VERSION "created by canmatrix"

NS_ :

BS_:

BU_: Matrix

BO_ 1024 Sync_Message_Output_1: 8 Matrix
 SG_ ImageTimestamp_400h : 0|64@1+ (1,0) [0.0|1.84467e+19] "milliseconds" Vector__XXX

BO_ 1025 Sync_Message_Output_2: 8 Matrix
 SG_ SPITimestamp_401h : 0|64@1+ (1,0) [0.0|1.84467e+19] "milliseconds" Vector__XXX

BO_ 1026 Sync_Message_Output_3: 8 Matrix
 SG_ FrameIndex_402h : 0|32@1+ (1,0) [0.0|4294970000.0] "NA" Vector__XXX
 SG_ CameraID_402h : 32|4@1+ (1,0) [0.0|15.0] "enum" Vector__XXX
 SG_ ProtocolMajorVersion_402h : 36|4@1+ (1,0) [0.0|15.0] "NA" Vector__XXX
 SG_ ProtocolMinorVersion_402h : 40|4@1+ (1,0) [0.0|15.0] "NA" Vector__XXX

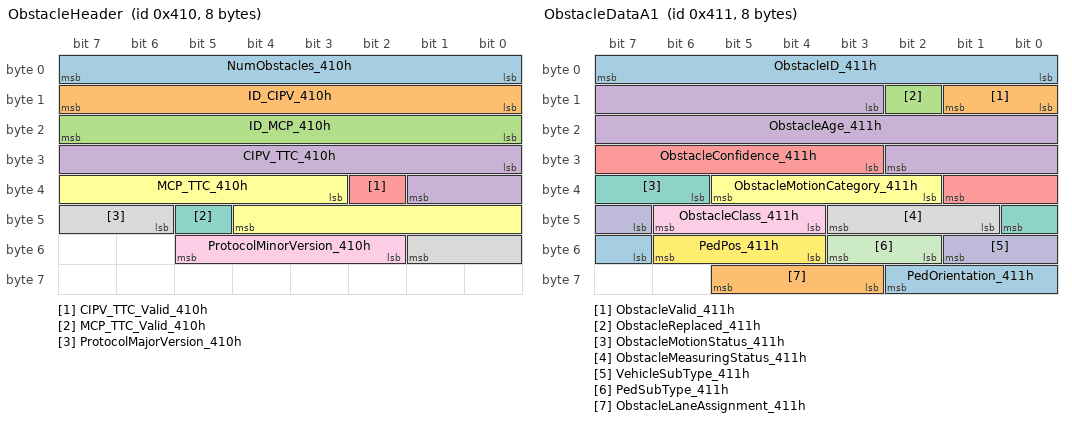
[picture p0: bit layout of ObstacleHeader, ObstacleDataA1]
BO_ 1040 ObstacleHeader: 8 Matrix
 SG_ NumObstacles_410h : 0|8@1+ (1,0) [0.0|20.0] "NA" Vector__XXX
 SG_ ID_CIPV_410h : 8|8@1+ (1,0) [0.0|255.0] "counter" Vector__XXX
 SG_ ID_MCP_410h : 16|8@1+ (1,0) [0.0|255.0] "counter" Vector__XXX
 SG_ CIPV_TTC_410h : 24|10@1+ (0.01,0) [0.0|10.0] "second" Vector__XXX
 SG_ CIPV_TTC_Valid_410h : 34|1@1+ (1,0) [0.0|1.0] "bool" Vector__XXX
 SG_ MCP_TTC_410h : 35|10@1+ (0.01,0) [0.0|10.0] "second" Vector__XXX
 SG_ MCP_TTC_Valid_410h : 45|1@1+ (1,0) [0.0|1.0] "bool" Vector__XXX
 SG_ ProtocolMajorVersion_410h : 46|4@1+ (1,0) [0.0|15.0] "NA" Vector__XXX
 SG_ ProtocolMinorVersion_410h : 50|4@1+ (1,0) [0.0|15.0] "NA" Vector__XXX

BO_ 1041 ObstacleDataA1: 8 Matrix
 SG_ ObstacleID_411h : 0|8@1+ (1,0) [0.0|255.0] "NA" Vector__XXX
 SG_ ObstacleValid_411h : 8|2@1+ (1,0) [0.0|3.0] "bool" Vector__XXX
 SG_ ObstacleReplaced_411h : 10|1@1+ (1,0) [0.0|1.0] "bool" Vector__XXX
 SG_ ObstacleAge_411h : 11|16@1+ (1,0) [0.0|65535.0] "NA" Vector__XXX
 SG_ ObstacleConfidence_411h : 27|7@1+ (1,0) [0.0|100.0] "NA" Vector__XXX
 SG_ ObstacleMotionCategory_411h : 34|4@1+ (1,0) [0.0|15.0] "enum" Vector__XXX
 SG_ ObstacleMotionStatus_411h : 38|3@1+ (1,0) [0.0|7.0] "enum" Vector__XXX
 SG_ ObstacleMeasuringStatus_411h : 41|3@1+ (1,0) [0.0|7.0] "enum" Vector__XXX
 SG_ ObstacleClass_411h : 44|3@1+ (1,0) [0.0|7.0] "enum" Vector__XXX
 SG_ VehicleSubType_411h : 47|3@1+ (1,0) [0.0|7.0] "enum" Vector__XXX
 SG_ PedSubType_411h : 50|2@1+ (1,0) [0.0|3.0] "enum" Vector__XXX
 SG_ PedPos_411h : 52|3@1+ (1,0) [0.0|7.0] "enum" Vector__XXX
 SG_ PedOrientation_411h : 55|4@1+ (1,0) [0.0|15.0] "enum" Vector__XXX
 SG_ ObstacleLaneAssignment_411h : 59|3@1+ (1,0) [0.0|7.0] "enum" Vector__XXX

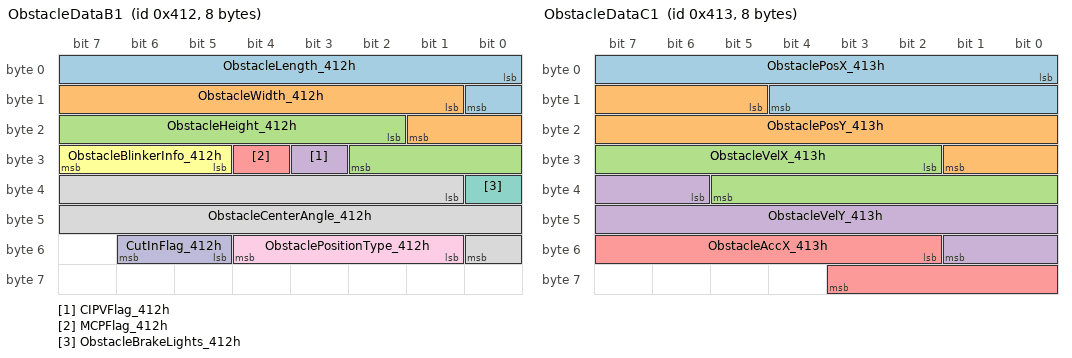
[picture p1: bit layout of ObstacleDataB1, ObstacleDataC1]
BO_ 1042 ObstacleDataB1: 8 Matrix
 SG_ ObstacleLength_412h : 0|9@1+ (0.05,0) [0.0|25.6] "m" Vector__XXX
 SG_ ObstacleWidth_412h : 9|9@1+ (0.02,0) [0.0|10.24] "m" Vector__XXX
 SG_ ObstacleHeight_412h : 18|9@1+ (0.02,0) [0.0|10.24] "m" Vector__XXX
 SG_ CIPVFlag_412h : 27|1@1+ (1,0) [0.0|1.0] "bool" Vector__XXX
 SG_ MCPFlag_412h : 28|1@1+ (1,0) [0.0|1.0] "bool" Vector__XXX
 SG_ ObstacleBlinkerInfo_412h : 29|3@1+ (1,0) [0.0|7.0] "enum" Vector__XXX
 SG_ ObstacleBrakeLights_412h : 32|1@1+ (1,0) [0.0|1.0] "bool" Vector__XXX
 SG_ ObstacleCenterAngle_412h : 33|16@1+ (0.01,-327.68) [-327.68|327.67] "degree" Vector__XXX
 SG_ ObstaclePositionType_412h : 49|4@1+ (1,0) [0.0|15.0] "enum" Vector__XXX
 SG_ CutInFlag_412h : 53|2@1+ (1,0) [0.0|3.0] "bool" Vector__XXX

BO_ 1043 ObstacleDataC1: 8 Matrix
 SG_ ObstaclePosX_413h : 0|13@1+ (0.0625,-250) [-250.0|250.0] "m" Vector__XXX
 SG_ ObstaclePosY_413h : 13|13@1+ (0.0625,-250) [-250.0|250.0] "m" Vector__XXX
 SG_ ObstacleVelX_413h : 26|12@1+ (0.05,-102.4) [-102.4|102.35] "m/sec" Vector__XXX
 SG_ ObstacleVelY_413h : 38|12@1+ (0.05,-50) [-50.0|50.0] "m/sec" Vector__XXX
 SG_ ObstacleAccX_413h : 50|10@1+ (0.03,-14.97) [-14.97|14.97] "m/s^2" Vector__XXX

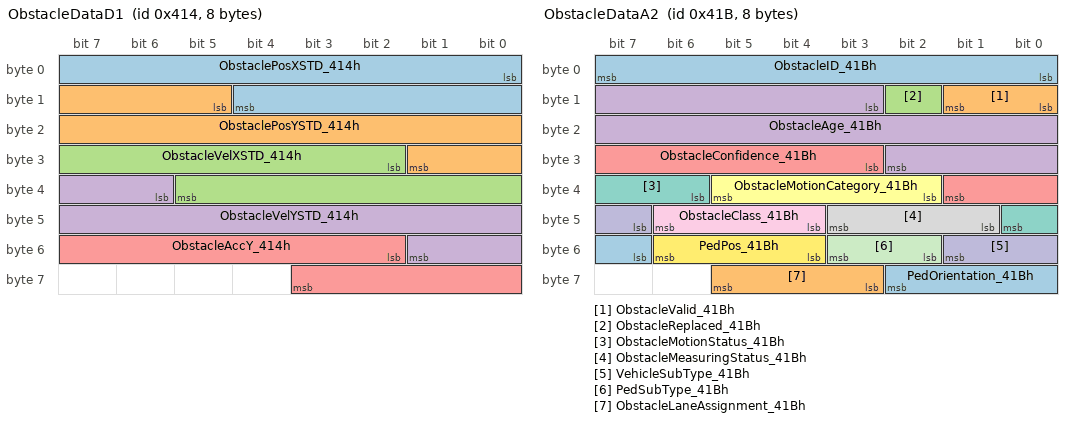
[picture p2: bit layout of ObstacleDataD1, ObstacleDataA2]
BO_ 1044 ObstacleDataD1: 8 Matrix
 SG_ ObstaclePosXSTD_414h : 0|13@1+ (0.0625,0) [0.0|250.0] "m" Vector__XXX
 SG_ ObstaclePosYSTD_414h : 13|13@1+ (0.0625,0) [0.0|250.0] "m" Vector__XXX
 SG_ ObstacleVelXSTD_414h : 26|12@1+ (0.05,0) [0.0|102.35] "m/sec" Vector__XXX
 SG_ ObstacleVelYSTD_414h : 38|12@1+ (0.05,0) [0.0|50.0] "m/sec" Vector__XXX
 SG_ ObstacleAccY_414h : 50|10@1+ (0.03,-14.97) [-14.97|14.97] "m/s^2" Vector__XXX

BO_ 1045 ObstacleDataE1: 8 Matrix
 SG_ ObstacleAngle_415h : 0|16@1+ (0.01,-327.68) [-327.68|327.67] "degree" Vector__XXX
 SG_ ObstacleAngleStd_415h : 16|16@1+ (0.01,0) [0.0|327.67] "degree" Vector__XXX
 SG_ ObstacleVelXAbs_415h : 32|12@1+ (0.05,-102.4) [-102.4|102.35] "m/sec" Vector__XXX
 SG_ ObstacleVelYAbs_415h : 44|12@1+ (0.05,-50) [-50.0|50.0] "m/sec" Vector__XXX

BO_ 1046 ObstacleDataF1: 8 Matrix
 SG_ ObjCornerPointPoxX_416h : 0|13@1+ (0.0625,-250) [-250.0|250.0] "m" Vector__XXX
 SG_ CutInDistance_416h : 13|13@1+ (0.0625,-250) [-250.0|250.0] "m" Vector__XXX
 SG_ ObjCornerPointPoxY_416h : 26|13@1+ (0.0625,-250) [-250.0|250.0] "m" Vector__XXX
 SG_ ObstacleCurvature_416h : 39|15@1+ (1,-9999) [-9999.0|9999.0] "m" Vector__XXX

BO_ 1051 ObstacleDataA2: 8 Matrix
 SG_ ObstacleID_41Bh : 0|8@1+ (1,0) [0.0|255.0] "NA" Vector__XXX
 SG_ ObstacleValid_41Bh : 8|2@1+ (1,0) [0.0|3.0] "bool" Vector__XXX
 SG_ ObstacleReplaced_41Bh : 10|1@1+ (1,0) [0.0|1.0] "bool" Vector__XXX
 SG_ ObstacleAge_41Bh : 11|16@1+ (1,0) [0.0|65535.0] "NA" Vector__XXX
 SG_ ObstacleConfidence_41Bh : 27|7@1+ (1,0) [0.0|100.0] "NA" Vector__XXX
 SG_ ObstacleMotionCategory_41Bh : 34|4@1+ (1,0) [0.0|15.0] "enum" Vector__XXX
 SG_ ObstacleMotionStatus_41Bh : 38|3@1+ (1,0) [0.0|7.0] "enum" Vector__XXX
 SG_ ObstacleMeasuringStatus_41Bh : 41|3@1+ (1,0) [0.0|7.0] "enum" Vector__XXX
 SG_ ObstacleClass_41Bh : 44|3@1+ (1,0) [0.0|7.0] "enum" Vector__XXX
 SG_ VehicleSubType_41Bh : 47|3@1+ (1,0) [0.0|7.0] "enum" Vector__XXX
 SG_ PedSubType_41Bh : 50|2@1+ (1,0) [0.0|3.0] "enum" Vector__XXX
 SG_ PedPos_41Bh : 52|3@1+ (1,0) [0.0|7.0] "enum" Vector__XXX
 SG_ PedOrientation_41Bh : 55|4@1+ (1,0) [0.0|15.0] "enum" Vector__XXX
 SG_ ObstacleLaneAssignment_41Bh : 59|3@1+ (1,0) [0.0|7.0] "enum" Vector__XXX

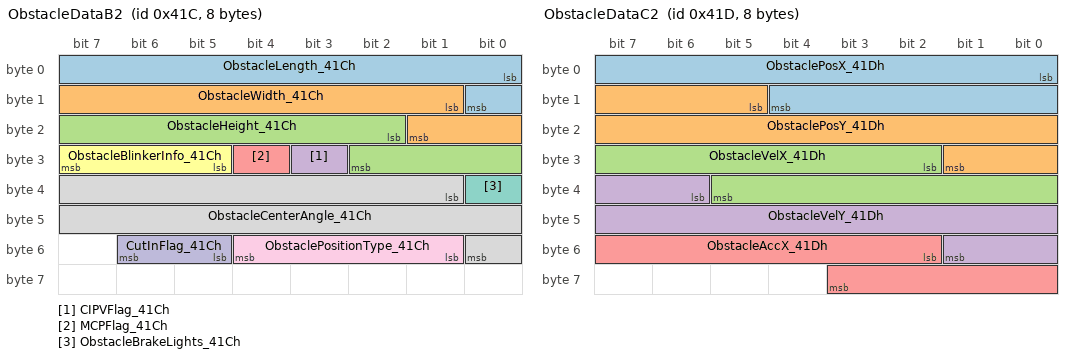
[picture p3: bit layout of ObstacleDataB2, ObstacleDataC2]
BO_ 1052 ObstacleDataB2: 8 Matrix
 SG_ ObstacleLength_41Ch : 0|9@1+ (0.05,0) [0.0|25.6] "m" Vector__XXX
 SG_ ObstacleWidth_41Ch : 9|9@1+ (0.02,0) [0.0|10.24] "m" Vector__XXX
 SG_ ObstacleHeight_41Ch : 18|9@1+ (0.02,0) [0.0|10.24] "m" Vector__XXX
 SG_ CIPVFlag_41Ch : 27|1@1+ (1,0) [0.0|1.0] "bool" Vector__XXX
 SG_ MCPFlag_41Ch : 28|1@1+ (1,0) [0.0|1.0] "bool" Vector__XXX
 SG_ ObstacleBlinkerInfo_41Ch : 29|3@1+ (1,0) [0.0|7.0] "enum" Vector__XXX
 SG_ ObstacleBrakeLights_41Ch : 32|1@1+ (1,0) [0.0|1.0] "bool" Vector__XXX
 SG_ ObstacleCenterAngle_41Ch : 33|16@1+ (0.01,-327.68) [-327.68|327.67] "degree" Vector__XXX
 SG_ ObstaclePositionType_41Ch : 49|4@1+ (1,0) [0.0|15.0] "enum" Vector__XXX
 SG_ CutInFlag_41Ch : 53|2@1+ (1,0) [0.0|3.0] "bool" Vector__XXX

BO_ 1053 ObstacleDataC2: 8 Matrix
 SG_ ObstaclePosX_41Dh : 0|13@1+ (0.0625,-250) [-250.0|250.0] "m" Vector__XXX
 SG_ ObstaclePosY_41Dh : 13|13@1+ (0.0625,-250) [-250.0|250.0] "m" Vector__XXX
 SG_ ObstacleVelX_41Dh : 26|12@1+ (0.05,-102.4) [-102.4|102.35] "m/sec" Vector__XXX
 SG_ ObstacleVelY_41Dh : 38|12@1+ (0.05,-50) [-50.0|50.0] "m/sec" Vector__XXX
 SG_ ObstacleAccX_41Dh : 50|10@1+ (0.03,-14.97) [-14.97|14.97] "m/s^2" Vector__XXX

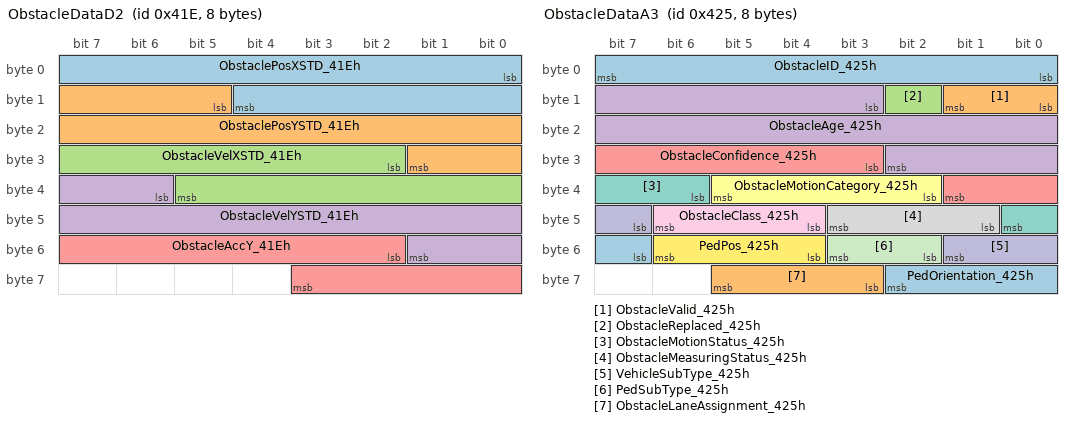
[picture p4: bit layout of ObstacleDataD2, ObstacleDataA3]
BO_ 1054 ObstacleDataD2: 8 Matrix
 SG_ ObstaclePosXSTD_41Eh : 0|13@1+ (0.0625,0) [0.0|250.0] "m" Vector__XXX
 SG_ ObstaclePosYSTD_41Eh : 13|13@1+ (0.0625,0) [0.0|250.0] "m" Vector__XXX
 SG_ ObstacleVelXSTD_41Eh : 26|12@1+ (0.05,0) [0.0|102.35] "m/sec" Vector__XXX
 SG_ ObstacleVelYSTD_41Eh : 38|12@1+ (0.05,0) [0.0|50.0] "m/sec" Vector__XXX
 SG_ ObstacleAccY_41Eh : 50|10@1+ (0.03,-14.97) [-14.97|14.97] "m/s^2" Vector__XXX

BO_ 1055 ObstacleDataE2: 8 Matrix
 SG_ ObstacleAngle_41Fh : 0|16@1+ (0.01,-327.68) [-327.68|327.67] "degree" Vector__XXX
 SG_ ObstacleAngleStd_41Fh : 16|16@1+ (0.01,0) [0.0|327.67] "degree" Vector__XXX
 SG_ ObstacleVelXAbs_41Fh : 32|12@1+ (0.05,-102.4) [-102.4|102.35] "m/sec" Vector__XXX
 SG_ ObstacleVelYAbs_41Fh : 44|12@1+ (0.05,-50) [-50.0|50.0] "m/sec" Vector__XXX

BO_ 1056 ObstacleDataF2: 8 Matrix
 SG_ ObjCornerPointPoxX_420h : 0|13@1+ (0.0625,-250) [-250.0|250.0] "m" Vector__XXX
 SG_ CutInDistance_420h : 13|13@1+ (0.0625,-250) [-250.0|250.0] "m" Vector__XXX
 SG_ ObjCornerPointPoxY_420h : 26|13@1+ (0.0625,-250) [-250.0|250.0] "m" Vector__XXX
 SG_ ObstacleCurvature_420h : 39|15@1+ (1,-9999) [-9999.0|9999.0] "m" Vector__XXX

BO_ 1061 ObstacleDataA3: 8 Matrix
 SG_ ObstacleID_425h : 0|8@1+ (1,0) [0.0|255.0] "NA" Vector__XXX
 SG_ ObstacleValid_425h : 8|2@1+ (1,0) [0.0|3.0] "bool" Vector__XXX
 SG_ ObstacleReplaced_425h : 10|1@1+ (1,0) [0.0|1.0] "bool" Vector__XXX
 SG_ ObstacleAge_425h : 11|16@1+ (1,0) [0.0|65535.0] "NA" Vector__XXX
 SG_ ObstacleConfidence_425h : 27|7@1+ (1,0) [0.0|100.0] "NA" Vector__XXX
 SG_ ObstacleMotionCategory_425h : 34|4@1+ (1,0) [0.0|15.0] "enum" Vector__XXX
 SG_ ObstacleMotionStatus_425h : 38|3@1+ (1,0) [0.0|7.0] "enum" Vector__XXX
 SG_ ObstacleMeasuringStatus_425h : 41|3@1+ (1,0) [0.0|7.0] "enum" Vector__XXX
 SG_ ObstacleClass_425h : 44|3@1+ (1,0) [0.0|7.0] "enum" Vector__XXX
 SG_ VehicleSubType_425h : 47|3@1+ (1,0) [0.0|7.0] "enum" Vector__XXX
 SG_ PedSubType_425h : 50|2@1+ (1,0) [0.0|3.0] "enum" Vector__XXX
 SG_ PedPos_425h : 52|3@1+ (1,0) [0.0|7.0] "enum" Vector__XXX
 SG_ PedOrientation_425h : 55|4@1+ (1,0) [0.0|15.0] "enum" Vector__XXX
 SG_ ObstacleLaneAssignment_425h : 59|3@1+ (1,0) [0.0|7.0] "enum" Vector__XXX

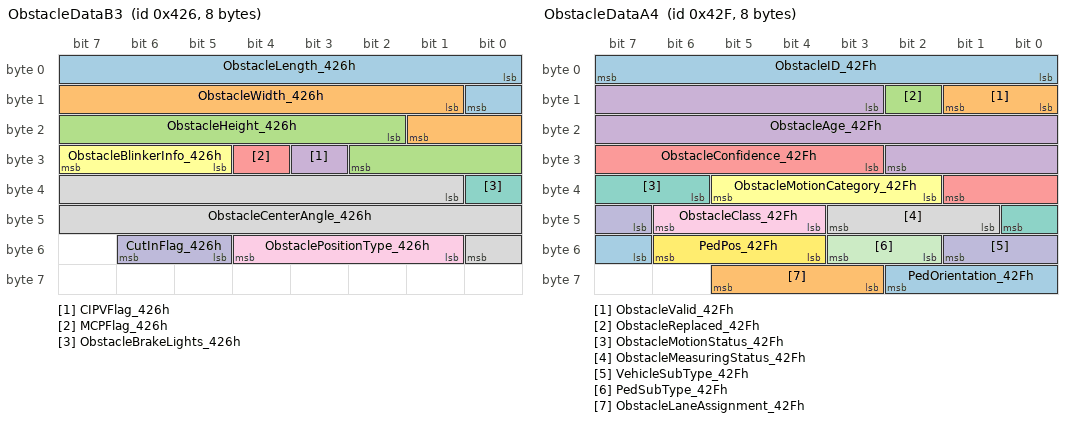
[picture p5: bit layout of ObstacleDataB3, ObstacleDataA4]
BO_ 1062 ObstacleDataB3: 8 Matrix
 SG_ ObstacleLength_426h : 0|9@1+ (0.05,0) [0.0|25.6] "m" Vector__XXX
 SG_ ObstacleWidth_426h : 9|9@1+ (0.02,0) [0.0|10.24] "m" Vector__XXX
 SG_ ObstacleHeight_426h : 18|9@1+ (0.02,0) [0.0|10.24] "m" Vector__XXX
 SG_ CIPVFlag_426h : 27|1@1+ (1,0) [0.0|1.0] "bool" Vector__XXX
 SG_ MCPFlag_426h : 28|1@1+ (1,0) [0.0|1.0] "bool" Vector__XXX
 SG_ ObstacleBlinkerInfo_426h : 29|3@1+ (1,0) [0.0|7.0] "enum" Vector__XXX
 SG_ ObstacleBrakeLights_426h : 32|1@1+ (1,0) [0.0|1.0] "bool" Vector__XXX
 SG_ ObstacleCenterAngle_426h : 33|16@1+ (0.01,-327.68) [-327.68|327.67] "degree" Vector__XXX
 SG_ ObstaclePositionType_426h : 49|4@1+ (1,0) [0.0|15.0] "enum" Vector__XXX
 SG_ CutInFlag_426h : 53|2@1+ (1,0) [0.0|3.0] "bool" Vector__XXX

BO_ 1063 ObstacleDataC3: 8 Matrix
 SG_ ObstaclePosX_427h : 0|13@1+ (0.0625,-250) [-250.0|250.0] "m" Vector__XXX
 SG_ ObstaclePosY_427h : 13|13@1+ (0.0625,-250) [-250.0|250.0] "m" Vector__XXX
 SG_ ObstacleVelX_427h : 26|12@1+ (0.05,-102.4) [-102.4|102.35] "m/sec" Vector__XXX
 SG_ ObstacleVelY_427h : 38|12@1+ (0.05,-50) [-50.0|50.0] "m/sec" Vector__XXX
 SG_ ObstacleAccX_427h : 50|10@1+ (0.03,-14.97) [-14.97|14.97] "m/s^2" Vector__XXX

BO_ 1064 ObstacleDataD3: 8 Matrix
 SG_ ObstaclePosXSTD_428h : 0|13@1+ (0.0625,0) [0.0|250.0] "m" Vector__XXX
 SG_ ObstaclePosYSTD_428h : 13|13@1+ (0.0625,0) [0.0|250.0] "m" Vector__XXX
 SG_ ObstacleVelXSTD_428h : 26|12@1+ (0.05,0) [0.0|102.35] "m/sec" Vector__XXX
 SG_ ObstacleVelYSTD_428h : 38|12@1+ (0.05,0) [0.0|50.0] "m/sec" Vector__XXX
 SG_ ObstacleAccY_428h : 50|10@1+ (0.03,-14.97) [-14.97|14.97] "m/s^2" Vector__XXX

BO_ 1065 ObstacleDataE3: 8 Matrix
 SG_ ObstacleAngle_429h : 0|16@1+ (0.01,-327.68) [-327.68|327.67] "degree" Vector__XXX
 SG_ ObstacleAngleStd_429h : 16|16@1+ (0.01,0) [0.0|327.67] "degree" Vector__XXX
 SG_ ObstacleVelXAbs_429h : 32|12@1+ (0.05,-102.4) [-102.4|102.35] "m/sec" Vector__XXX
 SG_ ObstacleVelYAbs_429h : 44|12@1+ (0.05,-50) [-50.0|50.0] "m/sec" Vector__XXX

BO_ 1066 ObstacleDataF3: 8 Matrix
 SG_ ObjCornerPointPoxX_42Ah : 0|13@1+ (0.0625,-250) [-250.0|250.0] "m" Vector__XXX
 SG_ CutInDistance_42Ah : 13|13@1+ (0.0625,-250) [-250.0|250.0] "m" Vector__XXX
 SG_ ObjCornerPointPoxY_42Ah : 26|13@1+ (0.0625,-250) [-250.0|250.0] "m" Vector__XXX
 SG_ ObstacleCurvature_42Ah : 39|15@1+ (1,-9999) [-9999.0|9999.0] "m" Vector__XXX

BO_ 1071 ObstacleDataA4: 8 Matrix
 SG_ ObstacleID_42Fh : 0|8@1+ (1,0) [0.0|255.0] "NA" Vector__XXX
 SG_ ObstacleValid_42Fh : 8|2@1+ (1,0) [0.0|3.0] "bool" Vector__XXX
 SG_ ObstacleReplaced_42Fh : 10|1@1+ (1,0) [0.0|1.0] "bool" Vector__XXX
 SG_ ObstacleAge_42Fh : 11|16@1+ (1,0) [0.0|65535.0] "NA" Vector__XXX
 SG_ ObstacleConfidence_42Fh : 27|7@1+ (1,0) [0.0|100.0] "NA" Vector__XXX
 SG_ ObstacleMotionCategory_42Fh : 34|4@1+ (1,0) [0.0|15.0] "enum" Vector__XXX
 SG_ ObstacleMotionStatus_42Fh : 38|3@1+ (1,0) [0.0|7.0] "enum" Vector__XXX
 SG_ ObstacleMeasuringStatus_42Fh : 41|3@1+ (1,0) [0.0|7.0] "enum" Vector__XXX
 SG_ ObstacleClass_42Fh : 44|3@1+ (1,0) [0.0|7.0] "enum" Vector__XXX
 SG_ VehicleSubType_42Fh : 47|3@1+ (1,0) [0.0|7.0] "enum" Vector__XXX
 SG_ PedSubType_42Fh : 50|2@1+ (1,0) [0.0|3.0] "enum" Vector__XXX
 SG_ PedPos_42Fh : 52|3@1+ (1,0) [0.0|7.0] "enum" Vector__XXX
 SG_ PedOrientation_42Fh : 55|4@1+ (1,0) [0.0|15.0] "enum" Vector__XXX
 SG_ ObstacleLaneAssignment_42Fh : 59|3@1+ (1,0) [0.0|7.0] "enum" Vector__XXX

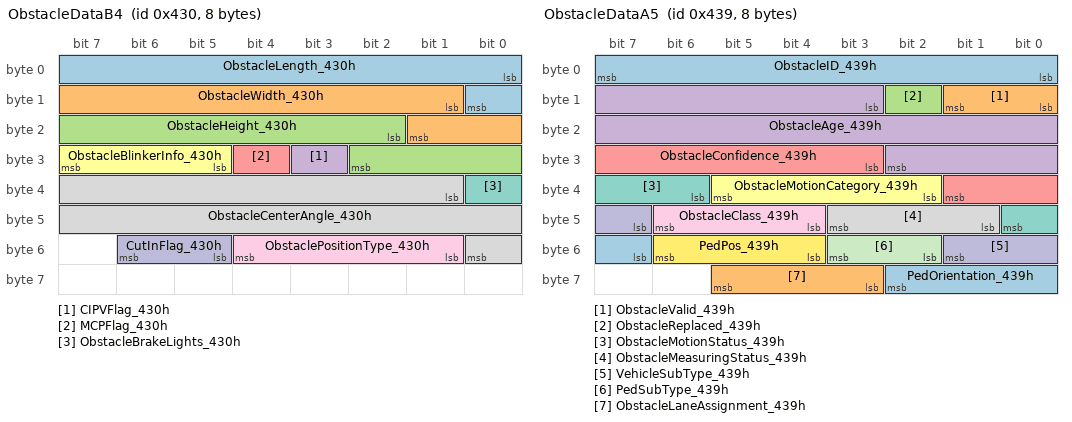
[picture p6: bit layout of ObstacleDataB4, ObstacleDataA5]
BO_ 1072 ObstacleDataB4: 8 Matrix
 SG_ ObstacleLength_430h : 0|9@1+ (0.05,0) [0.0|25.6] "m" Vector__XXX
 SG_ ObstacleWidth_430h : 9|9@1+ (0.02,0) [0.0|10.24] "m" Vector__XXX
 SG_ ObstacleHeight_430h : 18|9@1+ (0.02,0) [0.0|10.24] "m" Vector__XXX
 SG_ CIPVFlag_430h : 27|1@1+ (1,0) [0.0|1.0] "bool" Vector__XXX
 SG_ MCPFlag_430h : 28|1@1+ (1,0) [0.0|1.0] "bool" Vector__XXX
 SG_ ObstacleBlinkerInfo_430h : 29|3@1+ (1,0) [0.0|7.0] "enum" Vector__XXX
 SG_ ObstacleBrakeLights_430h : 32|1@1+ (1,0) [0.0|1.0] "bool" Vector__XXX
 SG_ ObstacleCenterAngle_430h : 33|16@1+ (0.01,-327.68) [-327.68|327.67] "degree" Vector__XXX
 SG_ ObstaclePositionType_430h : 49|4@1+ (1,0) [0.0|15.0] "enum" Vector__XXX
 SG_ CutInFlag_430h : 53|2@1+ (1,0) [0.0|3.0] "bool" Vector__XXX

BO_ 1073 ObstacleDataC4: 8 Matrix
 SG_ ObstaclePosX_431h : 0|13@1+ (0.0625,-250) [-250.0|250.0] "m" Vector__XXX
 SG_ ObstaclePosY_431h : 13|13@1+ (0.0625,-250) [-250.0|250.0] "m" Vector__XXX
 SG_ ObstacleVelX_431h : 26|12@1+ (0.05,-102.4) [-102.4|102.35] "m/sec" Vector__XXX
 SG_ ObstacleVelY_431h : 38|12@1+ (0.05,-50) [-50.0|50.0] "m/sec" Vector__XXX
 SG_ ObstacleAccX_431h : 50|10@1+ (0.03,-14.97) [-14.97|14.97] "m/s^2" Vector__XXX

BO_ 1074 ObstacleDataD4: 8 Matrix
 SG_ ObstaclePosXSTD_432h : 0|13@1+ (0.0625,0) [0.0|250.0] "m" Vector__XXX
 SG_ ObstaclePosYSTD_432h : 13|13@1+ (0.0625,0) [0.0|250.0] "m" Vector__XXX
 SG_ ObstacleVelXSTD_432h : 26|12@1+ (0.05,0) [0.0|102.35] "m/sec" Vector__XXX
 SG_ ObstacleVelYSTD_432h : 38|12@1+ (0.05,0) [0.0|50.0] "m/sec" Vector__XXX
 SG_ ObstacleAccY_432h : 50|10@1+ (0.03,-14.97) [-14.97|14.97] "m/s^2" Vector__XXX

BO_ 1075 ObstacleDataE4: 8 Matrix
 SG_ ObstacleAngle_433h : 0|16@1+ (0.01,-327.68) [-327.68|327.67] "degree" Vector__XXX
 SG_ ObstacleAngleStd_433h : 16|16@1+ (0.01,0) [0.0|327.67] "degree" Vector__XXX
 SG_ ObstacleVelXAbs_433h : 32|12@1+ (0.05,-102.4) [-102.4|102.35] "m/sec" Vector__XXX
 SG_ ObstacleVelYAbs_433h : 44|12@1+ (0.05,-50) [-50.0|50.0] "m/sec" Vector__XXX

BO_ 1076 ObstacleDataF4: 8 Matrix
 SG_ ObjCornerPointPoxX_434h : 0|13@1+ (0.0625,-250) [-250.0|250.0] "m" Vector__XXX
 SG_ CutInDistance_434h : 13|13@1+ (0.0625,-250) [-250.0|250.0] "m" Vector__XXX
 SG_ ObjCornerPointPoxY_434h : 26|13@1+ (0.0625,-250) [-250.0|250.0] "m" Vector__XXX
 SG_ ObstacleCurvature_434h : 39|15@1+ (1,-9999) [-9999.0|9999.0] "m" Vector__XXX

BO_ 1081 ObstacleDataA5: 8 Matrix
 SG_ ObstacleID_439h : 0|8@1+ (1,0) [0.0|255.0] "NA" Vector__XXX
 SG_ ObstacleValid_439h : 8|2@1+ (1,0) [0.0|3.0] "bool" Vector__XXX
 SG_ ObstacleReplaced_439h : 10|1@1+ (1,0) [0.0|1.0] "bool" Vector__XXX
 SG_ ObstacleAge_439h : 11|16@1+ (1,0) [0.0|65535.0] "NA" Vector__XXX
 SG_ ObstacleConfidence_439h : 27|7@1+ (1,0) [0.0|100.0] "NA" Vector__XXX
 SG_ ObstacleMotionCategory_439h : 34|4@1+ (1,0) [0.0|15.0] "enum" Vector__XXX
 SG_ ObstacleMotionStatus_439h : 38|3@1+ (1,0) [0.0|7.0] "enum" Vector__XXX
 SG_ ObstacleMeasuringStatus_439h : 41|3@1+ (1,0) [0.0|7.0] "enum" Vector__XXX
 SG_ ObstacleClass_439h : 44|3@1+ (1,0) [0.0|7.0] "enum" Vector__XXX
 SG_ VehicleSubType_439h : 47|3@1+ (1,0) [0.0|7.0] "enum" Vector__XXX
 SG_ PedSubType_439h : 50|2@1+ (1,0) [0.0|3.0] "enum" Vector__XXX
 SG_ PedPos_439h : 52|3@1+ (1,0) [0.0|7.0] "enum" Vector__XXX
 SG_ PedOrientation_439h : 55|4@1+ (1,0) [0.0|15.0] "enum" Vector__XXX
 SG_ ObstacleLaneAssignment_439h : 59|3@1+ (1,0) [0.0|7.0] "enum" Vector__XXX

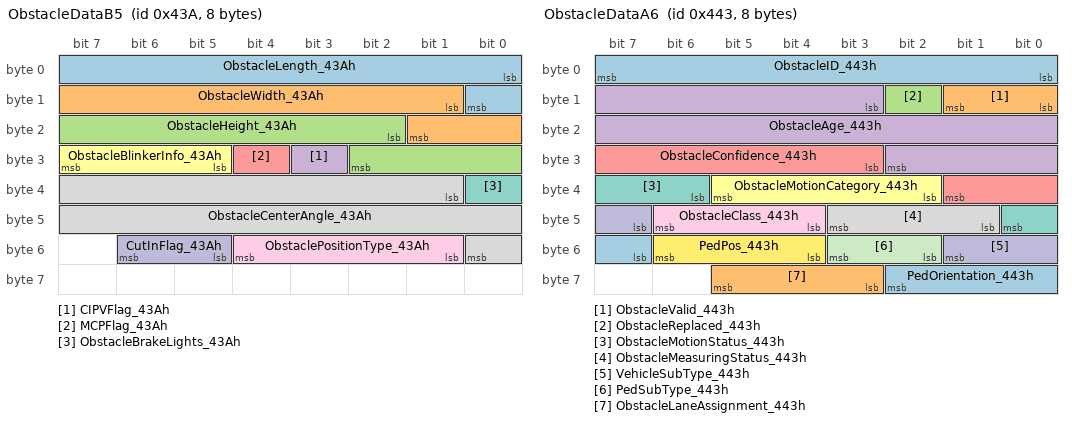
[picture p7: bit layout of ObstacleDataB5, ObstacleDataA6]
BO_ 1082 ObstacleDataB5: 8 Matrix
 SG_ ObstacleLength_43Ah : 0|9@1+ (0.05,0) [0.0|25.6] "m" Vector__XXX
 SG_ ObstacleWidth_43Ah : 9|9@1+ (0.02,0) [0.0|10.24] "m" Vector__XXX
 SG_ ObstacleHeight_43Ah : 18|9@1+ (0.02,0) [0.0|10.24] "m" Vector__XXX
 SG_ CIPVFlag_43Ah : 27|1@1+ (1,0) [0.0|1.0] "bool" Vector__XXX
 SG_ MCPFlag_43Ah : 28|1@1+ (1,0) [0.0|1.0] "bool" Vector__XXX
 SG_ ObstacleBlinkerInfo_43Ah : 29|3@1+ (1,0) [0.0|7.0] "enum" Vector__XXX
 SG_ ObstacleBrakeLights_43Ah : 32|1@1+ (1,0) [0.0|1.0] "bool" Vector__XXX
 SG_ ObstacleCenterAngle_43Ah : 33|16@1+ (0.01,-327.68) [-327.68|327.67] "degree" Vector__XXX
 SG_ ObstaclePositionType_43Ah : 49|4@1+ (1,0) [0.0|15.0] "enum" Vector__XXX
 SG_ CutInFlag_43Ah : 53|2@1+ (1,0) [0.0|3.0] "bool" Vector__XXX

BO_ 1083 ObstacleDataC5: 8 Matrix
 SG_ ObstaclePosX_43Bh : 0|13@1+ (0.0625,-250) [-250.0|250.0] "m" Vector__XXX
 SG_ ObstaclePosY_43Bh : 13|13@1+ (0.0625,-250) [-250.0|250.0] "m" Vector__XXX
 SG_ ObstacleVelX_43Bh : 26|12@1+ (0.05,-102.4) [-102.4|102.35] "m/sec" Vector__XXX
 SG_ ObstacleVelY_43Bh : 38|12@1+ (0.05,-50) [-50.0|50.0] "m/sec" Vector__XXX
 SG_ ObstacleAccX_43Bh : 50|10@1+ (0.03,-14.97) [-14.97|14.97] "m/s^2" Vector__XXX

BO_ 1084 ObstacleDataD5: 8 Matrix
 SG_ ObstaclePosXSTD_43Ch : 0|13@1+ (0.0625,0) [0.0|250.0] "m" Vector__XXX
 SG_ ObstaclePosYSTD_43Ch : 13|13@1+ (0.0625,0) [0.0|250.0] "m" Vector__XXX
 SG_ ObstacleVelXSTD_43Ch : 26|12@1+ (0.05,0) [0.0|102.35] "m/sec" Vector__XXX
 SG_ ObstacleVelYSTD_43Ch : 38|12@1+ (0.05,0) [0.0|50.0] "m/sec" Vector__XXX
 SG_ ObstacleAccY_43Ch : 50|10@1+ (0.03,-14.97) [-14.97|14.97] "m/s^2" Vector__XXX

BO_ 1085 ObstacleDataE5: 8 Matrix
 SG_ ObstacleAngle_43Dh : 0|16@1+ (0.01,-327.68) [-327.68|327.67] "degree" Vector__XXX
 SG_ ObstacleAngleStd_43Dh : 16|16@1+ (0.01,0) [0.0|327.67] "degree" Vector__XXX
 SG_ ObstacleVelXAbs_43Dh : 32|12@1+ (0.05,-102.4) [-102.4|102.35] "m/sec" Vector__XXX
 SG_ ObstacleVelYAbs_43Dh : 44|12@1+ (0.05,-50) [-50.0|50.0] "m/sec" Vector__XXX

BO_ 1086 ObstacleDataF5: 8 Matrix
 SG_ ObjCornerPointPoxX_43Eh : 0|13@1+ (0.0625,-250) [-250.0|250.0] "m" Vector__XXX
 SG_ CutInDistance_43Eh : 13|13@1+ (0.0625,-250) [-250.0|250.0] "m" Vector__XXX
 SG_ ObjCornerPointPoxY_43Eh : 26|13@1+ (0.0625,-250) [-250.0|250.0] "m" Vector__XXX
 SG_ ObstacleCurvature_43Eh : 39|15@1+ (1,-9999) [-9999.0|9999.0] "m" Vector__XXX

BO_ 1091 ObstacleDataA6: 8 Matrix
 SG_ ObstacleID_443h : 0|8@1+ (1,0) [0.0|255.0] "NA" Vector__XXX
 SG_ ObstacleValid_443h : 8|2@1+ (1,0) [0.0|3.0] "bool" Vector__XXX
 SG_ ObstacleReplaced_443h : 10|1@1+ (1,0) [0.0|1.0] "bool" Vector__XXX
 SG_ ObstacleAge_443h : 11|16@1+ (1,0) [0.0|65535.0] "NA" Vector__XXX
 SG_ ObstacleConfidence_443h : 27|7@1+ (1,0) [0.0|100.0] "NA" Vector__XXX
 SG_ ObstacleMotionCategory_443h : 34|4@1+ (1,0) [0.0|15.0] "enum" Vector__XXX
 SG_ ObstacleMotionStatus_443h : 38|3@1+ (1,0) [0.0|7.0] "enum" Vector__XXX
 SG_ ObstacleMeasuringStatus_443h : 41|3@1+ (1,0) [0.0|7.0] "enum" Vector__XXX
 SG_ ObstacleClass_443h : 44|3@1+ (1,0) [0.0|7.0] "enum" Vector__XXX
 SG_ VehicleSubType_443h : 47|3@1+ (1,0) [0.0|7.0] "enum" Vector__XXX
 SG_ PedSubType_443h : 50|2@1+ (1,0) [0.0|3.0] "enum" Vector__XXX
 SG_ PedPos_443h : 52|3@1+ (1,0) [0.0|7.0] "enum" Vector__XXX
 SG_ PedOrientation_443h : 55|4@1+ (1,0) [0.0|15.0] "enum" Vector__XXX
 SG_ ObstacleLaneAssignment_443h : 59|3@1+ (1,0) [0.0|7.0] "enum" Vector__XXX

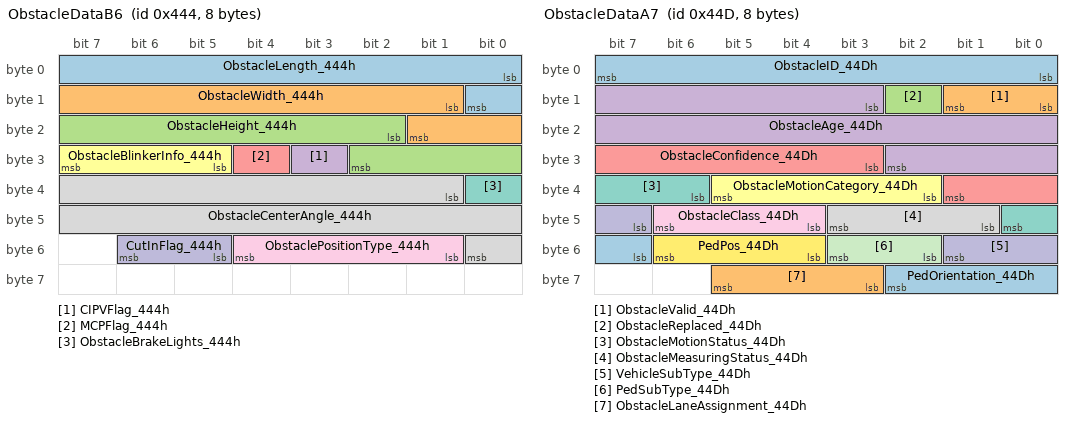
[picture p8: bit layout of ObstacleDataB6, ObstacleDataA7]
BO_ 1092 ObstacleDataB6: 8 Matrix
 SG_ ObstacleLength_444h : 0|9@1+ (0.05,0) [0.0|25.6] "m" Vector__XXX
 SG_ ObstacleWidth_444h : 9|9@1+ (0.02,0) [0.0|10.24] "m" Vector__XXX
 SG_ ObstacleHeight_444h : 18|9@1+ (0.02,0) [0.0|10.24] "m" Vector__XXX
 SG_ CIPVFlag_444h : 27|1@1+ (1,0) [0.0|1.0] "bool" Vector__XXX
 SG_ MCPFlag_444h : 28|1@1+ (1,0) [0.0|1.0] "bool" Vector__XXX
 SG_ ObstacleBlinkerInfo_444h : 29|3@1+ (1,0) [0.0|7.0] "enum" Vector__XXX
 SG_ ObstacleBrakeLights_444h : 32|1@1+ (1,0) [0.0|1.0] "bool" Vector__XXX
 SG_ ObstacleCenterAngle_444h : 33|16@1+ (0.01,-327.68) [-327.68|327.67] "degree" Vector__XXX
 SG_ ObstaclePositionType_444h : 49|4@1+ (1,0) [0.0|15.0] "enum" Vector__XXX
 SG_ CutInFlag_444h : 53|2@1+ (1,0) [0.0|3.0] "bool" Vector__XXX

BO_ 1093 ObstacleDataC6: 8 Matrix
 SG_ ObstaclePosX_445h : 0|13@1+ (0.0625,-250) [-250.0|250.0] "m" Vector__XXX
 SG_ ObstaclePosY_445h : 13|13@1+ (0.0625,-250) [-250.0|250.0] "m" Vector__XXX
 SG_ ObstacleVelX_445h : 26|12@1+ (0.05,-102.4) [-102.4|102.35] "m/sec" Vector__XXX
 SG_ ObstacleVelY_445h : 38|12@1+ (0.05,-50) [-50.0|50.0] "m/sec" Vector__XXX
 SG_ ObstacleAccX_445h : 50|10@1+ (0.03,-14.97) [-14.97|14.97] "m/s^2" Vector__XXX

BO_ 1094 ObstacleDataD6: 8 Matrix
 SG_ ObstaclePosXSTD_446h : 0|13@1+ (0.0625,0) [0.0|250.0] "m" Vector__XXX
 SG_ ObstaclePosYSTD_446h : 13|13@1+ (0.0625,0) [0.0|250.0] "m" Vector__XXX
 SG_ ObstacleVelXSTD_446h : 26|12@1+ (0.05,0) [0.0|102.35] "m/sec" Vector__XXX
 SG_ ObstacleVelYSTD_446h : 38|12@1+ (0.05,0) [0.0|50.0] "m/sec" Vector__XXX
 SG_ ObstacleAccY_446h : 50|10@1+ (0.03,-14.97) [-14.97|14.97] "m/s^2" Vector__XXX

BO_ 1095 ObstacleDataE6: 8 Matrix
 SG_ ObstacleAngle_447h : 0|16@1+ (0.01,-327.68) [-327.68|327.67] "degree" Vector__XXX
 SG_ ObstacleAngleStd_447h : 16|16@1+ (0.01,0) [0.0|327.67] "degree" Vector__XXX
 SG_ ObstacleVelXAbs_447h : 32|12@1+ (0.05,-102.4) [-102.4|102.35] "m/sec" Vector__XXX
 SG_ ObstacleVelYAbs_447h : 44|12@1+ (0.05,-50) [-50.0|50.0] "m/sec" Vector__XXX

BO_ 1096 ObstacleDataF6: 8 Matrix
 SG_ ObjCornerPointPoxX_448h : 0|13@1+ (0.0625,-250) [-250.0|250.0] "m" Vector__XXX
 SG_ CutInDistance_448h : 13|13@1+ (0.0625,-250) [-250.0|250.0] "m" Vector__XXX
 SG_ ObjCornerPointPoxY_448h : 26|13@1+ (0.0625,-250) [-250.0|250.0] "m" Vector__XXX
 SG_ ObstacleCurvature_448h : 39|15@1+ (1,-9999) [-9999.0|9999.0] "m" Vector__XXX

BO_ 1101 ObstacleDataA7: 8 Matrix
 SG_ ObstacleID_44Dh : 0|8@1+ (1,0) [0.0|255.0] "NA" Vector__XXX
 SG_ ObstacleValid_44Dh : 8|2@1+ (1,0) [0.0|3.0] "bool" Vector__XXX
 SG_ ObstacleReplaced_44Dh : 10|1@1+ (1,0) [0.0|1.0] "bool" Vector__XXX
 SG_ ObstacleAge_44Dh : 11|16@1+ (1,0) [0.0|65535.0] "NA" Vector__XXX
 SG_ ObstacleConfidence_44Dh : 27|7@1+ (1,0) [0.0|100.0] "NA" Vector__XXX
 SG_ ObstacleMotionCategory_44Dh : 34|4@1+ (1,0) [0.0|15.0] "enum" Vector__XXX
 SG_ ObstacleMotionStatus_44Dh : 38|3@1+ (1,0) [0.0|7.0] "enum" Vector__XXX
 SG_ ObstacleMeasuringStatus_44Dh : 41|3@1+ (1,0) [0.0|7.0] "enum" Vector__XXX
 SG_ ObstacleClass_44Dh : 44|3@1+ (1,0) [0.0|7.0] "enum" Vector__XXX
 SG_ VehicleSubType_44Dh : 47|3@1+ (1,0) [0.0|7.0] "enum" Vector__XXX
 SG_ PedSubType_44Dh : 50|2@1+ (1,0) [0.0|3.0] "enum" Vector__XXX
 SG_ PedPos_44Dh : 52|3@1+ (1,0) [0.0|7.0] "enum" Vector__XXX
 SG_ PedOrientation_44Dh : 55|4@1+ (1,0) [0.0|15.0] "enum" Vector__XXX
 SG_ ObstacleLaneAssignment_44Dh : 59|3@1+ (1,0) [0.0|7.0] "enum" Vector__XXX

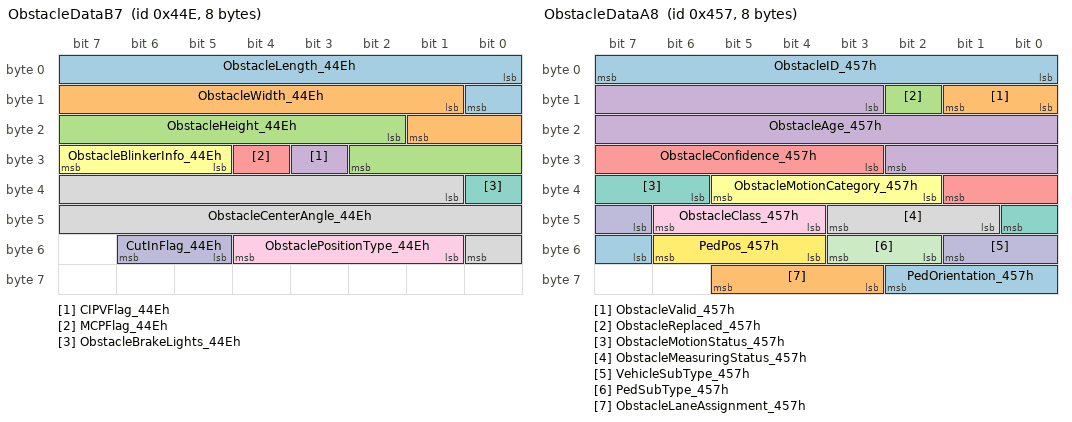
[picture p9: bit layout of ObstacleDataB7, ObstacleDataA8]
BO_ 1102 ObstacleDataB7: 8 Matrix
 SG_ ObstacleLength_44Eh : 0|9@1+ (0.05,0) [0.0|25.6] "m" Vector__XXX
 SG_ ObstacleWidth_44Eh : 9|9@1+ (0.02,0) [0.0|10.24] "m" Vector__XXX
 SG_ ObstacleHeight_44Eh : 18|9@1+ (0.02,0) [0.0|10.24] "m" Vector__XXX
 SG_ CIPVFlag_44Eh : 27|1@1+ (1,0) [0.0|1.0] "bool" Vector__XXX
 SG_ MCPFlag_44Eh : 28|1@1+ (1,0) [0.0|1.0] "bool" Vector__XXX
 SG_ ObstacleBlinkerInfo_44Eh : 29|3@1+ (1,0) [0.0|7.0] "enum" Vector__XXX
 SG_ ObstacleBrakeLights_44Eh : 32|1@1+ (1,0) [0.0|1.0] "bool" Vector__XXX
 SG_ ObstacleCenterAngle_44Eh : 33|16@1+ (0.01,-327.68) [-327.68|327.67] "degree" Vector__XXX
 SG_ ObstaclePositionType_44Eh : 49|4@1+ (1,0) [0.0|15.0] "enum" Vector__XXX
 SG_ CutInFlag_44Eh : 53|2@1+ (1,0) [0.0|3.0] "bool" Vector__XXX

BO_ 1103 ObstacleDataC7: 8 Matrix
 SG_ ObstaclePosX_44Fh : 0|13@1+ (0.0625,-250) [-250.0|250.0] "m" Vector__XXX
 SG_ ObstaclePosY_44Fh : 13|13@1+ (0.0625,-250) [-250.0|250.0] "m" Vector__XXX
 SG_ ObstacleVelX_44Fh : 26|12@1+ (0.05,-102.4) [-102.4|102.35] "m/sec" Vector__XXX
 SG_ ObstacleVelY_44Fh : 38|12@1+ (0.05,-50) [-50.0|50.0] "m/sec" Vector__XXX
 SG_ ObstacleAccX_44Fh : 50|10@1+ (0.03,-14.97) [-14.97|14.97] "m/s^2" Vector__XXX

BO_ 1104 ObstacleDataD7: 8 Matrix
 SG_ ObstaclePosXSTD_450h : 0|13@1+ (0.0625,0) [0.0|250.0] "m" Vector__XXX
 SG_ ObstaclePosYSTD_450h : 13|13@1+ (0.0625,0) [0.0|250.0] "m" Vector__XXX
 SG_ ObstacleVelXSTD_450h : 26|12@1+ (0.05,0) [0.0|102.35] "m/sec" Vector__XXX
 SG_ ObstacleVelYSTD_450h : 38|12@1+ (0.05,0) [0.0|50.0] "m/sec" Vector__XXX
 SG_ ObstacleAccY_450h : 50|10@1+ (0.03,-14.97) [-14.97|14.97] "m/s^2" Vector__XXX

BO_ 1105 ObstacleDataE7: 8 Matrix
 SG_ ObstacleAngle_451h : 0|16@1+ (0.01,-327.68) [-327.68|327.67] "degree" Vector__XXX
 SG_ ObstacleAngleStd_451h : 16|16@1+ (0.01,0) [0.0|327.67] "degree" Vector__XXX
 SG_ ObstacleVelXAbs_451h : 32|12@1+ (0.05,-102.4) [-102.4|102.35] "m/sec" Vector__XXX
 SG_ ObstacleVelYAbs_451h : 44|12@1+ (0.05,-50) [-50.0|50.0] "m/sec" Vector__XXX

BO_ 1106 ObstacleDataF7: 8 Matrix
 SG_ ObjCornerPointPoxX_452h : 0|13@1+ (0.0625,-250) [-250.0|250.0] "m" Vector__XXX
 SG_ CutInDistance_452h : 13|13@1+ (0.0625,-250) [-250.0|250.0] "m" Vector__XXX
 SG_ ObjCornerPointPoxY_452h : 26|13@1+ (0.0625,-250) [-250.0|250.0] "m" Vector__XXX
 SG_ ObstacleCurvature_452h : 39|15@1+ (1,-9999) [-9999.0|9999.0] "m" Vector__XXX

BO_ 1111 ObstacleDataA8: 8 Matrix
 SG_ ObstacleID_457h : 0|8@1+ (1,0) [0.0|255.0] "NA" Vector__XXX
 SG_ ObstacleValid_457h : 8|2@1+ (1,0) [0.0|3.0] "bool" Vector__XXX
 SG_ ObstacleReplaced_457h : 10|1@1+ (1,0) [0.0|1.0] "bool" Vector__XXX
 SG_ ObstacleAge_457h : 11|16@1+ (1,0) [0.0|65535.0] "NA" Vector__XXX
 SG_ ObstacleConfidence_457h : 27|7@1+ (1,0) [0.0|100.0] "NA" Vector__XXX
 SG_ ObstacleMotionCategory_457h : 34|4@1+ (1,0) [0.0|15.0] "enum" Vector__XXX
 SG_ ObstacleMotionStatus_457h : 38|3@1+ (1,0) [0.0|7.0] "enum" Vector__XXX
 SG_ ObstacleMeasuringStatus_457h : 41|3@1+ (1,0) [0.0|7.0] "enum" Vector__XXX
 SG_ ObstacleClass_457h : 44|3@1+ (1,0) [0.0|7.0] "enum" Vector__XXX
 SG_ VehicleSubType_457h : 47|3@1+ (1,0) [0.0|7.0] "enum" Vector__XXX
 SG_ PedSubType_457h : 50|2@1+ (1,0) [0.0|3.0] "enum" Vector__XXX
 SG_ PedPos_457h : 52|3@1+ (1,0) [0.0|7.0] "enum" Vector__XXX
 SG_ PedOrientation_457h : 55|4@1+ (1,0) [0.0|15.0] "enum" Vector__XXX
 SG_ ObstacleLaneAssignment_457h : 59|3@1+ (1,0) [0.0|7.0] "enum" Vector__XXX

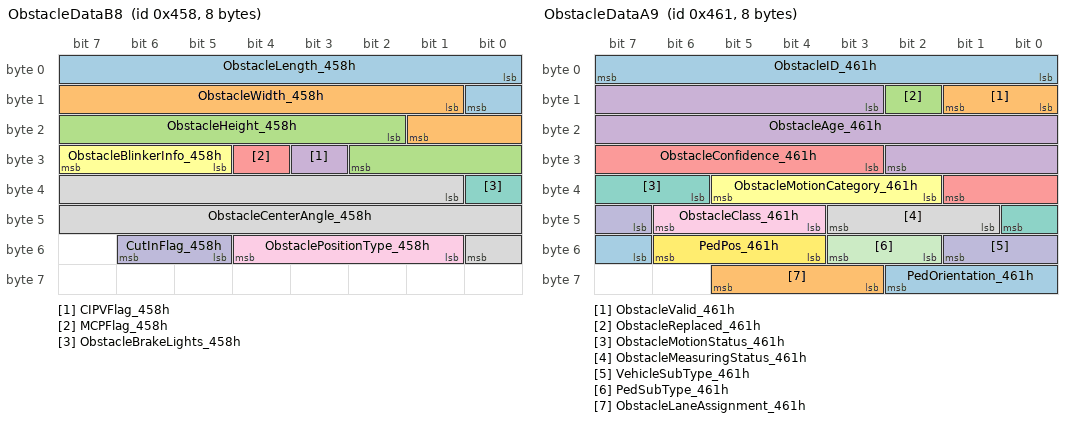
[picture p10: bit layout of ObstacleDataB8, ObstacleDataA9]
BO_ 1112 ObstacleDataB8: 8 Matrix
 SG_ ObstacleLength_458h : 0|9@1+ (0.05,0) [0.0|25.6] "m" Vector__XXX
 SG_ ObstacleWidth_458h : 9|9@1+ (0.02,0) [0.0|10.24] "m" Vector__XXX
 SG_ ObstacleHeight_458h : 18|9@1+ (0.02,0) [0.0|10.24] "m" Vector__XXX
 SG_ CIPVFlag_458h : 27|1@1+ (1,0) [0.0|1.0] "bool" Vector__XXX
 SG_ MCPFlag_458h : 28|1@1+ (1,0) [0.0|1.0] "bool" Vector__XXX
 SG_ ObstacleBlinkerInfo_458h : 29|3@1+ (1,0) [0.0|7.0] "enum" Vector__XXX
 SG_ ObstacleBrakeLights_458h : 32|1@1+ (1,0) [0.0|1.0] "bool" Vector__XXX
 SG_ ObstacleCenterAngle_458h : 33|16@1+ (0.01,-327.68) [-327.68|327.67] "degree" Vector__XXX
 SG_ ObstaclePositionType_458h : 49|4@1+ (1,0) [0.0|15.0] "enum" Vector__XXX
 SG_ CutInFlag_458h : 53|2@1+ (1,0) [0.0|3.0] "bool" Vector__XXX

BO_ 1113 ObstacleDataC8: 8 Matrix
 SG_ ObstaclePosX_459h : 0|13@1+ (0.0625,-250) [-250.0|250.0] "m" Vector__XXX
 SG_ ObstaclePosY_459h : 13|13@1+ (0.0625,-250) [-250.0|250.0] "m" Vector__XXX
 SG_ ObstacleVelX_459h : 26|12@1+ (0.05,-102.4) [-102.4|102.35] "m/sec" Vector__XXX
 SG_ ObstacleVelY_459h : 38|12@1+ (0.05,-50) [-50.0|50.0] "m/sec" Vector__XXX
 SG_ ObstacleAccX_459h : 50|10@1+ (0.03,-14.97) [-14.97|14.97] "m/s^2" Vector__XXX

BO_ 1114 ObstacleDataD8: 8 Matrix
 SG_ ObstaclePosXSTD_45Ah : 0|13@1+ (0.0625,0) [0.0|250.0] "m" Vector__XXX
 SG_ ObstaclePosYSTD_45Ah : 13|13@1+ (0.0625,0) [0.0|250.0] "m" Vector__XXX
 SG_ ObstacleVelXSTD_45Ah : 26|12@1+ (0.05,0) [0.0|102.35] "m/sec" Vector__XXX
 SG_ ObstacleVelYSTD_45Ah : 38|12@1+ (0.05,0) [0.0|50.0] "m/sec" Vector__XXX
 SG_ ObstacleAccY_45Ah : 50|10@1+ (0.03,-14.97) [-14.97|14.97] "m/s^2" Vector__XXX

BO_ 1115 ObstacleDataE8: 8 Matrix
 SG_ ObstacleAngle_45Bh : 0|16@1+ (0.01,-327.68) [-327.68|327.67] "degree" Vector__XXX
 SG_ ObstacleAngleStd_45Bh : 16|16@1+ (0.01,0) [0.0|327.67] "degree" Vector__XXX
 SG_ ObstacleVelXAbs_45Bh : 32|12@1+ (0.05,-102.4) [-102.4|102.35] "m/sec" Vector__XXX
 SG_ ObstacleVelYAbs_45Bh : 44|12@1+ (0.05,-50) [-50.0|50.0] "m/sec" Vector__XXX

BO_ 1116 ObstacleDataF8: 8 Matrix
 SG_ ObjCornerPointPoxX_45Ch : 0|13@1+ (0.0625,-250) [-250.0|250.0] "m" Vector__XXX
 SG_ CutInDistance_45Ch : 13|13@1+ (0.0625,-250) [-250.0|250.0] "m" Vector__XXX
 SG_ ObjCornerPointPoxY_45Ch : 26|13@1+ (0.0625,-250) [-250.0|250.0] "m" Vector__XXX
 SG_ ObstacleCurvature_45Ch : 39|15@1+ (1,-9999) [-9999.0|9999.0] "m" Vector__XXX

BO_ 1121 ObstacleDataA9: 8 Matrix
 SG_ ObstacleID_461h : 0|8@1+ (1,0) [0.0|255.0] "NA" Vector__XXX
 SG_ ObstacleValid_461h : 8|2@1+ (1,0) [0.0|3.0] "bool" Vector__XXX
 SG_ ObstacleReplaced_461h : 10|1@1+ (1,0) [0.0|1.0] "bool" Vector__XXX
 SG_ ObstacleAge_461h : 11|16@1+ (1,0) [0.0|65535.0] "NA" Vector__XXX
 SG_ ObstacleConfidence_461h : 27|7@1+ (1,0) [0.0|100.0] "NA" Vector__XXX
 SG_ ObstacleMotionCategory_461h : 34|4@1+ (1,0) [0.0|15.0] "enum" Vector__XXX
 SG_ ObstacleMotionStatus_461h : 38|3@1+ (1,0) [0.0|7.0] "enum" Vector__XXX
 SG_ ObstacleMeasuringStatus_461h : 41|3@1+ (1,0) [0.0|7.0] "enum" Vector__XXX
 SG_ ObstacleClass_461h : 44|3@1+ (1,0) [0.0|7.0] "enum" Vector__XXX
 SG_ VehicleSubType_461h : 47|3@1+ (1,0) [0.0|7.0] "enum" Vector__XXX
 SG_ PedSubType_461h : 50|2@1+ (1,0) [0.0|3.0] "enum" Vector__XXX
 SG_ PedPos_461h : 52|3@1+ (1,0) [0.0|7.0] "enum" Vector__XXX
 SG_ PedOrientation_461h : 55|4@1+ (1,0) [0.0|15.0] "enum" Vector__XXX
 SG_ ObstacleLaneAssignment_461h : 59|3@1+ (1,0) [0.0|7.0] "enum" Vector__XXX

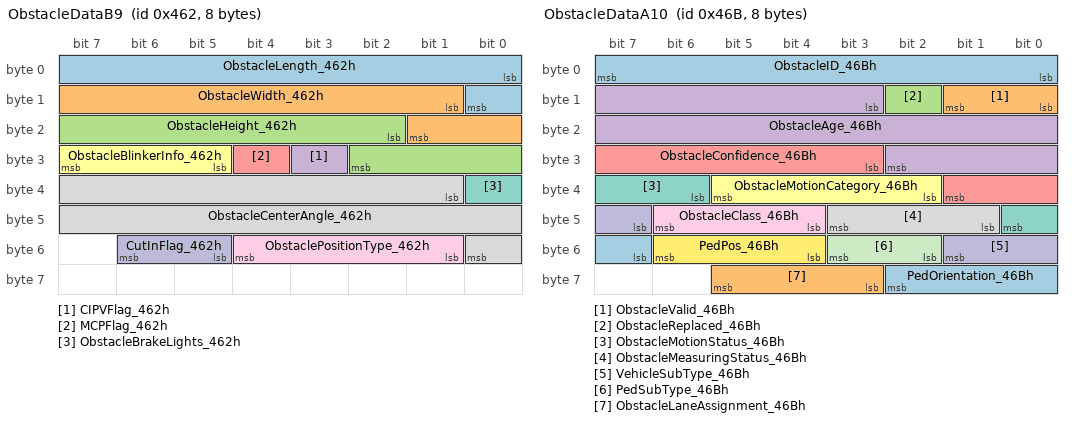
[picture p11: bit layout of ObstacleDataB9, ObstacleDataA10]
BO_ 1122 ObstacleDataB9: 8 Matrix
 SG_ ObstacleLength_462h : 0|9@1+ (0.05,0) [0.0|25.6] "m" Vector__XXX
 SG_ ObstacleWidth_462h : 9|9@1+ (0.02,0) [0.0|10.24] "m" Vector__XXX
 SG_ ObstacleHeight_462h : 18|9@1+ (0.02,0) [0.0|10.24] "m" Vector__XXX
 SG_ CIPVFlag_462h : 27|1@1+ (1,0) [0.0|1.0] "bool" Vector__XXX
 SG_ MCPFlag_462h : 28|1@1+ (1,0) [0.0|1.0] "bool" Vector__XXX
 SG_ ObstacleBlinkerInfo_462h : 29|3@1+ (1,0) [0.0|7.0] "enum" Vector__XXX
 SG_ ObstacleBrakeLights_462h : 32|1@1+ (1,0) [0.0|1.0] "bool" Vector__XXX
 SG_ ObstacleCenterAngle_462h : 33|16@1+ (0.01,-327.68) [-327.68|327.67] "degree" Vector__XXX
 SG_ ObstaclePositionType_462h : 49|4@1+ (1,0) [0.0|15.0] "enum" Vector__XXX
 SG_ CutInFlag_462h : 53|2@1+ (1,0) [0.0|3.0] "bool" Vector__XXX

BO_ 1123 ObstacleDataC9: 8 Matrix
 SG_ ObstaclePosX_463h : 0|13@1+ (0.0625,-250) [-250.0|250.0] "m" Vector__XXX
 SG_ ObstaclePosY_463h : 13|13@1+ (0.0625,-250) [-250.0|250.0] "m" Vector__XXX
 SG_ ObstacleVelX_463h : 26|12@1+ (0.05,-102.4) [-102.4|102.35] "m/sec" Vector__XXX
 SG_ ObstacleVelY_463h : 38|12@1+ (0.05,-50) [-50.0|50.0] "m/sec" Vector__XXX
 SG_ ObstacleAccX_463h : 50|10@1+ (0.03,-14.97) [-14.97|14.97] "m/s^2" Vector__XXX

BO_ 1124 ObstacleDataD9: 8 Matrix
 SG_ ObstaclePosXSTD_464h : 0|13@1+ (0.0625,0) [0.0|250.0] "m" Vector__XXX
 SG_ ObstaclePosYSTD_464h : 13|13@1+ (0.0625,0) [0.0|250.0] "m" Vector__XXX
 SG_ ObstacleVelXSTD_464h : 26|12@1+ (0.05,0) [0.0|102.35] "m/sec" Vector__XXX
 SG_ ObstacleVelYSTD_464h : 38|12@1+ (0.05,0) [0.0|50.0] "m/sec" Vector__XXX
 SG_ ObstacleAccY_464h : 50|10@1+ (0.03,-14.97) [-14.97|14.97] "m/s^2" Vector__XXX

BO_ 1125 ObstacleDataE9: 8 Matrix
 SG_ ObstacleAngle_465h : 0|16@1+ (0.01,-327.68) [-327.68|327.67] "degree" Vector__XXX
 SG_ ObstacleAngleStd_465h : 16|16@1+ (0.01,0) [0.0|327.67] "degree" Vector__XXX
 SG_ ObstacleVelXAbs_465h : 32|12@1+ (0.05,-102.4) [-102.4|102.35] "m/sec" Vector__XXX
 SG_ ObstacleVelYAbs_465h : 44|12@1+ (0.05,-50) [-50.0|50.0] "m/sec" Vector__XXX

BO_ 1126 ObstacleDataF9: 8 Matrix
 SG_ ObjCornerPointPoxX_466h : 0|13@1+ (0.0625,-250) [-250.0|250.0] "m" Vector__XXX
 SG_ CutInDistance_466h : 13|13@1+ (0.0625,-250) [-250.0|250.0] "m" Vector__XXX
 SG_ ObjCornerPointPoxY_466h : 26|13@1+ (0.0625,-250) [-250.0|250.0] "m" Vector__XXX
 SG_ ObstacleCurvature_466h : 39|15@1+ (1,-9999) [-9999.0|9999.0] "m" Vector__XXX

BO_ 1131 ObstacleDataA10: 8 Matrix
 SG_ ObstacleID_46Bh : 0|8@1+ (1,0) [0.0|255.0] "NA" Vector__XXX
 SG_ ObstacleValid_46Bh : 8|2@1+ (1,0) [0.0|3.0] "bool" Vector__XXX
 SG_ ObstacleReplaced_46Bh : 10|1@1+ (1,0) [0.0|1.0] "bool" Vector__XXX
 SG_ ObstacleAge_46Bh : 11|16@1+ (1,0) [0.0|65535.0] "NA" Vector__XXX
 SG_ ObstacleConfidence_46Bh : 27|7@1+ (1,0) [0.0|100.0] "NA" Vector__XXX
 SG_ ObstacleMotionCategory_46Bh : 34|4@1+ (1,0) [0.0|15.0] "enum" Vector__XXX
 SG_ ObstacleMotionStatus_46Bh : 38|3@1+ (1,0) [0.0|7.0] "enum" Vector__XXX
 SG_ ObstacleMeasuringStatus_46Bh : 41|3@1+ (1,0) [0.0|7.0] "enum" Vector__XXX
 SG_ ObstacleClass_46Bh : 44|3@1+ (1,0) [0.0|7.0] "enum" Vector__XXX
 SG_ VehicleSubType_46Bh : 47|3@1+ (1,0) [0.0|7.0] "enum" Vector__XXX
 SG_ PedSubType_46Bh : 50|2@1+ (1,0) [0.0|3.0] "enum" Vector__XXX
 SG_ PedPos_46Bh : 52|3@1+ (1,0) [0.0|7.0] "enum" Vector__XXX
 SG_ PedOrientation_46Bh : 55|4@1+ (1,0) [0.0|15.0] "enum" Vector__XXX
 SG_ ObstacleLaneAssignment_46Bh : 59|3@1+ (1,0) [0.0|7.0] "enum" Vector__XXX

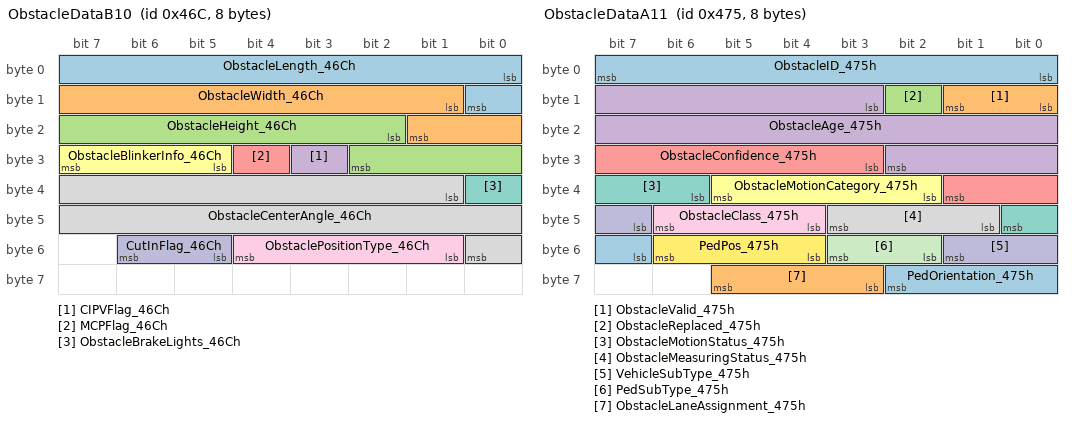
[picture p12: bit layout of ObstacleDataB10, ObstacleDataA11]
BO_ 1132 ObstacleDataB10: 8 Matrix
 SG_ ObstacleLength_46Ch : 0|9@1+ (0.05,0) [0.0|25.6] "m" Vector__XXX
 SG_ ObstacleWidth_46Ch : 9|9@1+ (0.02,0) [0.0|10.24] "m" Vector__XXX
 SG_ ObstacleHeight_46Ch : 18|9@1+ (0.02,0) [0.0|10.24] "m" Vector__XXX
 SG_ CIPVFlag_46Ch : 27|1@1+ (1,0) [0.0|1.0] "bool" Vector__XXX
 SG_ MCPFlag_46Ch : 28|1@1+ (1,0) [0.0|1.0] "bool" Vector__XXX
 SG_ ObstacleBlinkerInfo_46Ch : 29|3@1+ (1,0) [0.0|7.0] "enum" Vector__XXX
 SG_ ObstacleBrakeLights_46Ch : 32|1@1+ (1,0) [0.0|1.0] "bool" Vector__XXX
 SG_ ObstacleCenterAngle_46Ch : 33|16@1+ (0.01,-327.68) [-327.68|327.67] "degree" Vector__XXX
 SG_ ObstaclePositionType_46Ch : 49|4@1+ (1,0) [0.0|15.0] "enum" Vector__XXX
 SG_ CutInFlag_46Ch : 53|2@1+ (1,0) [0.0|3.0] "bool" Vector__XXX

BO_ 1133 ObstacleDataC10: 8 Matrix
 SG_ ObstaclePosX_46Dh : 0|13@1+ (0.0625,-250) [-250.0|250.0] "m" Vector__XXX
 SG_ ObstaclePosY_46Dh : 13|13@1+ (0.0625,-250) [-250.0|250.0] "m" Vector__XXX
 SG_ ObstacleVelX_46Dh : 26|12@1+ (0.05,-102.4) [-102.4|102.35] "m/sec" Vector__XXX
 SG_ ObstacleVelY_46Dh : 38|12@1+ (0.05,-50) [-50.0|50.0] "m/sec" Vector__XXX
 SG_ ObstacleAccX_46Dh : 50|10@1+ (0.03,-14.97) [-14.97|14.97] "m/s^2" Vector__XXX

BO_ 1134 ObstacleDataD10: 8 Matrix
 SG_ ObstaclePosXSTD_46Eh : 0|13@1+ (0.0625,0) [0.0|250.0] "m" Vector__XXX
 SG_ ObstaclePosYSTD_46Eh : 13|13@1+ (0.0625,0) [0.0|250.0] "m" Vector__XXX
 SG_ ObstacleVelXSTD_46Eh : 26|12@1+ (0.05,0) [0.0|102.35] "m/sec" Vector__XXX
 SG_ ObstacleVelYSTD_46Eh : 38|12@1+ (0.05,0) [0.0|50.0] "m/sec" Vector__XXX
 SG_ ObstacleAccY_46Eh : 50|10@1+ (0.03,-14.97) [-14.97|14.97] "m/s^2" Vector__XXX

BO_ 1135 ObstacleDataE10: 8 Matrix
 SG_ ObstacleAngle_46Fh : 0|16@1+ (0.01,-327.68) [-327.68|327.67] "degree" Vector__XXX
 SG_ ObstacleAngleStd_46Fh : 16|16@1+ (0.01,0) [0.0|327.67] "degree" Vector__XXX
 SG_ ObstacleVelXAbs_46Fh : 32|12@1+ (0.05,-102.4) [-102.4|102.35] "m/sec" Vector__XXX
 SG_ ObstacleVelYAbs_46Fh : 44|12@1+ (0.05,-50) [-50.0|50.0] "m/sec" Vector__XXX

BO_ 1136 ObstacleDataF10: 8 Matrix
 SG_ ObjCornerPointPoxX_470h : 0|13@1+ (0.0625,-250) [-250.0|250.0] "m" Vector__XXX
 SG_ CutInDistance_470h : 13|13@1+ (0.0625,-250) [-250.0|250.0] "m" Vector__XXX
 SG_ ObjCornerPointPoxY_470h : 26|13@1+ (0.0625,-250) [-250.0|250.0] "m" Vector__XXX
 SG_ ObstacleCurvature_470h : 39|15@1+ (1,-9999) [-9999.0|9999.0] "m" Vector__XXX

BO_ 1141 ObstacleDataA11: 8 Matrix
 SG_ ObstacleID_475h : 0|8@1+ (1,0) [0.0|255.0] "NA" Vector__XXX
 SG_ ObstacleValid_475h : 8|2@1+ (1,0) [0.0|3.0] "bool" Vector__XXX
 SG_ ObstacleReplaced_475h : 10|1@1+ (1,0) [0.0|1.0] "bool" Vector__XXX
 SG_ ObstacleAge_475h : 11|16@1+ (1,0) [0.0|65535.0] "NA" Vector__XXX
 SG_ ObstacleConfidence_475h : 27|7@1+ (1,0) [0.0|100.0] "NA" Vector__XXX
 SG_ ObstacleMotionCategory_475h : 34|4@1+ (1,0) [0.0|15.0] "enum" Vector__XXX
 SG_ ObstacleMotionStatus_475h : 38|3@1+ (1,0) [0.0|7.0] "enum" Vector__XXX
 SG_ ObstacleMeasuringStatus_475h : 41|3@1+ (1,0) [0.0|7.0] "enum" Vector__XXX
 SG_ ObstacleClass_475h : 44|3@1+ (1,0) [0.0|7.0] "enum" Vector__XXX
 SG_ VehicleSubType_475h : 47|3@1+ (1,0) [0.0|7.0] "enum" Vector__XXX
 SG_ PedSubType_475h : 50|2@1+ (1,0) [0.0|3.0] "enum" Vector__XXX
 SG_ PedPos_475h : 52|3@1+ (1,0) [0.0|7.0] "enum" Vector__XXX
 SG_ PedOrientation_475h : 55|4@1+ (1,0) [0.0|15.0] "enum" Vector__XXX
 SG_ ObstacleLaneAssignment_475h : 59|3@1+ (1,0) [0.0|7.0] "enum" Vector__XXX

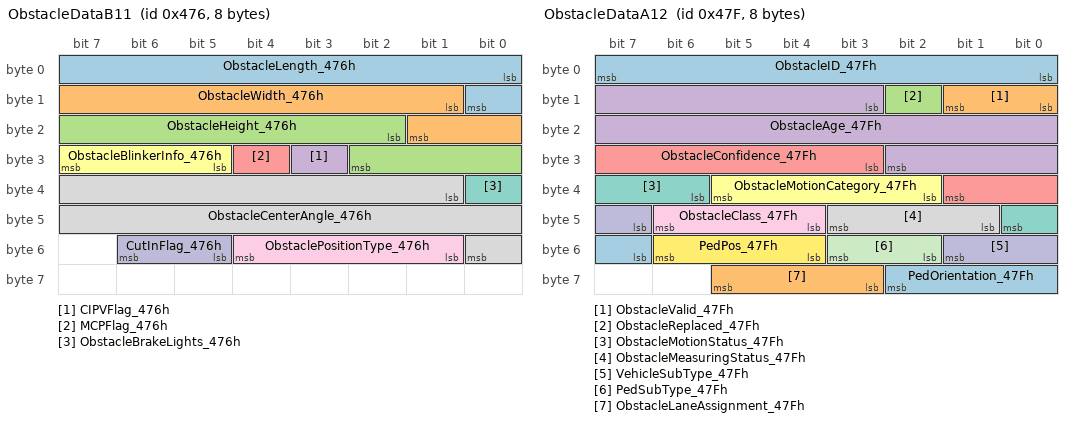
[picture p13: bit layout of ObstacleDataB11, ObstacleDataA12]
BO_ 1142 ObstacleDataB11: 8 Matrix
 SG_ ObstacleLength_476h : 0|9@1+ (0.05,0) [0.0|25.6] "m" Vector__XXX
 SG_ ObstacleWidth_476h : 9|9@1+ (0.02,0) [0.0|10.24] "m" Vector__XXX
 SG_ ObstacleHeight_476h : 18|9@1+ (0.02,0) [0.0|10.24] "m" Vector__XXX
 SG_ CIPVFlag_476h : 27|1@1+ (1,0) [0.0|1.0] "bool" Vector__XXX
 SG_ MCPFlag_476h : 28|1@1+ (1,0) [0.0|1.0] "bool" Vector__XXX
 SG_ ObstacleBlinkerInfo_476h : 29|3@1+ (1,0) [0.0|7.0] "enum" Vector__XXX
 SG_ ObstacleBrakeLights_476h : 32|1@1+ (1,0) [0.0|1.0] "bool" Vector__XXX
 SG_ ObstacleCenterAngle_476h : 33|16@1+ (0.01,-327.68) [-327.68|327.67] "degree" Vector__XXX
 SG_ ObstaclePositionType_476h : 49|4@1+ (1,0) [0.0|15.0] "enum" Vector__XXX
 SG_ CutInFlag_476h : 53|2@1+ (1,0) [0.0|3.0] "bool" Vector__XXX

BO_ 1143 ObstacleDataC11: 8 Matrix
 SG_ ObstaclePosX_477h : 0|13@1+ (0.0625,-250) [-250.0|250.0] "m" Vector__XXX
 SG_ ObstaclePosY_477h : 13|13@1+ (0.0625,-250) [-250.0|250.0] "m" Vector__XXX
 SG_ ObstacleVelX_477h : 26|12@1+ (0.05,-102.4) [-102.4|102.35] "m/sec" Vector__XXX
 SG_ ObstacleVelY_477h : 38|12@1+ (0.05,-50) [-50.0|50.0] "m/sec" Vector__XXX
 SG_ ObstacleAccX_477h : 50|10@1+ (0.03,-14.97) [-14.97|14.97] "m/s^2" Vector__XXX

BO_ 1144 ObstacleDataD11: 8 Matrix
 SG_ ObstaclePosXSTD_478h : 0|13@1+ (0.0625,0) [0.0|250.0] "m" Vector__XXX
 SG_ ObstaclePosYSTD_478h : 13|13@1+ (0.0625,0) [0.0|250.0] "m" Vector__XXX
 SG_ ObstacleVelXSTD_478h : 26|12@1+ (0.05,0) [0.0|102.35] "m/sec" Vector__XXX
 SG_ ObstacleVelYSTD_478h : 38|12@1+ (0.05,0) [0.0|50.0] "m/sec" Vector__XXX
 SG_ ObstacleAccY_478h : 50|10@1+ (0.03,-14.97) [-14.97|14.97] "m/s^2" Vector__XXX

BO_ 1145 ObstacleDataE11: 8 Matrix
 SG_ ObstacleAngle_479h : 0|16@1+ (0.01,-327.68) [-327.68|327.67] "degree" Vector__XXX
 SG_ ObstacleAngleStd_479h : 16|16@1+ (0.01,0) [0.0|327.67] "degree" Vector__XXX
 SG_ ObstacleVelXAbs_479h : 32|12@1+ (0.05,-102.4) [-102.4|102.35] "m/sec" Vector__XXX
 SG_ ObstacleVelYAbs_479h : 44|12@1+ (0.05,-50) [-50.0|50.0] "m/sec" Vector__XXX

BO_ 1146 ObstacleDataF11: 8 Matrix
 SG_ ObjCornerPointPoxX_47Ah : 0|13@1+ (0.0625,-250) [-250.0|250.0] "m" Vector__XXX
 SG_ CutInDistance_47Ah : 13|13@1+ (0.0625,-250) [-250.0|250.0] "m" Vector__XXX
 SG_ ObjCornerPointPoxY_47Ah : 26|13@1+ (0.0625,-250) [-250.0|250.0] "m" Vector__XXX
 SG_ ObstacleCurvature_47Ah : 39|15@1+ (1,-9999) [-9999.0|9999.0] "m" Vector__XXX

BO_ 1151 ObstacleDataA12: 8 Matrix
 SG_ ObstacleID_47Fh : 0|8@1+ (1,0) [0.0|255.0] "NA" Vector__XXX
 SG_ ObstacleValid_47Fh : 8|2@1+ (1,0) [0.0|3.0] "bool" Vector__XXX
 SG_ ObstacleReplaced_47Fh : 10|1@1+ (1,0) [0.0|1.0] "bool" Vector__XXX
 SG_ ObstacleAge_47Fh : 11|16@1+ (1,0) [0.0|65535.0] "NA" Vector__XXX
 SG_ ObstacleConfidence_47Fh : 27|7@1+ (1,0) [0.0|100.0] "NA" Vector__XXX
 SG_ ObstacleMotionCategory_47Fh : 34|4@1+ (1,0) [0.0|15.0] "enum" Vector__XXX
 SG_ ObstacleMotionStatus_47Fh : 38|3@1+ (1,0) [0.0|7.0] "enum" Vector__XXX
 SG_ ObstacleMeasuringStatus_47Fh : 41|3@1+ (1,0) [0.0|7.0] "enum" Vector__XXX
 SG_ ObstacleClass_47Fh : 44|3@1+ (1,0) [0.0|7.0] "enum" Vector__XXX
 SG_ VehicleSubType_47Fh : 47|3@1+ (1,0) [0.0|7.0] "enum" Vector__XXX
 SG_ PedSubType_47Fh : 50|2@1+ (1,0) [0.0|3.0] "enum" Vector__XXX
 SG_ PedPos_47Fh : 52|3@1+ (1,0) [0.0|7.0] "enum" Vector__XXX
 SG_ PedOrientation_47Fh : 55|4@1+ (1,0) [0.0|15.0] "enum" Vector__XXX
 SG_ ObstacleLaneAssignment_47Fh : 59|3@1+ (1,0) [0.0|7.0] "enum" Vector__XXX

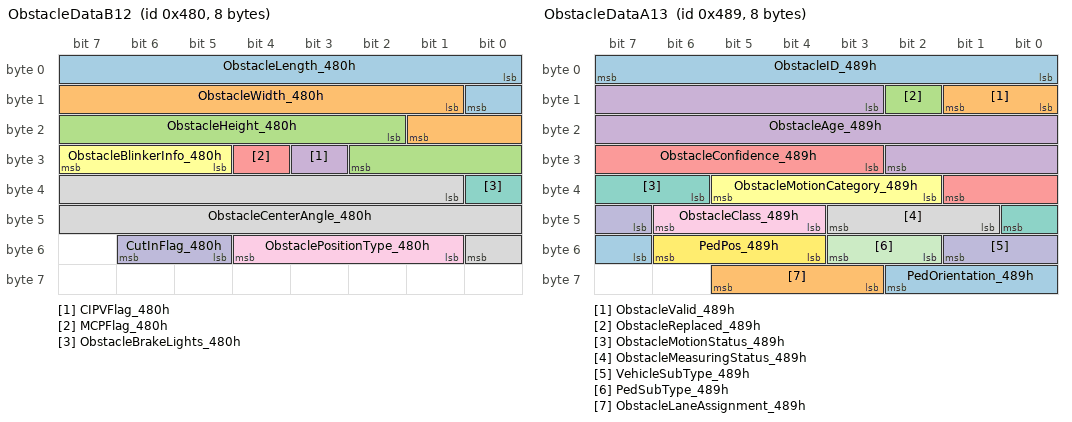
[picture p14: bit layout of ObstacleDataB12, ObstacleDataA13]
BO_ 1152 ObstacleDataB12: 8 Matrix
 SG_ ObstacleLength_480h : 0|9@1+ (0.05,0) [0.0|25.6] "m" Vector__XXX
 SG_ ObstacleWidth_480h : 9|9@1+ (0.02,0) [0.0|10.24] "m" Vector__XXX
 SG_ ObstacleHeight_480h : 18|9@1+ (0.02,0) [0.0|10.24] "m" Vector__XXX
 SG_ CIPVFlag_480h : 27|1@1+ (1,0) [0.0|1.0] "bool" Vector__XXX
 SG_ MCPFlag_480h : 28|1@1+ (1,0) [0.0|1.0] "bool" Vector__XXX
 SG_ ObstacleBlinkerInfo_480h : 29|3@1+ (1,0) [0.0|7.0] "enum" Vector__XXX
 SG_ ObstacleBrakeLights_480h : 32|1@1+ (1,0) [0.0|1.0] "bool" Vector__XXX
 SG_ ObstacleCenterAngle_480h : 33|16@1+ (0.01,-327.68) [-327.68|327.67] "degree" Vector__XXX
 SG_ ObstaclePositionType_480h : 49|4@1+ (1,0) [0.0|15.0] "enum" Vector__XXX
 SG_ CutInFlag_480h : 53|2@1+ (1,0) [0.0|3.0] "bool" Vector__XXX

BO_ 1153 ObstacleDataC12: 8 Matrix
 SG_ ObstaclePosX_481h : 0|13@1+ (0.0625,-250) [-250.0|250.0] "m" Vector__XXX
 SG_ ObstaclePosY_481h : 13|13@1+ (0.0625,-250) [-250.0|250.0] "m" Vector__XXX
 SG_ ObstacleVelX_481h : 26|12@1+ (0.05,-102.4) [-102.4|102.35] "m/sec" Vector__XXX
 SG_ ObstacleVelY_481h : 38|12@1+ (0.05,-50) [-50.0|50.0] "m/sec" Vector__XXX
 SG_ ObstacleAccX_481h : 50|10@1+ (0.03,-14.97) [-14.97|14.97] "m/s^2" Vector__XXX

BO_ 1154 ObstacleDataD12: 8 Matrix
 SG_ ObstaclePosXSTD_482h : 0|13@1+ (0.0625,0) [0.0|250.0] "m" Vector__XXX
 SG_ ObstaclePosYSTD_482h : 13|13@1+ (0.0625,0) [0.0|250.0] "m" Vector__XXX
 SG_ ObstacleVelXSTD_482h : 26|12@1+ (0.05,0) [0.0|102.35] "m/sec" Vector__XXX
 SG_ ObstacleVelYSTD_482h : 38|12@1+ (0.05,0) [0.0|50.0] "m/sec" Vector__XXX
 SG_ ObstacleAccY_482h : 50|10@1+ (0.03,-14.97) [-14.97|14.97] "m/s^2" Vector__XXX

BO_ 1155 ObstacleDataE12: 8 Matrix
 SG_ ObstacleAngle_483h : 0|16@1+ (0.01,-327.68) [-327.68|327.67] "degree" Vector__XXX
 SG_ ObstacleAngleStd_483h : 16|16@1+ (0.01,0) [0.0|327.67] "degree" Vector__XXX
 SG_ ObstacleVelXAbs_483h : 32|12@1+ (0.05,-102.4) [-102.4|102.35] "m/sec" Vector__XXX
 SG_ ObstacleVelYAbs_483h : 44|12@1+ (0.05,-50) [-50.0|50.0] "m/sec" Vector__XXX

BO_ 1156 ObstacleDataF12: 8 Matrix
 SG_ ObjCornerPointPoxX_484h : 0|13@1+ (0.0625,-250) [-250.0|250.0] "m" Vector__XXX
 SG_ CutInDistance_484h : 13|13@1+ (0.0625,-250) [-250.0|250.0] "m" Vector__XXX
 SG_ ObjCornerPointPoxY_484h : 26|13@1+ (0.0625,-250) [-250.0|250.0] "m" Vector__XXX
 SG_ ObstacleCurvature_484h : 39|15@1+ (1,-9999) [-9999.0|9999.0] "m" Vector__XXX

BO_ 1161 ObstacleDataA13: 8 Matrix
 SG_ ObstacleID_489h : 0|8@1+ (1,0) [0.0|255.0] "NA" Vector__XXX
 SG_ ObstacleValid_489h : 8|2@1+ (1,0) [0.0|3.0] "bool" Vector__XXX
 SG_ ObstacleReplaced_489h : 10|1@1+ (1,0) [0.0|1.0] "bool" Vector__XXX
 SG_ ObstacleAge_489h : 11|16@1+ (1,0) [0.0|65535.0] "NA" Vector__XXX
 SG_ ObstacleConfidence_489h : 27|7@1+ (1,0) [0.0|100.0] "NA" Vector__XXX
 SG_ ObstacleMotionCategory_489h : 34|4@1+ (1,0) [0.0|15.0] "enum" Vector__XXX
 SG_ ObstacleMotionStatus_489h : 38|3@1+ (1,0) [0.0|7.0] "enum" Vector__XXX
 SG_ ObstacleMeasuringStatus_489h : 41|3@1+ (1,0) [0.0|7.0] "enum" Vector__XXX
 SG_ ObstacleClass_489h : 44|3@1+ (1,0) [0.0|7.0] "enum" Vector__XXX
 SG_ VehicleSubType_489h : 47|3@1+ (1,0) [0.0|7.0] "enum" Vector__XXX
 SG_ PedSubType_489h : 50|2@1+ (1,0) [0.0|3.0] "enum" Vector__XXX
 SG_ PedPos_489h : 52|3@1+ (1,0) [0.0|7.0] "enum" Vector__XXX
 SG_ PedOrientation_489h : 55|4@1+ (1,0) [0.0|15.0] "enum" Vector__XXX
 SG_ ObstacleLaneAssignment_489h : 59|3@1+ (1,0) [0.0|7.0] "enum" Vector__XXX

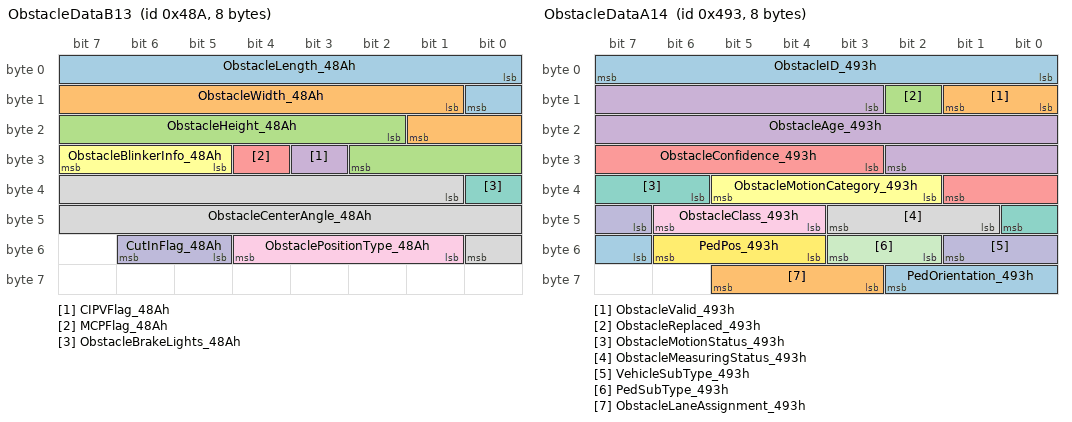
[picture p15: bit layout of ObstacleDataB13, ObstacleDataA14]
BO_ 1162 ObstacleDataB13: 8 Matrix
 SG_ ObstacleLength_48Ah : 0|9@1+ (0.05,0) [0.0|25.6] "m" Vector__XXX
 SG_ ObstacleWidth_48Ah : 9|9@1+ (0.02,0) [0.0|10.24] "m" Vector__XXX
 SG_ ObstacleHeight_48Ah : 18|9@1+ (0.02,0) [0.0|10.24] "m" Vector__XXX
 SG_ CIPVFlag_48Ah : 27|1@1+ (1,0) [0.0|1.0] "bool" Vector__XXX
 SG_ MCPFlag_48Ah : 28|1@1+ (1,0) [0.0|1.0] "bool" Vector__XXX
 SG_ ObstacleBlinkerInfo_48Ah : 29|3@1+ (1,0) [0.0|7.0] "enum" Vector__XXX
 SG_ ObstacleBrakeLights_48Ah : 32|1@1+ (1,0) [0.0|1.0] "bool" Vector__XXX
 SG_ ObstacleCenterAngle_48Ah : 33|16@1+ (0.01,-327.68) [-327.68|327.67] "degree" Vector__XXX
 SG_ ObstaclePositionType_48Ah : 49|4@1+ (1,0) [0.0|15.0] "enum" Vector__XXX
 SG_ CutInFlag_48Ah : 53|2@1+ (1,0) [0.0|3.0] "bool" Vector__XXX

BO_ 1163 ObstacleDataC13: 8 Matrix
 SG_ ObstaclePosX_48Bh : 0|13@1+ (0.0625,-250) [-250.0|250.0] "m" Vector__XXX
 SG_ ObstaclePosY_48Bh : 13|13@1+ (0.0625,-250) [-250.0|250.0] "m" Vector__XXX
 SG_ ObstacleVelX_48Bh : 26|12@1+ (0.05,-102.4) [-102.4|102.35] "m/sec" Vector__XXX
 SG_ ObstacleVelY_48Bh : 38|12@1+ (0.05,-50) [-50.0|50.0] "m/sec" Vector__XXX
 SG_ ObstacleAccX_48Bh : 50|10@1+ (0.03,-14.97) [-14.97|14.97] "m/s^2" Vector__XXX

BO_ 1164 ObstacleDataD13: 8 Matrix
 SG_ ObstaclePosXSTD_48Ch : 0|13@1+ (0.0625,0) [0.0|250.0] "m" Vector__XXX
 SG_ ObstaclePosYSTD_48Ch : 13|13@1+ (0.0625,0) [0.0|250.0] "m" Vector__XXX
 SG_ ObstacleVelXSTD_48Ch : 26|12@1+ (0.05,0) [0.0|102.35] "m/sec" Vector__XXX
 SG_ ObstacleVelYSTD_48Ch : 38|12@1+ (0.05,0) [0.0|50.0] "m/sec" Vector__XXX
 SG_ ObstacleAccY_48Ch : 50|10@1+ (0.03,-14.97) [-14.97|14.97] "m/s^2" Vector__XXX

BO_ 1165 ObstacleDataE13: 8 Matrix
 SG_ ObstacleAngle_48Dh : 0|16@1+ (0.01,-327.68) [-327.68|327.67] "degree" Vector__XXX
 SG_ ObstacleAngleStd_48Dh : 16|16@1+ (0.01,0) [0.0|327.67] "degree" Vector__XXX
 SG_ ObstacleVelXAbs_48Dh : 32|12@1+ (0.05,-102.4) [-102.4|102.35] "m/sec" Vector__XXX
 SG_ ObstacleVelYAbs_48Dh : 44|12@1+ (0.05,-50) [-50.0|50.0] "m/sec" Vector__XXX

BO_ 1166 ObstacleDataF13: 8 Matrix
 SG_ ObjCornerPointPoxX_48Eh : 0|13@1+ (0.0625,-250) [-250.0|250.0] "m" Vector__XXX
 SG_ CutInDistance_48Eh : 13|13@1+ (0.0625,-250) [-250.0|250.0] "m" Vector__XXX
 SG_ ObjCornerPointPoxY_48Eh : 26|13@1+ (0.0625,-250) [-250.0|250.0] "m" Vector__XXX
 SG_ ObstacleCurvature_48Eh : 39|15@1+ (1,-9999) [-9999.0|9999.0] "m" Vector__XXX

BO_ 1171 ObstacleDataA14: 8 Matrix
 SG_ ObstacleID_493h : 0|8@1+ (1,0) [0.0|255.0] "NA" Vector__XXX
 SG_ ObstacleValid_493h : 8|2@1+ (1,0) [0.0|3.0] "bool" Vector__XXX
 SG_ ObstacleReplaced_493h : 10|1@1+ (1,0) [0.0|1.0] "bool" Vector__XXX
 SG_ ObstacleAge_493h : 11|16@1+ (1,0) [0.0|65535.0] "NA" Vector__XXX
 SG_ ObstacleConfidence_493h : 27|7@1+ (1,0) [0.0|100.0] "NA" Vector__XXX
 SG_ ObstacleMotionCategory_493h : 34|4@1+ (1,0) [0.0|15.0] "enum" Vector__XXX
 SG_ ObstacleMotionStatus_493h : 38|3@1+ (1,0) [0.0|7.0] "enum" Vector__XXX
 SG_ ObstacleMeasuringStatus_493h : 41|3@1+ (1,0) [0.0|7.0] "enum" Vector__XXX
 SG_ ObstacleClass_493h : 44|3@1+ (1,0) [0.0|7.0] "enum" Vector__XXX
 SG_ VehicleSubType_493h : 47|3@1+ (1,0) [0.0|7.0] "enum" Vector__XXX
 SG_ PedSubType_493h : 50|2@1+ (1,0) [0.0|3.0] "enum" Vector__XXX
 SG_ PedPos_493h : 52|3@1+ (1,0) [0.0|7.0] "enum" Vector__XXX
 SG_ PedOrientation_493h : 55|4@1+ (1,0) [0.0|15.0] "enum" Vector__XXX
 SG_ ObstacleLaneAssignment_493h : 59|3@1+ (1,0) [0.0|7.0] "enum" Vector__XXX

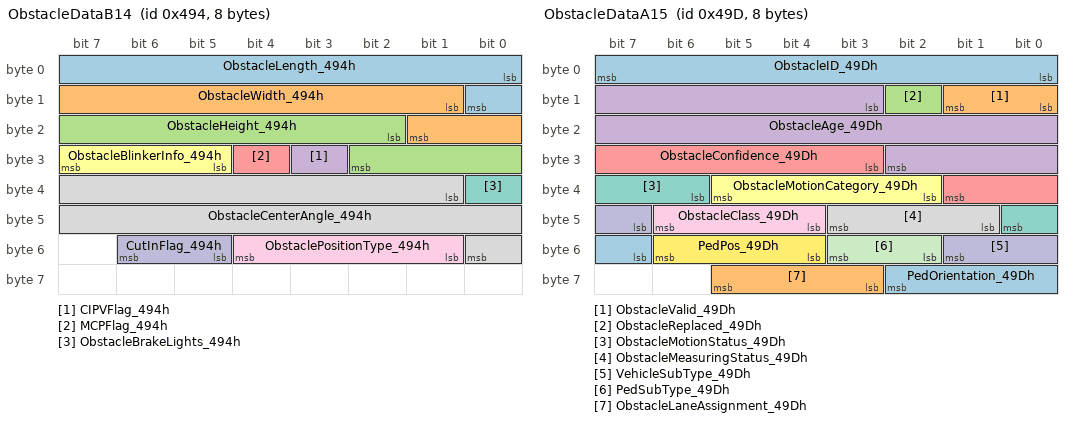
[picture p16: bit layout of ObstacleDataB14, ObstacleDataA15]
BO_ 1172 ObstacleDataB14: 8 Matrix
 SG_ ObstacleLength_494h : 0|9@1+ (0.05,0) [0.0|25.6] "m" Vector__XXX
 SG_ ObstacleWidth_494h : 9|9@1+ (0.02,0) [0.0|10.24] "m" Vector__XXX
 SG_ ObstacleHeight_494h : 18|9@1+ (0.02,0) [0.0|10.24] "m" Vector__XXX
 SG_ CIPVFlag_494h : 27|1@1+ (1,0) [0.0|1.0] "bool" Vector__XXX
 SG_ MCPFlag_494h : 28|1@1+ (1,0) [0.0|1.0] "bool" Vector__XXX
 SG_ ObstacleBlinkerInfo_494h : 29|3@1+ (1,0) [0.0|7.0] "enum" Vector__XXX
 SG_ ObstacleBrakeLights_494h : 32|1@1+ (1,0) [0.0|1.0] "bool" Vector__XXX
 SG_ ObstacleCenterAngle_494h : 33|16@1+ (0.01,-327.68) [-327.68|327.67] "degree" Vector__XXX
 SG_ ObstaclePositionType_494h : 49|4@1+ (1,0) [0.0|15.0] "enum" Vector__XXX
 SG_ CutInFlag_494h : 53|2@1+ (1,0) [0.0|3.0] "bool" Vector__XXX

BO_ 1173 ObstacleDataC14: 8 Matrix
 SG_ ObstaclePosX_495h : 0|13@1+ (0.0625,-250) [-250.0|250.0] "m" Vector__XXX
 SG_ ObstaclePosY_495h : 13|13@1+ (0.0625,-250) [-250.0|250.0] "m" Vector__XXX
 SG_ ObstacleVelX_495h : 26|12@1+ (0.05,-102.4) [-102.4|102.35] "m/sec" Vector__XXX
 SG_ ObstacleVelY_495h : 38|12@1+ (0.05,-50) [-50.0|50.0] "m/sec" Vector__XXX
 SG_ ObstacleAccX_495h : 50|10@1+ (0.03,-14.97) [-14.97|14.97] "m/s^2" Vector__XXX

BO_ 1174 ObstacleDataD14: 8 Matrix
 SG_ ObstaclePosXSTD_496h : 0|13@1+ (0.0625,0) [0.0|250.0] "m" Vector__XXX
 SG_ ObstaclePosYSTD_496h : 13|13@1+ (0.0625,0) [0.0|250.0] "m" Vector__XXX
 SG_ ObstacleVelXSTD_496h : 26|12@1+ (0.05,0) [0.0|102.35] "m/sec" Vector__XXX
 SG_ ObstacleVelYSTD_496h : 38|12@1+ (0.05,0) [0.0|50.0] "m/sec" Vector__XXX
 SG_ ObstacleAccY_496h : 50|10@1+ (0.03,-14.97) [-14.97|14.97] "m/s^2" Vector__XXX

BO_ 1175 ObstacleDataE14: 8 Matrix
 SG_ ObstacleAngle_497h : 0|16@1+ (0.01,-327.68) [-327.68|327.67] "degree" Vector__XXX
 SG_ ObstacleAngleStd_497h : 16|16@1+ (0.01,0) [0.0|327.67] "degree" Vector__XXX
 SG_ ObstacleVelXAbs_497h : 32|12@1+ (0.05,-102.4) [-102.4|102.35] "m/sec" Vector__XXX
 SG_ ObstacleVelYAbs_497h : 44|12@1+ (0.05,-50) [-50.0|50.0] "m/sec" Vector__XXX

BO_ 1176 ObstacleDataF14: 8 Matrix
 SG_ ObjCornerPointPoxX_498h : 0|13@1+ (0.0625,-250) [-250.0|250.0] "m" Vector__XXX
 SG_ CutInDistance_498h : 13|13@1+ (0.0625,-250) [-250.0|250.0] "m" Vector__XXX
 SG_ ObjCornerPointPoxY_498h : 26|13@1+ (0.0625,-250) [-250.0|250.0] "m" Vector__XXX
 SG_ ObstacleCurvature_498h : 39|15@1+ (1,-9999) [-9999.0|9999.0] "m" Vector__XXX

BO_ 1181 ObstacleDataA15: 8 Matrix
 SG_ ObstacleID_49Dh : 0|8@1+ (1,0) [0.0|255.0] "NA" Vector__XXX
 SG_ ObstacleValid_49Dh : 8|2@1+ (1,0) [0.0|3.0] "bool" Vector__XXX
 SG_ ObstacleReplaced_49Dh : 10|1@1+ (1,0) [0.0|1.0] "bool" Vector__XXX
 SG_ ObstacleAge_49Dh : 11|16@1+ (1,0) [0.0|65535.0] "NA" Vector__XXX
 SG_ ObstacleConfidence_49Dh : 27|7@1+ (1,0) [0.0|100.0] "NA" Vector__XXX
 SG_ ObstacleMotionCategory_49Dh : 34|4@1+ (1,0) [0.0|15.0] "enum" Vector__XXX
 SG_ ObstacleMotionStatus_49Dh : 38|3@1+ (1,0) [0.0|7.0] "enum" Vector__XXX
 SG_ ObstacleMeasuringStatus_49Dh : 41|3@1+ (1,0) [0.0|7.0] "enum" Vector__XXX
 SG_ ObstacleClass_49Dh : 44|3@1+ (1,0) [0.0|7.0] "enum" Vector__XXX
 SG_ VehicleSubType_49Dh : 47|3@1+ (1,0) [0.0|7.0] "enum" Vector__XXX
 SG_ PedSubType_49Dh : 50|2@1+ (1,0) [0.0|3.0] "enum" Vector__XXX
 SG_ PedPos_49Dh : 52|3@1+ (1,0) [0.0|7.0] "enum" Vector__XXX
 SG_ PedOrientation_49Dh : 55|4@1+ (1,0) [0.0|15.0] "enum" Vector__XXX
 SG_ ObstacleLaneAssignment_49Dh : 59|3@1+ (1,0) [0.0|7.0] "enum" Vector__XXX

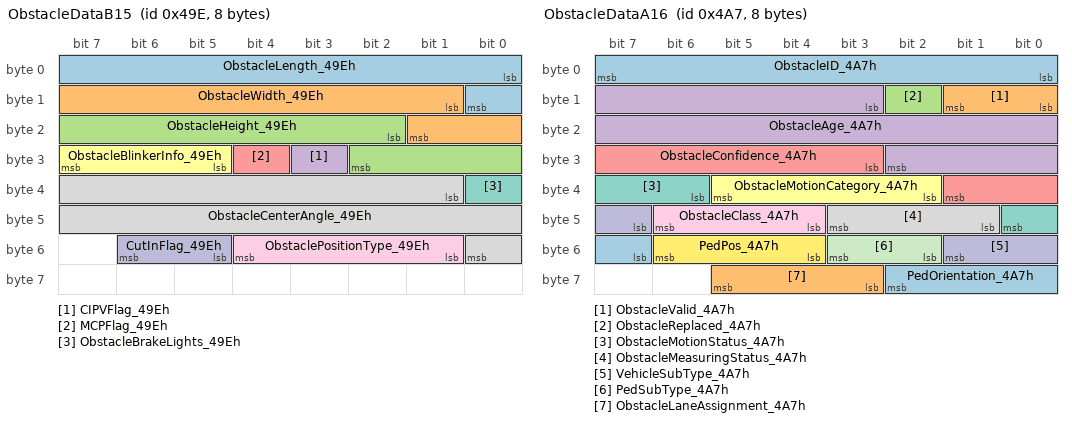
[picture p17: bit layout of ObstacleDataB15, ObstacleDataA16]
BO_ 1182 ObstacleDataB15: 8 Matrix
 SG_ ObstacleLength_49Eh : 0|9@1+ (0.05,0) [0.0|25.6] "m" Vector__XXX
 SG_ ObstacleWidth_49Eh : 9|9@1+ (0.02,0) [0.0|10.24] "m" Vector__XXX
 SG_ ObstacleHeight_49Eh : 18|9@1+ (0.02,0) [0.0|10.24] "m" Vector__XXX
 SG_ CIPVFlag_49Eh : 27|1@1+ (1,0) [0.0|1.0] "bool" Vector__XXX
 SG_ MCPFlag_49Eh : 28|1@1+ (1,0) [0.0|1.0] "bool" Vector__XXX
 SG_ ObstacleBlinkerInfo_49Eh : 29|3@1+ (1,0) [0.0|7.0] "enum" Vector__XXX
 SG_ ObstacleBrakeLights_49Eh : 32|1@1+ (1,0) [0.0|1.0] "bool" Vector__XXX
 SG_ ObstacleCenterAngle_49Eh : 33|16@1+ (0.01,-327.68) [-327.68|327.67] "degree" Vector__XXX
 SG_ ObstaclePositionType_49Eh : 49|4@1+ (1,0) [0.0|15.0] "enum" Vector__XXX
 SG_ CutInFlag_49Eh : 53|2@1+ (1,0) [0.0|3.0] "bool" Vector__XXX

BO_ 1183 ObstacleDataC15: 8 Matrix
 SG_ ObstaclePosX_49Fh : 0|13@1+ (0.0625,-250) [-250.0|250.0] "m" Vector__XXX
 SG_ ObstaclePosY_49Fh : 13|13@1+ (0.0625,-250) [-250.0|250.0] "m" Vector__XXX
 SG_ ObstacleVelX_49Fh : 26|12@1+ (0.05,-102.4) [-102.4|102.35] "m/sec" Vector__XXX
 SG_ ObstacleVelY_49Fh : 38|12@1+ (0.05,-50) [-50.0|50.0] "m/sec" Vector__XXX
 SG_ ObstacleAccX_49Fh : 50|10@1+ (0.03,-14.97) [-14.97|14.97] "m/s^2" Vector__XXX

BO_ 1184 ObstacleDataD15: 8 Matrix
 SG_ ObstaclePosXSTD_4A0h : 0|13@1+ (0.0625,0) [0.0|250.0] "m" Vector__XXX
 SG_ ObstaclePosYSTD_4A0h : 13|13@1+ (0.0625,0) [0.0|250.0] "m" Vector__XXX
 SG_ ObstacleVelXSTD_4A0h : 26|12@1+ (0.05,0) [0.0|102.35] "m/sec" Vector__XXX
 SG_ ObstacleVelYSTD_4A0h : 38|12@1+ (0.05,0) [0.0|50.0] "m/sec" Vector__XXX
 SG_ ObstacleAccY_4A0h : 50|10@1+ (0.03,-14.97) [-14.97|14.97] "m/s^2" Vector__XXX

BO_ 1185 ObstacleDataE15: 8 Matrix
 SG_ ObstacleAngle_4A1h : 0|16@1+ (0.01,-327.68) [-327.68|327.67] "degree" Vector__XXX
 SG_ ObstacleAngleStd_4A1h : 16|16@1+ (0.01,0) [0.0|327.67] "degree" Vector__XXX
 SG_ ObstacleVelXAbs_4A1h : 32|12@1+ (0.05,-102.4) [-102.4|102.35] "m/sec" Vector__XXX
 SG_ ObstacleVelYAbs_4A1h : 44|12@1+ (0.05,-50) [-50.0|50.0] "m/sec" Vector__XXX

BO_ 1186 ObstacleDataF15: 8 Matrix
 SG_ ObjCornerPointPoxX_4A2h : 0|13@1+ (0.0625,-250) [-250.0|250.0] "m" Vector__XXX
 SG_ CutInDistance_4A2h : 13|13@1+ (0.0625,-250) [-250.0|250.0] "m" Vector__XXX
 SG_ ObjCornerPointPoxY_4A2h : 26|13@1+ (0.0625,-250) [-250.0|250.0] "m" Vector__XXX
 SG_ ObstacleCurvature_4A2h : 39|15@1+ (1,-9999) [-9999.0|9999.0] "m" Vector__XXX

BO_ 1191 ObstacleDataA16: 8 Matrix
 SG_ ObstacleID_4A7h : 0|8@1+ (1,0) [0.0|255.0] "NA" Vector__XXX
 SG_ ObstacleValid_4A7h : 8|2@1+ (1,0) [0.0|3.0] "bool" Vector__XXX
 SG_ ObstacleReplaced_4A7h : 10|1@1+ (1,0) [0.0|1.0] "bool" Vector__XXX
 SG_ ObstacleAge_4A7h : 11|16@1+ (1,0) [0.0|65535.0] "NA" Vector__XXX
 SG_ ObstacleConfidence_4A7h : 27|7@1+ (1,0) [0.0|100.0] "NA" Vector__XXX
 SG_ ObstacleMotionCategory_4A7h : 34|4@1+ (1,0) [0.0|15.0] "enum" Vector__XXX
 SG_ ObstacleMotionStatus_4A7h : 38|3@1+ (1,0) [0.0|7.0] "enum" Vector__XXX
 SG_ ObstacleMeasuringStatus_4A7h : 41|3@1+ (1,0) [0.0|7.0] "enum" Vector__XXX
 SG_ ObstacleClass_4A7h : 44|3@1+ (1,0) [0.0|7.0] "enum" Vector__XXX
 SG_ VehicleSubType_4A7h : 47|3@1+ (1,0) [0.0|7.0] "enum" Vector__XXX
 SG_ PedSubType_4A7h : 50|2@1+ (1,0) [0.0|3.0] "enum" Vector__XXX
 SG_ PedPos_4A7h : 52|3@1+ (1,0) [0.0|7.0] "enum" Vector__XXX
 SG_ PedOrientation_4A7h : 55|4@1+ (1,0) [0.0|15.0] "enum" Vector__XXX
 SG_ ObstacleLaneAssignment_4A7h : 59|3@1+ (1,0) [0.0|7.0] "enum" Vector__XXX

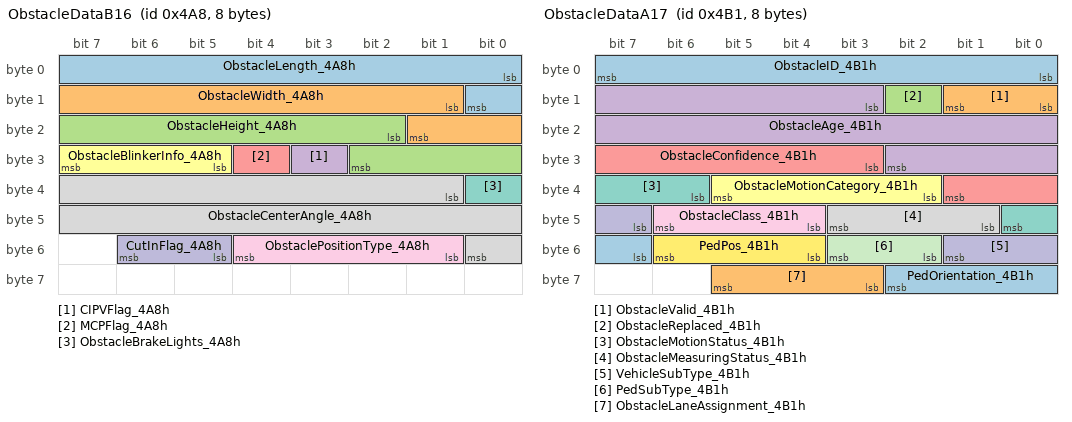
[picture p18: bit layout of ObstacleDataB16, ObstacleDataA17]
BO_ 1192 ObstacleDataB16: 8 Matrix
 SG_ ObstacleLength_4A8h : 0|9@1+ (0.05,0) [0.0|25.6] "m" Vector__XXX
 SG_ ObstacleWidth_4A8h : 9|9@1+ (0.02,0) [0.0|10.24] "m" Vector__XXX
 SG_ ObstacleHeight_4A8h : 18|9@1+ (0.02,0) [0.0|10.24] "m" Vector__XXX
 SG_ CIPVFlag_4A8h : 27|1@1+ (1,0) [0.0|1.0] "bool" Vector__XXX
 SG_ MCPFlag_4A8h : 28|1@1+ (1,0) [0.0|1.0] "bool" Vector__XXX
 SG_ ObstacleBlinkerInfo_4A8h : 29|3@1+ (1,0) [0.0|7.0] "enum" Vector__XXX
 SG_ ObstacleBrakeLights_4A8h : 32|1@1+ (1,0) [0.0|1.0] "bool" Vector__XXX
 SG_ ObstacleCenterAngle_4A8h : 33|16@1+ (0.01,-327.68) [-327.68|327.67] "degree" Vector__XXX
 SG_ ObstaclePositionType_4A8h : 49|4@1+ (1,0) [0.0|15.0] "enum" Vector__XXX
 SG_ CutInFlag_4A8h : 53|2@1+ (1,0) [0.0|3.0] "bool" Vector__XXX

BO_ 1193 ObstacleDataC16: 8 Matrix
 SG_ ObstaclePosX_4A9h : 0|13@1+ (0.0625,-250) [-250.0|250.0] "m" Vector__XXX
 SG_ ObstaclePosY_4A9h : 13|13@1+ (0.0625,-250) [-250.0|250.0] "m" Vector__XXX
 SG_ ObstacleVelX_4A9h : 26|12@1+ (0.05,-102.4) [-102.4|102.35] "m/sec" Vector__XXX
 SG_ ObstacleVelY_4A9h : 38|12@1+ (0.05,-50) [-50.0|50.0] "m/sec" Vector__XXX
 SG_ ObstacleAccX_4A9h : 50|10@1+ (0.03,-14.97) [-14.97|14.97] "m/s^2" Vector__XXX

BO_ 1194 ObstacleDataD16: 8 Matrix
 SG_ ObstaclePosXSTD_4AAh : 0|13@1+ (0.0625,0) [0.0|250.0] "m" Vector__XXX
 SG_ ObstaclePosYSTD_4AAh : 13|13@1+ (0.0625,0) [0.0|250.0] "m" Vector__XXX
 SG_ ObstacleVelXSTD_4AAh : 26|12@1+ (0.05,0) [0.0|102.35] "m/sec" Vector__XXX
 SG_ ObstacleVelYSTD_4AAh : 38|12@1+ (0.05,0) [0.0|50.0] "m/sec" Vector__XXX
 SG_ ObstacleAccY_4AAh : 50|10@1+ (0.03,-14.97) [-14.97|14.97] "m/s^2" Vector__XXX

BO_ 1195 ObstacleDataE16: 8 Matrix
 SG_ ObstacleAngle_4ABh : 0|16@1+ (0.01,-327.68) [-327.68|327.67] "degree" Vector__XXX
 SG_ ObstacleAngleStd_4ABh : 16|16@1+ (0.01,0) [0.0|327.67] "degree" Vector__XXX
 SG_ ObstacleVelXAbs_4ABh : 32|12@1+ (0.05,-102.4) [-102.4|102.35] "m/sec" Vector__XXX
 SG_ ObstacleVelYAbs_4ABh : 44|12@1+ (0.05,-50) [-50.0|50.0] "m/sec" Vector__XXX

BO_ 1196 ObstacleDataF16: 8 Matrix
 SG_ ObjCornerPointPoxX_4ACh : 0|13@1+ (0.0625,-250) [-250.0|250.0] "m" Vector__XXX
 SG_ CutInDistance_4ACh : 13|13@1+ (0.0625,-250) [-250.0|250.0] "m" Vector__XXX
 SG_ ObjCornerPointPoxY_4ACh : 26|13@1+ (0.0625,-250) [-250.0|250.0] "m" Vector__XXX
 SG_ ObstacleCurvature_4ACh : 39|15@1+ (1,-9999) [-9999.0|9999.0] "m" Vector__XXX

BO_ 1201 ObstacleDataA17: 8 Matrix
 SG_ ObstacleID_4B1h : 0|8@1+ (1,0) [0.0|255.0] "NA" Vector__XXX
 SG_ ObstacleValid_4B1h : 8|2@1+ (1,0) [0.0|3.0] "bool" Vector__XXX
 SG_ ObstacleReplaced_4B1h : 10|1@1+ (1,0) [0.0|1.0] "bool" Vector__XXX
 SG_ ObstacleAge_4B1h : 11|16@1+ (1,0) [0.0|65535.0] "NA" Vector__XXX
 SG_ ObstacleConfidence_4B1h : 27|7@1+ (1,0) [0.0|100.0] "NA" Vector__XXX
 SG_ ObstacleMotionCategory_4B1h : 34|4@1+ (1,0) [0.0|15.0] "enum" Vector__XXX
 SG_ ObstacleMotionStatus_4B1h : 38|3@1+ (1,0) [0.0|7.0] "enum" Vector__XXX
 SG_ ObstacleMeasuringStatus_4B1h : 41|3@1+ (1,0) [0.0|7.0] "enum" Vector__XXX
 SG_ ObstacleClass_4B1h : 44|3@1+ (1,0) [0.0|7.0] "enum" Vector__XXX
 SG_ VehicleSubType_4B1h : 47|3@1+ (1,0) [0.0|7.0] "enum" Vector__XXX
 SG_ PedSubType_4B1h : 50|2@1+ (1,0) [0.0|3.0] "enum" Vector__XXX
 SG_ PedPos_4B1h : 52|3@1+ (1,0) [0.0|7.0] "enum" Vector__XXX
 SG_ PedOrientation_4B1h : 55|4@1+ (1,0) [0.0|15.0] "enum" Vector__XXX
 SG_ ObstacleLaneAssignment_4B1h : 59|3@1+ (1,0) [0.0|7.0] "enum" Vector__XXX

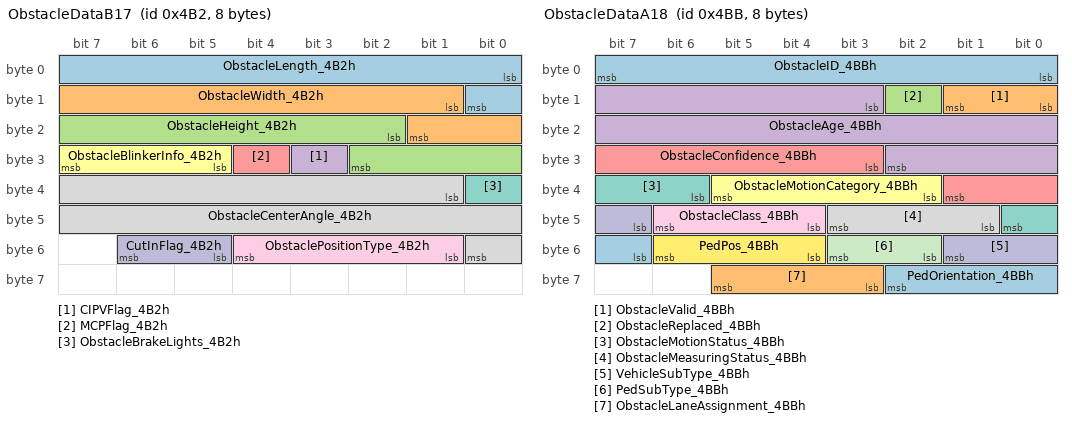
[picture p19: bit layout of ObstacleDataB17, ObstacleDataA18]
BO_ 1202 ObstacleDataB17: 8 Matrix
 SG_ ObstacleLength_4B2h : 0|9@1+ (0.05,0) [0.0|25.6] "m" Vector__XXX
 SG_ ObstacleWidth_4B2h : 9|9@1+ (0.02,0) [0.0|10.24] "m" Vector__XXX
 SG_ ObstacleHeight_4B2h : 18|9@1+ (0.02,0) [0.0|10.24] "m" Vector__XXX
 SG_ CIPVFlag_4B2h : 27|1@1+ (1,0) [0.0|1.0] "bool" Vector__XXX
 SG_ MCPFlag_4B2h : 28|1@1+ (1,0) [0.0|1.0] "bool" Vector__XXX
 SG_ ObstacleBlinkerInfo_4B2h : 29|3@1+ (1,0) [0.0|7.0] "enum" Vector__XXX
 SG_ ObstacleBrakeLights_4B2h : 32|1@1+ (1,0) [0.0|1.0] "bool" Vector__XXX
 SG_ ObstacleCenterAngle_4B2h : 33|16@1+ (0.01,-327.68) [-327.68|327.67] "degree" Vector__XXX
 SG_ ObstaclePositionType_4B2h : 49|4@1+ (1,0) [0.0|15.0] "enum" Vector__XXX
 SG_ CutInFlag_4B2h : 53|2@1+ (1,0) [0.0|3.0] "bool" Vector__XXX

BO_ 1203 ObstacleDataC17: 8 Matrix
 SG_ ObstaclePosX_4B3h : 0|13@1+ (0.0625,-250) [-250.0|250.0] "m" Vector__XXX
 SG_ ObstaclePosY_4B3h : 13|13@1+ (0.0625,-250) [-250.0|250.0] "m" Vector__XXX
 SG_ ObstacleVelX_4B3h : 26|12@1+ (0.05,-102.4) [-102.4|102.35] "m/sec" Vector__XXX
 SG_ ObstacleVelY_4B3h : 38|12@1+ (0.05,-50) [-50.0|50.0] "m/sec" Vector__XXX
 SG_ ObstacleAccX_4B3h : 50|10@1+ (0.03,-14.97) [-14.97|14.97] "m/s^2" Vector__XXX

BO_ 1204 ObstacleDataD17: 8 Matrix
 SG_ ObstaclePosXSTD_4B4h : 0|13@1+ (0.0625,0) [0.0|250.0] "m" Vector__XXX
 SG_ ObstaclePosYSTD_4B4h : 13|13@1+ (0.0625,0) [0.0|250.0] "m" Vector__XXX
 SG_ ObstacleVelXSTD_4B4h : 26|12@1+ (0.05,0) [0.0|102.35] "m/sec" Vector__XXX
 SG_ ObstacleVelYSTD_4B4h : 38|12@1+ (0.05,0) [0.0|50.0] "m/sec" Vector__XXX
 SG_ ObstacleAccY_4B4h : 50|10@1+ (0.03,-14.97) [-14.97|14.97] "m/s^2" Vector__XXX

BO_ 1205 ObstacleDataE17: 8 Matrix
 SG_ ObstacleAngle_4B5h : 0|16@1+ (0.01,-327.68) [-327.68|327.67] "degree" Vector__XXX
 SG_ ObstacleAngleStd_4B5h : 16|16@1+ (0.01,0) [0.0|327.67] "degree" Vector__XXX
 SG_ ObstacleVelXAbs_4B5h : 32|12@1+ (0.05,-102.4) [-102.4|102.35] "m/sec" Vector__XXX
 SG_ ObstacleVelYAbs_4B5h : 44|12@1+ (0.05,-50) [-50.0|50.0] "m/sec" Vector__XXX

BO_ 1206 ObstacleDataF17: 8 Matrix
 SG_ ObjCornerPointPoxX_4B6h : 0|13@1+ (0.0625,-250) [-250.0|250.0] "m" Vector__XXX
 SG_ CutInDistance_4B6h : 13|13@1+ (0.0625,-250) [-250.0|250.0] "m" Vector__XXX
 SG_ ObjCornerPointPoxY_4B6h : 26|13@1+ (0.0625,-250) [-250.0|250.0] "m" Vector__XXX
 SG_ ObstacleCurvature_4B6h : 39|15@1+ (1,-9999) [-9999.0|9999.0] "m" Vector__XXX

BO_ 1211 ObstacleDataA18: 8 Matrix
 SG_ ObstacleID_4BBh : 0|8@1+ (1,0) [0.0|255.0] "NA" Vector__XXX
 SG_ ObstacleValid_4BBh : 8|2@1+ (1,0) [0.0|3.0] "bool" Vector__XXX
 SG_ ObstacleReplaced_4BBh : 10|1@1+ (1,0) [0.0|1.0] "bool" Vector__XXX
 SG_ ObstacleAge_4BBh : 11|16@1+ (1,0) [0.0|65535.0] "NA" Vector__XXX
 SG_ ObstacleConfidence_4BBh : 27|7@1+ (1,0) [0.0|100.0] "NA" Vector__XXX
 SG_ ObstacleMotionCategory_4BBh : 34|4@1+ (1,0) [0.0|15.0] "enum" Vector__XXX
 SG_ ObstacleMotionStatus_4BBh : 38|3@1+ (1,0) [0.0|7.0] "enum" Vector__XXX
 SG_ ObstacleMeasuringStatus_4BBh : 41|3@1+ (1,0) [0.0|7.0] "enum" Vector__XXX
 SG_ ObstacleClass_4BBh : 44|3@1+ (1,0) [0.0|7.0] "enum" Vector__XXX
 SG_ VehicleSubType_4BBh : 47|3@1+ (1,0) [0.0|7.0] "enum" Vector__XXX
 SG_ PedSubType_4BBh : 50|2@1+ (1,0) [0.0|3.0] "enum" Vector__XXX
 SG_ PedPos_4BBh : 52|3@1+ (1,0) [0.0|7.0] "enum" Vector__XXX
 SG_ PedOrientation_4BBh : 55|4@1+ (1,0) [0.0|15.0] "enum" Vector__XXX
 SG_ ObstacleLaneAssignment_4BBh : 59|3@1+ (1,0) [0.0|7.0] "enum" Vector__XXX

CM_ SG_ 1024 ImageTimestamp_400h "The time gives the image timestamp when completed in J2";
CM_ SG_ 1025 SPITimestamp_401h "The time gives the SPI timestamp when completed in J2";
CM_ SG_ 1026 FrameIndex_402h "Image Frame Counter";
CM_ SG_ 1026 CameraID_402h "The camera id in order to distinguish between different cameras and and consistent with the structured output of CANFD";
CM_ SG_ 1026 ProtocolMajorVersion_402h "Major Version of Protocol";
CM_ SG_ 1026 ProtocolMinorVersion_402h "Minor Version of Protocol";
CM_ SG_ 1040 NumObstacles_410h "Number of obstacles";
CM_ SG_ 1040 ID_CIPV_410h "CIPV";
CM_ SG_ 1040 ID_MCP_410h "MCP";
CM_ SG_ 1040 CIPV_TTC_410h "CIPV TTC";
CM_ SG_ 1040 CIPV_TTC_Valid_410h "Validity bit for CIPV_TTC Signal TTC only valid for CIPV.";
CM_ SG_ 1040 MCP_TTC_410h "MCP TTC";
CM_ SG_ 1040 MCP_TTC_Valid_410h "Validity bit for MCP_TTC Signal";
CM_ SG_ 1040 ProtocolMajorVersion_410h "Major Version of Protocol";
CM_ SG_ 1040 ProtocolMinorVersion_410h "Minor Version of Protocol";
CM_ SG_ 1041 ObstacleID_411h "The detected OBJ ID";
CM_ SG_ 1041 ObstacleValid_411h "Obstacle Valid info";
CM_ SG_ 1041 ObstacleReplaced_411h "Reserved";
CM_ SG_ 1041 ObstacleAge_411h "Frame age of obstacle";
CM_ SG_ 1041 ObstacleConfidence_411h "Existence probability of Obstacle";
CM_ SG_ 1041 ObstacleMotionCategory_411h "The signal is based on our estimation of where the target is now relatively to the lanes, its rate of change, and our estimation of where it is going to be within one second.";
CM_ SG_ 1041 ObstacleMotionStatus_411h "The target is moving or stopped";
CM_ SG_ 1041 ObstacleMeasuringStatus_411h "Were measurements predicted, old, or not valid";
CM_ SG_ 1041 ObstacleClass_411h "Kind of object.";
CM_ SG_ 1041 VehicleSubType_411h "Vehicle Sub type";
CM_ SG_ 1041 PedSubType_411h "Pedestrian Sub type";
CM_ SG_ 1041 PedPos_411h "Pedestrian Position";
CM_ SG_ 1041 PedOrientation_411h "Pedestrian Orientation";
CM_ SG_ 1041 ObstacleLaneAssignment_411h "Obstacle Lane Assignment £¨Which lane a vehicle belongs to£©";
CM_ SG_ 1042 ObstacleLength_412h "Length";
CM_ SG_ 1042 ObstacleWidth_412h "Width";
CM_ SG_ 1042 ObstacleHeight_412h "Height";
CM_ SG_ 1042 CIPVFlag_412h "0 - not CIPV 1 - CIPV";
CM_ SG_ 1042 MCPFlag_412h "0 - not MCP 1 - MCP";
CM_ SG_ 1042 ObstacleBlinkerInfo_412h "Blinker Info";
CM_ SG_ 1042 ObstacleBrakeLights_412h "BrakeLightInfo";
CM_ SG_ 1042 ObstacleCenterAngle_412h "The Angle Between the orientation of Host Vehicle and the orientation from the front center of Host Vehicle  to the Reference Point of the target";
CM_ SG_ 1042 ObstaclePositionType_412h "Were measurements predicted, old, or not valid";
CM_ SG_ 1042 CutInFlag_412h "0 - not CIPV 1 - CIPV";
CM_ SG_ 1043 ObstaclePosX_413h "The longitudinal distance to the middle of the RL and RR corners";
CM_ SG_ 1043 ObstaclePosY_413h "The lateral distance to the middle of the RL and RR corners";
CM_ SG_ 1043 ObstacleVelX_413h "The relative longitude velocity of the obstacle.";
CM_ SG_ 1043 ObstacleVelY_413h "The relative lateral velocity of the obstacle.";
CM_ SG_ 1043 ObstacleAccX_413h "The longitude relative acceleration of the object.";
CM_ SG_ 1044 ObstaclePosXSTD_414h "the standard deviation of longitudinal distance to the middle of the RL and RR corners";
CM_ SG_ 1044 ObstaclePosYSTD_414h "the standard deviation of lateral distance to the middle of the RL and RR corners";
CM_ SG_ 1044 ObstacleVelXSTD_414h "the standard deviation of longitude velocity of the obstacle.";
CM_ SG_ 1044 ObstacleVelYSTD_414h "the standard deviation of  lateral velocity of the obstacle.";
CM_ SG_ 1044 ObstacleAccY_414h "The lateral relative acceleration of the object.";
CM_ SG_ 1045 ObstacleAngle_415h "the heading angle of vehicle";
CM_ SG_ 1045 ObstacleAngleStd_415h "the standard deviation of heading angle of vehicle";
CM_ SG_ 1045 ObstacleVelXAbs_415h "the absolute longitude velocity of the obstacle.";
CM_ SG_ 1045 ObstacleVelYAbs_415h "the absolute lateral velocity of the obstacle.";
CM_ SG_ 1046 ObjCornerPointPoxX_416h "The longitudinal distance to the middle of the RL and RR corners";
CM_ SG_ 1046 CutInDistance_416h "The lateral distance to the middle of the RL and RR corners";
CM_ SG_ 1046 ObjCornerPointPoxY_416h "The longitudinal distance to the middle of the RL and RR corners";
CM_ SG_ 1046 ObstacleCurvature_416h "The lateral distance to the middle of the RL and RR corners";
CM_ SG_ 1051 ObstacleID_41Bh "The detected OBJ ID";
CM_ SG_ 1051 ObstacleValid_41Bh "Obstacle Valid info";
CM_ SG_ 1051 ObstacleReplaced_41Bh "Reserved";
CM_ SG_ 1051 ObstacleAge_41Bh "Frame age of obstacle";
CM_ SG_ 1051 ObstacleConfidence_41Bh "Existence probability of Obstacle";
CM_ SG_ 1051 ObstacleMotionCategory_41Bh "The signal is based on our estimation of where the target is now relatively to the lanes, its rate of change, and our estimation of where it is going to be within one second.";
CM_ SG_ 1051 ObstacleMotionStatus_41Bh "The target is moving or stopped";
CM_ SG_ 1051 ObstacleMeasuringStatus_41Bh "Were measurements predicted, old, or not valid";
CM_ SG_ 1051 ObstacleClass_41Bh "Kind of object.";
CM_ SG_ 1051 VehicleSubType_41Bh "Vehicle Sub type";
CM_ SG_ 1051 PedSubType_41Bh "Pedestrian Sub type";
CM_ SG_ 1051 PedPos_41Bh "Pedestrian Position";
CM_ SG_ 1051 PedOrientation_41Bh "Pedestrian Orientation";
CM_ SG_ 1051 ObstacleLaneAssignment_41Bh "Obstacle Lane Assignment £¨Which lane a vehicle belongs to£©";
CM_ SG_ 1052 ObstacleLength_41Ch "Length";
CM_ SG_ 1052 ObstacleWidth_41Ch "Width";
CM_ SG_ 1052 ObstacleHeight_41Ch "Height";
CM_ SG_ 1052 CIPVFlag_41Ch "0 - not CIPV 1 - CIPV";
CM_ SG_ 1052 MCPFlag_41Ch "0 - not MCP 1 - MCP";
CM_ SG_ 1052 ObstacleBlinkerInfo_41Ch "Blinker Info";
CM_ SG_ 1052 ObstacleBrakeLights_41Ch "BrakeLightInfo";
CM_ SG_ 1052 ObstacleCenterAngle_41Ch "The Angle Between the orientation of Host Vehicle and the orientation from the front center of Host Vehicle  to the Reference Point of the target";
CM_ SG_ 1052 ObstaclePositionType_41Ch "Were measurements predicted, old, or not valid";
CM_ SG_ 1052 CutInFlag_41Ch "0 - not CIPV 1 - CIPV";
CM_ SG_ 1053 ObstaclePosX_41Dh "The longitudinal distance to the middle of the RL and RR corners";
CM_ SG_ 1053 ObstaclePosY_41Dh "The lateral distance to the middle of the RL and RR corners";
CM_ SG_ 1053 ObstacleVelX_41Dh "The relative longitude velocity of the obstacle.";
CM_ SG_ 1053 ObstacleVelY_41Dh "The relative lateral velocity of the obstacle.";
CM_ SG_ 1053 ObstacleAccX_41Dh "The longitude relative acceleration of the object.";
CM_ SG_ 1054 ObstaclePosXSTD_41Eh "the standard deviation of longitudinal distance to the middle of the RL and RR corners";
CM_ SG_ 1054 ObstaclePosYSTD_41Eh "the standard deviation of lateral distance to the middle of the RL and RR corners";
CM_ SG_ 1054 ObstacleVelXSTD_41Eh "the standard deviation of longitude velocity of the obstacle.";
CM_ SG_ 1054 ObstacleVelYSTD_41Eh "the standard deviation of  lateral velocity of the obstacle.";
CM_ SG_ 1054 ObstacleAccY_41Eh "The lateral relative acceleration of the object.";
CM_ SG_ 1055 ObstacleAngle_41Fh "the heading angle of vehicle";
CM_ SG_ 1055 ObstacleAngleStd_41Fh "the standard deviation of heading angle of vehicle";
CM_ SG_ 1055 ObstacleVelXAbs_41Fh "the absolute longitude velocity of the obstacle.";
CM_ SG_ 1055 ObstacleVelYAbs_41Fh "the absolute lateral velocity of the obstacle.";
CM_ SG_ 1056 ObjCornerPointPoxX_420h "The longitudinal distance to the middle of the RL and RR corners";
CM_ SG_ 1056 CutInDistance_420h "The lateral distance to the middle of the RL and RR corners";
CM_ SG_ 1056 ObjCornerPointPoxY_420h "The longitudinal distance to the middle of the RL and RR corners";
CM_ SG_ 1056 ObstacleCurvature_420h "The lateral distance to the middle of the RL and RR corners";
CM_ SG_ 1061 ObstacleID_425h "The detected OBJ ID";
CM_ SG_ 1061 ObstacleValid_425h "Obstacle Valid info";
CM_ SG_ 1061 ObstacleReplaced_425h "Reserved";
CM_ SG_ 1061 ObstacleAge_425h "Frame age of obstacle";
CM_ SG_ 1061 ObstacleConfidence_425h "Existence probability of Obstacle";
CM_ SG_ 1061 ObstacleMotionCategory_425h "The signal is based on our estimation of where the target is now relatively to the lanes, its rate of change, and our estimation of where it is going to be within one second.";
CM_ SG_ 1061 ObstacleMotionStatus_425h "The target is moving or stopped";
CM_ SG_ 1061 ObstacleMeasuringStatus_425h "Were measurements predicted, old, or not valid";
CM_ SG_ 1061 ObstacleClass_425h "Kind of object.";
CM_ SG_ 1061 VehicleSubType_425h "Vehicle Sub type";
CM_ SG_ 1061 PedSubType_425h "Pedestrian Sub type";
CM_ SG_ 1061 PedPos_425h "Pedestrian Position";
CM_ SG_ 1061 PedOrientation_425h "Pedestrian Orientation";
CM_ SG_ 1061 ObstacleLaneAssignment_425h "Obstacle Lane Assignment £¨Which lane a vehicle belongs to£©";
CM_ SG_ 1062 ObstacleLength_426h "Length";
CM_ SG_ 1062 ObstacleWidth_426h "Width";
CM_ SG_ 1062 ObstacleHeight_426h "Height";
CM_ SG_ 1062 CIPVFlag_426h "0 - not CIPV 1 - CIPV";
CM_ SG_ 1062 MCPFlag_426h "0 - not MCP 1 - MCP";
CM_ SG_ 1062 ObstacleBlinkerInfo_426h "Blinker Info";
CM_ SG_ 1062 ObstacleBrakeLights_426h "BrakeLightInfo";
CM_ SG_ 1062 ObstacleCenterAngle_426h "The Angle Between the orientation of Host Vehicle and the orientation from the front center of Host Vehicle  to the Reference Point of the target";
CM_ SG_ 1062 ObstaclePositionType_426h "Were measurements predicted, old, or not valid";
CM_ SG_ 1062 CutInFlag_426h "0 - not CIPV 1 - CIPV";
CM_ SG_ 1063 ObstaclePosX_427h "The longitudinal distance to the middle of the RL and RR corners";
CM_ SG_ 1063 ObstaclePosY_427h "The lateral distance to the middle of the RL and RR corners";
CM_ SG_ 1063 ObstacleVelX_427h "The relative longitude velocity of the obstacle.";
CM_ SG_ 1063 ObstacleVelY_427h "The relative lateral velocity of the obstacle.";
CM_ SG_ 1063 ObstacleAccX_427h "The longitude relative acceleration of the object.";
CM_ SG_ 1064 ObstaclePosXSTD_428h "the standard deviation of longitudinal distance to the middle of the RL and RR corners";
CM_ SG_ 1064 ObstaclePosYSTD_428h "the standard deviation of lateral distance to the middle of the RL and RR corners";
CM_ SG_ 1064 ObstacleVelXSTD_428h "the standard deviation of longitude velocity of the obstacle.";
CM_ SG_ 1064 ObstacleVelYSTD_428h "the standard deviation of  lateral velocity of the obstacle.";
CM_ SG_ 1064 ObstacleAccY_428h "The lateral relative acceleration of the object.";
CM_ SG_ 1065 ObstacleAngle_429h "the heading angle of vehicle";
CM_ SG_ 1065 ObstacleAngleStd_429h "the standard deviation of heading angle of vehicle";
CM_ SG_ 1065 ObstacleVelXAbs_429h "the absolute longitude velocity of the obstacle.";
CM_ SG_ 1065 ObstacleVelYAbs_429h "the absolute lateral velocity of the obstacle.";
CM_ SG_ 1066 ObjCornerPointPoxX_42Ah "The longitudinal distance to the middle of the RL and RR corners";
CM_ SG_ 1066 CutInDistance_42Ah "The lateral distance to the middle of the RL and RR corners";
CM_ SG_ 1066 ObjCornerPointPoxY_42Ah "The longitudinal distance to the middle of the RL and RR corners";
CM_ SG_ 1066 ObstacleCurvature_42Ah "The lateral distance to the middle of the RL and RR corners";
CM_ SG_ 1071 ObstacleID_42Fh "The detected OBJ ID";
CM_ SG_ 1071 ObstacleValid_42Fh "Obstacle Valid info";
CM_ SG_ 1071 ObstacleReplaced_42Fh "Reserved";
CM_ SG_ 1071 ObstacleAge_42Fh "Frame age of obstacle";
CM_ SG_ 1071 ObstacleConfidence_42Fh "Existence probability of Obstacle";
CM_ SG_ 1071 ObstacleMotionCategory_42Fh "The signal is based on our estimation of where the target is now relatively to the lanes, its rate of change, and our estimation of where it is going to be within one second.";
CM_ SG_ 1071 ObstacleMotionStatus_42Fh "The target is moving or stopped";
CM_ SG_ 1071 ObstacleMeasuringStatus_42Fh "Were measurements predicted, old, or not valid";
CM_ SG_ 1071 ObstacleClass_42Fh "Kind of object.";
CM_ SG_ 1071 VehicleSubType_42Fh "Vehicle Sub type";
CM_ SG_ 1071 PedSubType_42Fh "Pedestrian Sub type";
CM_ SG_ 1071 PedPos_42Fh "Pedestrian Position";
CM_ SG_ 1071 PedOrientation_42Fh "Pedestrian Orientation";
CM_ SG_ 1071 ObstacleLaneAssignment_42Fh "Obstacle Lane Assignment £¨Which lane a vehicle belongs to£©";
CM_ SG_ 1072 ObstacleLength_430h "Length";
CM_ SG_ 1072 ObstacleWidth_430h "Width";
CM_ SG_ 1072 ObstacleHeight_430h "Height";
CM_ SG_ 1072 CIPVFlag_430h "0 - not CIPV 1 - CIPV";
CM_ SG_ 1072 MCPFlag_430h "0 - not MCP 1 - MCP";
CM_ SG_ 1072 ObstacleBlinkerInfo_430h "Blinker Info";
CM_ SG_ 1072 ObstacleBrakeLights_430h "BrakeLightInfo";
CM_ SG_ 1072 ObstacleCenterAngle_430h "The Angle Between the orientation of Host Vehicle and the orientation from the front center of Host Vehicle  to the Reference Point of the target";
CM_ SG_ 1072 ObstaclePositionType_430h "Were measurements predicted, old, or not valid";
CM_ SG_ 1072 CutInFlag_430h "0 - not CIPV 1 - CIPV";
CM_ SG_ 1073 ObstaclePosX_431h "The longitudinal distance to the middle of the RL and RR corners";
CM_ SG_ 1073 ObstaclePosY_431h "The lateral distance to the middle of the RL and RR corners";
CM_ SG_ 1073 ObstacleVelX_431h "The relative longitude velocity of the obstacle.";
CM_ SG_ 1073 ObstacleVelY_431h "The relative lateral velocity of the obstacle.";
CM_ SG_ 1073 ObstacleAccX_431h "The longitude relative acceleration of the object.";
CM_ SG_ 1074 ObstaclePosXSTD_432h "the standard deviation of longitudinal distance to the middle of the RL and RR corners";
CM_ SG_ 1074 ObstaclePosYSTD_432h "the standard deviation of lateral distance to the middle of the RL and RR corners";
CM_ SG_ 1074 ObstacleVelXSTD_432h "the standard deviation of longitude velocity of the obstacle.";
CM_ SG_ 1074 ObstacleVelYSTD_432h "the standard deviation of  lateral velocity of the obstacle.";
CM_ SG_ 1074 ObstacleAccY_432h "The lateral relative acceleration of the object.";
CM_ SG_ 1075 ObstacleAngle_433h "the heading angle of vehicle";
CM_ SG_ 1075 ObstacleAngleStd_433h "the standard deviation of heading angle of vehicle";
CM_ SG_ 1075 ObstacleVelXAbs_433h "the absolute longitude velocity of the obstacle.";
CM_ SG_ 1075 ObstacleVelYAbs_433h "the absolute lateral velocity of the obstacle.";
CM_ SG_ 1076 ObjCornerPointPoxX_434h "The longitudinal distance to the middle of the RL and RR corners";
CM_ SG_ 1076 CutInDistance_434h "The lateral distance to the middle of the RL and RR corners";
CM_ SG_ 1076 ObjCornerPointPoxY_434h "The longitudinal distance to the middle of the RL and RR corners";
CM_ SG_ 1076 ObstacleCurvature_434h "The lateral distance to the middle of the RL and RR corners";
CM_ SG_ 1081 ObstacleID_439h "The detected OBJ ID";
CM_ SG_ 1081 ObstacleValid_439h "Obstacle Valid info";
CM_ SG_ 1081 ObstacleReplaced_439h "Reserved";
CM_ SG_ 1081 ObstacleAge_439h "Frame age of obstacle";
CM_ SG_ 1081 ObstacleConfidence_439h "Existence probability of Obstacle";
CM_ SG_ 1081 ObstacleMotionCategory_439h "The signal is based on our estimation of where the target is now relatively to the lanes, its rate of change, and our estimation of where it is going to be within one second.";
CM_ SG_ 1081 ObstacleMotionStatus_439h "The target is moving or stopped";
CM_ SG_ 1081 ObstacleMeasuringStatus_439h "Were measurements predicted, old, or not valid";
CM_ SG_ 1081 ObstacleClass_439h "Kind of object.";
CM_ SG_ 1081 VehicleSubType_439h "Vehicle Sub type";
CM_ SG_ 1081 PedSubType_439h "Pedestrian Sub type";
CM_ SG_ 1081 PedPos_439h "Pedestrian Position";
CM_ SG_ 1081 PedOrientation_439h "Pedestrian Orientation";
CM_ SG_ 1081 ObstacleLaneAssignment_439h "Obstacle Lane Assignment £¨Which lane a vehicle belongs to£©";
CM_ SG_ 1082 ObstacleLength_43Ah "Length";
CM_ SG_ 1082 ObstacleWidth_43Ah "Width";
CM_ SG_ 1082 ObstacleHeight_43Ah "Height";
CM_ SG_ 1082 CIPVFlag_43Ah "0 - not CIPV 1 - CIPV";
CM_ SG_ 1082 MCPFlag_43Ah "0 - not MCP 1 - MCP";
CM_ SG_ 1082 ObstacleBlinkerInfo_43Ah "Blinker Info";
CM_ SG_ 1082 ObstacleBrakeLights_43Ah "BrakeLightInfo";
CM_ SG_ 1082 ObstacleCenterAngle_43Ah "The Angle Between the orientation of Host Vehicle and the orientation from the front center of Host Vehicle  to the Reference Point of the target";
CM_ SG_ 1082 ObstaclePositionType_43Ah "Were measurements predicted, old, or not valid";
CM_ SG_ 1082 CutInFlag_43Ah "0 - not CIPV 1 - CIPV";
CM_ SG_ 1083 ObstaclePosX_43Bh "The longitudinal distance to the middle of the RL and RR corners";
CM_ SG_ 1083 ObstaclePosY_43Bh "The lateral distance to the middle of the RL and RR corners";
CM_ SG_ 1083 ObstacleVelX_43Bh "The relative longitude velocity of the obstacle.";
CM_ SG_ 1083 ObstacleVelY_43Bh "The relative lateral velocity of the obstacle.";
CM_ SG_ 1083 ObstacleAccX_43Bh "The longitude relative acceleration of the object.";
CM_ SG_ 1084 ObstaclePosXSTD_43Ch "the standard deviation of longitudinal distance to the middle of the RL and RR corners";
CM_ SG_ 1084 ObstaclePosYSTD_43Ch "the standard deviation of lateral distance to the middle of the RL and RR corners";
CM_ SG_ 1084 ObstacleVelXSTD_43Ch "the standard deviation of longitude velocity of the obstacle.";
CM_ SG_ 1084 ObstacleVelYSTD_43Ch "the standard deviation of  lateral velocity of the obstacle.";
CM_ SG_ 1084 ObstacleAccY_43Ch "The lateral relative acceleration of the object.";
CM_ SG_ 1085 ObstacleAngle_43Dh "the heading angle of vehicle";
CM_ SG_ 1085 ObstacleAngleStd_43Dh "the standard deviation of heading angle of vehicle";
CM_ SG_ 1085 ObstacleVelXAbs_43Dh "the absolute longitude velocity of the obstacle.";
CM_ SG_ 1085 ObstacleVelYAbs_43Dh "the absolute lateral velocity of the obstacle.";
CM_ SG_ 1086 ObjCornerPointPoxX_43Eh "The longitudinal distance to the middle of the RL and RR corners";
CM_ SG_ 1086 CutInDistance_43Eh "The lateral distance to the middle of the RL and RR corners";
CM_ SG_ 1086 ObjCornerPointPoxY_43Eh "The longitudinal distance to the middle of the RL and RR corners";
CM_ SG_ 1086 ObstacleCurvature_43Eh "The lateral distance to the middle of the RL and RR corners";
CM_ SG_ 1091 ObstacleID_443h "The detected OBJ ID";
CM_ SG_ 1091 ObstacleValid_443h "Obstacle Valid info";
CM_ SG_ 1091 ObstacleReplaced_443h "Reserved";
CM_ SG_ 1091 ObstacleAge_443h "Frame age of obstacle";
CM_ SG_ 1091 ObstacleConfidence_443h "Existence probability of Obstacle";
CM_ SG_ 1091 ObstacleMotionCategory_443h "The signal is based on our estimation of where the target is now relatively to the lanes, its rate of change, and our estimation of where it is going to be within one second.";
CM_ SG_ 1091 ObstacleMotionStatus_443h "The target is moving or stopped";
CM_ SG_ 1091 ObstacleMeasuringStatus_443h "Were measurements predicted, old, or not valid";
CM_ SG_ 1091 ObstacleClass_443h "Kind of object.";
CM_ SG_ 1091 VehicleSubType_443h "Vehicle Sub type";
CM_ SG_ 1091 PedSubType_443h "Pedestrian Sub type";
CM_ SG_ 1091 PedPos_443h "Pedestrian Position";
CM_ SG_ 1091 PedOrientation_443h "Pedestrian Orientation";
CM_ SG_ 1091 ObstacleLaneAssignment_443h "Obstacle Lane Assignment £¨Which lane a vehicle belongs to£©";
CM_ SG_ 1092 ObstacleLength_444h "Length";
CM_ SG_ 1092 ObstacleWidth_444h "Width";
CM_ SG_ 1092 ObstacleHeight_444h "Height";
CM_ SG_ 1092 CIPVFlag_444h "0 - not CIPV 1 - CIPV";
CM_ SG_ 1092 MCPFlag_444h "0 - not MCP 1 - MCP";
CM_ SG_ 1092 ObstacleBlinkerInfo_444h "Blinker Info";
CM_ SG_ 1092 ObstacleBrakeLights_444h "BrakeLightInfo";
CM_ SG_ 1092 ObstacleCenterAngle_444h "The Angle Between the orientation of Host Vehicle and the orientation from the front center of Host Vehicle  to the Reference Point of the target";
CM_ SG_ 1092 ObstaclePositionType_444h "Were measurements predicted, old, or not valid";
CM_ SG_ 1092 CutInFlag_444h "0 - not CIPV 1 - CIPV";
CM_ SG_ 1093 ObstaclePosX_445h "The longitudinal distance to the middle of the RL and RR corners";
CM_ SG_ 1093 ObstaclePosY_445h "The lateral distance to the middle of the RL and RR corners";
CM_ SG_ 1093 ObstacleVelX_445h "The relative longitude velocity of the obstacle.";
CM_ SG_ 1093 ObstacleVelY_445h "The relative lateral velocity of the obstacle.";
CM_ SG_ 1093 ObstacleAccX_445h "The longitude relative acceleration of the object.";
CM_ SG_ 1094 ObstaclePosXSTD_446h "the standard deviation of longitudinal distance to the middle of the RL and RR corners";
CM_ SG_ 1094 ObstaclePosYSTD_446h "the standard deviation of lateral distance to the middle of the RL and RR corners";
CM_ SG_ 1094 ObstacleVelXSTD_446h "the standard deviation of longitude velocity of the obstacle.";
CM_ SG_ 1094 ObstacleVelYSTD_446h "the standard deviation of  lateral velocity of the obstacle.";
CM_ SG_ 1094 ObstacleAccY_446h "The lateral relative acceleration of the object.";
CM_ SG_ 1095 ObstacleAngle_447h "the heading angle of vehicle";
CM_ SG_ 1095 ObstacleAngleStd_447h "the standard deviation of heading angle of vehicle";
CM_ SG_ 1095 ObstacleVelXAbs_447h "the absolute longitude velocity of the obstacle.";
CM_ SG_ 1095 ObstacleVelYAbs_447h "the absolute lateral velocity of the obstacle.";
CM_ SG_ 1096 ObjCornerPointPoxX_448h "The longitudinal distance to the middle of the RL and RR corners";
CM_ SG_ 1096 CutInDistance_448h "The lateral distance to the middle of the RL and RR corners";
CM_ SG_ 1096 ObjCornerPointPoxY_448h "The longitudinal distance to the middle of the RL and RR corners";
CM_ SG_ 1096 ObstacleCurvature_448h "The lateral distance to the middle of the RL and RR corners";
CM_ SG_ 1101 ObstacleID_44Dh "The detected OBJ ID";
CM_ SG_ 1101 ObstacleValid_44Dh "Obstacle Valid info";
CM_ SG_ 1101 ObstacleReplaced_44Dh "Reserved";
CM_ SG_ 1101 ObstacleAge_44Dh "Frame age of obstacle";
CM_ SG_ 1101 ObstacleConfidence_44Dh "Existence probability of Obstacle";
CM_ SG_ 1101 ObstacleMotionCategory_44Dh "The signal is based on our estimation of where the target is now relatively to the lanes, its rate of change, and our estimation of where it is going to be within one second.";
CM_ SG_ 1101 ObstacleMotionStatus_44Dh "The target is moving or stopped";
CM_ SG_ 1101 ObstacleMeasuringStatus_44Dh "Were measurements predicted, old, or not valid";
CM_ SG_ 1101 ObstacleClass_44Dh "Kind of object.";
CM_ SG_ 1101 VehicleSubType_44Dh "Vehicle Sub type";
CM_ SG_ 1101 PedSubType_44Dh "Pedestrian Sub type";
CM_ SG_ 1101 PedPos_44Dh "Pedestrian Position";
CM_ SG_ 1101 PedOrientation_44Dh "Pedestrian Orientation";
CM_ SG_ 1101 ObstacleLaneAssignment_44Dh "Obstacle Lane Assignment £¨Which lane a vehicle belongs to£©";
CM_ SG_ 1102 ObstacleLength_44Eh "Length";
CM_ SG_ 1102 ObstacleWidth_44Eh "Width";
CM_ SG_ 1102 ObstacleHeight_44Eh "Height";
CM_ SG_ 1102 CIPVFlag_44Eh "0 - not CIPV 1 - CIPV";
CM_ SG_ 1102 MCPFlag_44Eh "0 - not MCP 1 - MCP";
CM_ SG_ 1102 ObstacleBlinkerInfo_44Eh "Blinker Info";
CM_ SG_ 1102 ObstacleBrakeLights_44Eh "BrakeLightInfo";
CM_ SG_ 1102 ObstacleCenterAngle_44Eh "The Angle Between the orientation of Host Vehicle and the orientation from the front center of Host Vehicle  to the Reference Point of the target";
CM_ SG_ 1102 ObstaclePositionType_44Eh "Were measurements predicted, old, or not valid";
CM_ SG_ 1102 CutInFlag_44Eh "0 - not CIPV 1 - CIPV";
CM_ SG_ 1103 ObstaclePosX_44Fh "The longitudinal distance to the middle of the RL and RR corners";
CM_ SG_ 1103 ObstaclePosY_44Fh "The lateral distance to the middle of the RL and RR corners";
CM_ SG_ 1103 ObstacleVelX_44Fh "The relative longitude velocity of the obstacle.";
CM_ SG_ 1103 ObstacleVelY_44Fh "The relative lateral velocity of the obstacle.";
CM_ SG_ 1103 ObstacleAccX_44Fh "The longitude relative acceleration of the object.";
CM_ SG_ 1104 ObstaclePosXSTD_450h "the standard deviation of longitudinal distance to the middle of the RL and RR corners";
CM_ SG_ 1104 ObstaclePosYSTD_450h "the standard deviation of lateral distance to the middle of the RL and RR corners";
CM_ SG_ 1104 ObstacleVelXSTD_450h "the standard deviation of longitude velocity of the obstacle.";
CM_ SG_ 1104 ObstacleVelYSTD_450h "the standard deviation of  lateral velocity of the obstacle.";
CM_ SG_ 1104 ObstacleAccY_450h "The lateral relative acceleration of the object.";
CM_ SG_ 1105 ObstacleAngle_451h "the heading angle of vehicle";
CM_ SG_ 1105 ObstacleAngleStd_451h "the standard deviation of heading angle of vehicle";
CM_ SG_ 1105 ObstacleVelXAbs_451h "the absolute longitude velocity of the obstacle.";
CM_ SG_ 1105 ObstacleVelYAbs_451h "the absolute lateral velocity of the obstacle.";
CM_ SG_ 1106 ObjCornerPointPoxX_452h "The longitudinal distance to the middle of the RL and RR corners";
CM_ SG_ 1106 CutInDistance_452h "The lateral distance to the middle of the RL and RR corners";
CM_ SG_ 1106 ObjCornerPointPoxY_452h "The longitudinal distance to the middle of the RL and RR corners";
CM_ SG_ 1106 ObstacleCurvature_452h "The lateral distance to the middle of the RL and RR corners";
CM_ SG_ 1111 ObstacleID_457h "The detected OBJ ID";
CM_ SG_ 1111 ObstacleValid_457h "Obstacle Valid info";
CM_ SG_ 1111 ObstacleReplaced_457h "Reserved";
CM_ SG_ 1111 ObstacleAge_457h "Frame age of obstacle";
CM_ SG_ 1111 ObstacleConfidence_457h "Existence probability of Obstacle";
CM_ SG_ 1111 ObstacleMotionCategory_457h "The signal is based on our estimation of where the target is now relatively to the lanes, its rate of change, and our estimation of where it is going to be within one second.";
CM_ SG_ 1111 ObstacleMotionStatus_457h "The target is moving or stopped";
CM_ SG_ 1111 ObstacleMeasuringStatus_457h "Were measurements predicted, old, or not valid";
CM_ SG_ 1111 ObstacleClass_457h "Kind of object.";
CM_ SG_ 1111 VehicleSubType_457h "Vehicle Sub type";
CM_ SG_ 1111 PedSubType_457h "Pedestrian Sub type";
CM_ SG_ 1111 PedPos_457h "Pedestrian Position";
CM_ SG_ 1111 PedOrientation_457h "Pedestrian Orientation";
CM_ SG_ 1111 ObstacleLaneAssignment_457h "Obstacle Lane Assignment £¨Which lane a vehicle belongs to£©";
CM_ SG_ 1112 ObstacleLength_458h "Length";
CM_ SG_ 1112 ObstacleWidth_458h "Width";
CM_ SG_ 1112 ObstacleHeight_458h "Height";
CM_ SG_ 1112 CIPVFlag_458h "0 - not CIPV 1 - CIPV";
CM_ SG_ 1112 MCPFlag_458h "0 - not MCP 1 - MCP";
CM_ SG_ 1112 ObstacleBlinkerInfo_458h "Blinker Info";
CM_ SG_ 1112 ObstacleBrakeLights_458h "BrakeLightInfo";
CM_ SG_ 1112 ObstacleCenterAngle_458h "The Angle Between the orientation of Host Vehicle and the orientation from the front center of Host Vehicle  to the Reference Point of the target";
CM_ SG_ 1112 ObstaclePositionType_458h "Were measurements predicted, old, or not valid";
CM_ SG_ 1112 CutInFlag_458h "0 - not CIPV 1 - CIPV";
CM_ SG_ 1113 ObstaclePosX_459h "The longitudinal distance to the middle of the RL and RR corners";
CM_ SG_ 1113 ObstaclePosY_459h "The lateral distance to the middle of the RL and RR corners";
CM_ SG_ 1113 ObstacleVelX_459h "The relative longitude velocity of the obstacle.";
CM_ SG_ 1113 ObstacleVelY_459h "The relative lateral velocity of the obstacle.";
CM_ SG_ 1113 ObstacleAccX_459h "The longitude relative acceleration of the object.";
CM_ SG_ 1114 ObstaclePosXSTD_45Ah "the standard deviation of longitudinal distance to the middle of the RL and RR corners";
CM_ SG_ 1114 ObstaclePosYSTD_45Ah "the standard deviation of lateral distance to the middle of the RL and RR corners";
CM_ SG_ 1114 ObstacleVelXSTD_45Ah "the standard deviation of longitude velocity of the obstacle.";
CM_ SG_ 1114 ObstacleVelYSTD_45Ah "the standard deviation of  lateral velocity of the obstacle.";
CM_ SG_ 1114 ObstacleAccY_45Ah "The lateral relative acceleration of the object.";
CM_ SG_ 1115 ObstacleAngle_45Bh "the heading angle of vehicle";
CM_ SG_ 1115 ObstacleAngleStd_45Bh "the standard deviation of heading angle of vehicle";
CM_ SG_ 1115 ObstacleVelXAbs_45Bh "the absolute longitude velocity of the obstacle.";
CM_ SG_ 1115 ObstacleVelYAbs_45Bh "the absolute lateral velocity of the obstacle.";
CM_ SG_ 1116 ObjCornerPointPoxX_45Ch "The longitudinal distance to the middle of the RL and RR corners";
CM_ SG_ 1116 CutInDistance_45Ch "The lateral distance to the middle of the RL and RR corners";
CM_ SG_ 1116 ObjCornerPointPoxY_45Ch "The longitudinal distance to the middle of the RL and RR corners";
CM_ SG_ 1116 ObstacleCurvature_45Ch "The lateral distance to the middle of the RL and RR corners";
CM_ SG_ 1121 ObstacleID_461h "The detected OBJ ID";
CM_ SG_ 1121 ObstacleValid_461h "Obstacle Valid info";
CM_ SG_ 1121 ObstacleReplaced_461h "Reserved";
CM_ SG_ 1121 ObstacleAge_461h "Frame age of obstacle";
CM_ SG_ 1121 ObstacleConfidence_461h "Existence probability of Obstacle";
CM_ SG_ 1121 ObstacleMotionCategory_461h "The signal is based on our estimation of where the target is now relatively to the lanes, its rate of change, and our estimation of where it is going to be within one second.";
CM_ SG_ 1121 ObstacleMotionStatus_461h "The target is moving or stopped";
CM_ SG_ 1121 ObstacleMeasuringStatus_461h "Were measurements predicted, old, or not valid";
CM_ SG_ 1121 ObstacleClass_461h "Kind of object.";
CM_ SG_ 1121 VehicleSubType_461h "Vehicle Sub type";
CM_ SG_ 1121 PedSubType_461h "Pedestrian Sub type";
CM_ SG_ 1121 PedPos_461h "Pedestrian Position";
CM_ SG_ 1121 PedOrientation_461h "Pedestrian Orientation";
CM_ SG_ 1121 ObstacleLaneAssignment_461h "Obstacle Lane Assignment £¨Which lane a vehicle belongs to£©";
CM_ SG_ 1122 ObstacleLength_462h "Length";
CM_ SG_ 1122 ObstacleWidth_462h "Width";
CM_ SG_ 1122 ObstacleHeight_462h "Height";
CM_ SG_ 1122 CIPVFlag_462h "0 - not CIPV 1 - CIPV";
CM_ SG_ 1122 MCPFlag_462h "0 - not MCP 1 - MCP";
CM_ SG_ 1122 ObstacleBlinkerInfo_462h "Blinker Info";
CM_ SG_ 1122 ObstacleBrakeLights_462h "BrakeLightInfo";
CM_ SG_ 1122 ObstacleCenterAngle_462h "The Angle Between the orientation of Host Vehicle and the orientation from the front center of Host Vehicle  to the Reference Point of the target";
CM_ SG_ 1122 ObstaclePositionType_462h "Were measurements predicted, old, or not valid";
CM_ SG_ 1122 CutInFlag_462h "0 - not CIPV 1 - CIPV";
CM_ SG_ 1123 ObstaclePosX_463h "The longitudinal distance to the middle of the RL and RR corners";
CM_ SG_ 1123 ObstaclePosY_463h "The lateral distance to the middle of the RL and RR corners";
CM_ SG_ 1123 ObstacleVelX_463h "The relative longitude velocity of the obstacle.";
CM_ SG_ 1123 ObstacleVelY_463h "The relative lateral velocity of the obstacle.";
CM_ SG_ 1123 ObstacleAccX_463h "The longitude relative acceleration of the object.";
CM_ SG_ 1124 ObstaclePosXSTD_464h "the standard deviation of longitudinal distance to the middle of the RL and RR corners";
CM_ SG_ 1124 ObstaclePosYSTD_464h "the standard deviation of lateral distance to the middle of the RL and RR corners";
CM_ SG_ 1124 ObstacleVelXSTD_464h "the standard deviation of longitude velocity of the obstacle.";
CM_ SG_ 1124 ObstacleVelYSTD_464h "the standard deviation of  lateral velocity of the obstacle.";
CM_ SG_ 1124 ObstacleAccY_464h "The lateral relative acceleration of the object.";
CM_ SG_ 1125 ObstacleAngle_465h "the heading angle of vehicle";
CM_ SG_ 1125 ObstacleAngleStd_465h "the standard deviation of heading angle of vehicle";
CM_ SG_ 1125 ObstacleVelXAbs_465h "the absolute longitude velocity of the obstacle.";
CM_ SG_ 1125 ObstacleVelYAbs_465h "the absolute lateral velocity of the obstacle.";
CM_ SG_ 1126 ObjCornerPointPoxX_466h "The longitudinal distance to the middle of the RL and RR corners";
CM_ SG_ 1126 CutInDistance_466h "The lateral distance to the middle of the RL and RR corners";
CM_ SG_ 1126 ObjCornerPointPoxY_466h "The longitudinal distance to the middle of the RL and RR corners";
CM_ SG_ 1126 ObstacleCurvature_466h "The lateral distance to the middle of the RL and RR corners";
CM_ SG_ 1131 ObstacleID_46Bh "The detected OBJ ID";
CM_ SG_ 1131 ObstacleValid_46Bh "Obstacle Valid info";
CM_ SG_ 1131 ObstacleReplaced_46Bh "Reserved";
CM_ SG_ 1131 ObstacleAge_46Bh "Frame age of obstacle";
CM_ SG_ 1131 ObstacleConfidence_46Bh "Existence probability of Obstacle";
CM_ SG_ 1131 ObstacleMotionCategory_46Bh "The signal is based on our estimation of where the target is now relatively to the lanes, its rate of change, and our estimation of where it is going to be within one second.";
CM_ SG_ 1131 ObstacleMotionStatus_46Bh "The target is moving or stopped";
CM_ SG_ 1131 ObstacleMeasuringStatus_46Bh "Were measurements predicted, old, or not valid";
CM_ SG_ 1131 ObstacleClass_46Bh "Kind of object.";
CM_ SG_ 1131 VehicleSubType_46Bh "Vehicle Sub type";
CM_ SG_ 1131 PedSubType_46Bh "Pedestrian Sub type";
CM_ SG_ 1131 PedPos_46Bh "Pedestrian Position";
CM_ SG_ 1131 PedOrientation_46Bh "Pedestrian Orientation";
CM_ SG_ 1131 ObstacleLaneAssignment_46Bh "Obstacle Lane Assignment £¨Which lane a vehicle belongs to£©";
CM_ SG_ 1132 ObstacleLength_46Ch "Length";
CM_ SG_ 1132 ObstacleWidth_46Ch "Width";
CM_ SG_ 1132 ObstacleHeight_46Ch "Height";
CM_ SG_ 1132 CIPVFlag_46Ch "0 - not CIPV 1 - CIPV";
CM_ SG_ 1132 MCPFlag_46Ch "0 - not MCP 1 - MCP";
CM_ SG_ 1132 ObstacleBlinkerInfo_46Ch "Blinker Info";
CM_ SG_ 1132 ObstacleBrakeLights_46Ch "BrakeLightInfo";
CM_ SG_ 1132 ObstacleCenterAngle_46Ch "The Angle Between the orientation of Host Vehicle and the orientation from the front center of Host Vehicle  to the Reference Point of the target";
CM_ SG_ 1132 ObstaclePositionType_46Ch "Were measurements predicted, old, or not valid";
CM_ SG_ 1132 CutInFlag_46Ch "0 - not CIPV 1 - CIPV";
CM_ SG_ 1133 ObstaclePosX_46Dh "The longitudinal distance to the middle of the RL and RR corners";
CM_ SG_ 1133 ObstaclePosY_46Dh "The lateral distance to the middle of the RL and RR corners";
CM_ SG_ 1133 ObstacleVelX_46Dh "The relative longitude velocity of the obstacle.";
CM_ SG_ 1133 ObstacleVelY_46Dh "The relative lateral velocity of the obstacle.";
CM_ SG_ 1133 ObstacleAccX_46Dh "The longitude relative acceleration of the object.";
CM_ SG_ 1134 ObstaclePosXSTD_46Eh "the standard deviation of longitudinal distance to the middle of the RL and RR corners";
CM_ SG_ 1134 ObstaclePosYSTD_46Eh "the standard deviation of lateral distance to the middle of the RL and RR corners";
CM_ SG_ 1134 ObstacleVelXSTD_46Eh "the standard deviation of longitude velocity of the obstacle.";
CM_ SG_ 1134 ObstacleVelYSTD_46Eh "the standard deviation of  lateral velocity of the obstacle.";
CM_ SG_ 1134 ObstacleAccY_46Eh "The lateral relative acceleration of the object.";
CM_ SG_ 1135 ObstacleAngle_46Fh "the heading angle of vehicle";
CM_ SG_ 1135 ObstacleAngleStd_46Fh "the standard deviation of heading angle of vehicle";
CM_ SG_ 1135 ObstacleVelXAbs_46Fh "the absolute longitude velocity of the obstacle.";
CM_ SG_ 1135 ObstacleVelYAbs_46Fh "the absolute lateral velocity of the obstacle.";
CM_ SG_ 1136 ObjCornerPointPoxX_470h "The longitudinal distance to the middle of the RL and RR corners";
CM_ SG_ 1136 CutInDistance_470h "The lateral distance to the middle of the RL and RR corners";
CM_ SG_ 1136 ObjCornerPointPoxY_470h "The longitudinal distance to the middle of the RL and RR corners";
CM_ SG_ 1136 ObstacleCurvature_470h "The lateral distance to the middle of the RL and RR corners";
CM_ SG_ 1141 ObstacleID_475h "The detected OBJ ID";
CM_ SG_ 1141 ObstacleValid_475h "Obstacle Valid info";
CM_ SG_ 1141 ObstacleReplaced_475h "Reserved";
CM_ SG_ 1141 ObstacleAge_475h "Frame age of obstacle";
CM_ SG_ 1141 ObstacleConfidence_475h "Existence probability of Obstacle";
CM_ SG_ 1141 ObstacleMotionCategory_475h "The signal is based on our estimation of where the target is now relatively to the lanes, its rate of change, and our estimation of where it is going to be within one second.";
CM_ SG_ 1141 ObstacleMotionStatus_475h "The target is moving or stopped";
CM_ SG_ 1141 ObstacleMeasuringStatus_475h "Were measurements predicted, old, or not valid";
CM_ SG_ 1141 ObstacleClass_475h "Kind of object.";
CM_ SG_ 1141 VehicleSubType_475h "Vehicle Sub type";
CM_ SG_ 1141 PedSubType_475h "Pedestrian Sub type";
CM_ SG_ 1141 PedPos_475h "Pedestrian Position";
CM_ SG_ 1141 PedOrientation_475h "Pedestrian Orientation";
CM_ SG_ 1141 ObstacleLaneAssignment_475h "Obstacle Lane Assignment £¨Which lane a vehicle belongs to£©";
CM_ SG_ 1142 ObstacleLength_476h "Length";
CM_ SG_ 1142 ObstacleWidth_476h "Width";
CM_ SG_ 1142 ObstacleHeight_476h "Height";
CM_ SG_ 1142 CIPVFlag_476h "0 - not CIPV 1 - CIPV";
CM_ SG_ 1142 MCPFlag_476h "0 - not MCP 1 - MCP";
CM_ SG_ 1142 ObstacleBlinkerInfo_476h "Blinker Info";
CM_ SG_ 1142 ObstacleBrakeLights_476h "BrakeLightInfo";
CM_ SG_ 1142 ObstacleCenterAngle_476h "The Angle Between the orientation of Host Vehicle and the orientation from the front center of Host Vehicle  to the Reference Point of the target";
CM_ SG_ 1142 ObstaclePositionType_476h "Were measurements predicted, old, or not valid";
CM_ SG_ 1142 CutInFlag_476h "0 - not CIPV 1 - CIPV";
CM_ SG_ 1143 ObstaclePosX_477h "The longitudinal distance to the middle of the RL and RR corners";
CM_ SG_ 1143 ObstaclePosY_477h "The lateral distance to the middle of the RL and RR corners";
CM_ SG_ 1143 ObstacleVelX_477h "The relative longitude velocity of the obstacle.";
CM_ SG_ 1143 ObstacleVelY_477h "The relative lateral velocity of the obstacle.";
CM_ SG_ 1143 ObstacleAccX_477h "The longitude relative acceleration of the object.";
CM_ SG_ 1144 ObstaclePosXSTD_478h "the standard deviation of longitudinal distance to the middle of the RL and RR corners";
CM_ SG_ 1144 ObstaclePosYSTD_478h "the standard deviation of lateral distance to the middle of the RL and RR corners";
CM_ SG_ 1144 ObstacleVelXSTD_478h "the standard deviation of longitude velocity of the obstacle.";
CM_ SG_ 1144 ObstacleVelYSTD_478h "the standard deviation of  lateral velocity of the obstacle.";
CM_ SG_ 1144 ObstacleAccY_478h "The lateral relative acceleration of the object.";
CM_ SG_ 1145 ObstacleAngle_479h "the heading angle of vehicle";
CM_ SG_ 1145 ObstacleAngleStd_479h "the standard deviation of heading angle of vehicle";
CM_ SG_ 1145 ObstacleVelXAbs_479h "the absolute longitude velocity of the obstacle.";
CM_ SG_ 1145 ObstacleVelYAbs_479h "the absolute lateral velocity of the obstacle.";
CM_ SG_ 1146 ObjCornerPointPoxX_47Ah "The longitudinal distance to the middle of the RL and RR corners";
CM_ SG_ 1146 CutInDistance_47Ah "The lateral distance to the middle of the RL and RR corners";
CM_ SG_ 1146 ObjCornerPointPoxY_47Ah "The longitudinal distance to the middle of the RL and RR corners";
CM_ SG_ 1146 ObstacleCurvature_47Ah "The lateral distance to the middle of the RL and RR corners";
CM_ SG_ 1151 ObstacleID_47Fh "The detected OBJ ID";
CM_ SG_ 1151 ObstacleValid_47Fh "Obstacle Valid info";
CM_ SG_ 1151 ObstacleReplaced_47Fh "Reserved";
CM_ SG_ 1151 ObstacleAge_47Fh "Frame age of obstacle";
CM_ SG_ 1151 ObstacleConfidence_47Fh "Existence probability of Obstacle";
CM_ SG_ 1151 ObstacleMotionCategory_47Fh "The signal is based on our estimation of where the target is now relatively to the lanes, its rate of change, and our estimation of where it is going to be within one second.";
CM_ SG_ 1151 ObstacleMotionStatus_47Fh "The target is moving or stopped";
CM_ SG_ 1151 ObstacleMeasuringStatus_47Fh "Were measurements predicted, old, or not valid";
CM_ SG_ 1151 ObstacleClass_47Fh "Kind of object.";
CM_ SG_ 1151 VehicleSubType_47Fh "Vehicle Sub type";
CM_ SG_ 1151 PedSubType_47Fh "Pedestrian Sub type";
CM_ SG_ 1151 PedPos_47Fh "Pedestrian Position";
CM_ SG_ 1151 PedOrientation_47Fh "Pedestrian Orientation";
CM_ SG_ 1151 ObstacleLaneAssignment_47Fh "Obstacle Lane Assignment £¨Which lane a vehicle belongs to£©";
CM_ SG_ 1152 ObstacleLength_480h "Length";
CM_ SG_ 1152 ObstacleWidth_480h "Width";
CM_ SG_ 1152 ObstacleHeight_480h "Height";
CM_ SG_ 1152 CIPVFlag_480h "0 - not CIPV 1 - CIPV";
CM_ SG_ 1152 MCPFlag_480h "0 - not MCP 1 - MCP";
CM_ SG_ 1152 ObstacleBlinkerInfo_480h "Blinker Info";
CM_ SG_ 1152 ObstacleBrakeLights_480h "BrakeLightInfo";
CM_ SG_ 1152 ObstacleCenterAngle_480h "The Angle Between the orientation of Host Vehicle and the orientation from the front center of Host Vehicle  to the Reference Point of the target";
CM_ SG_ 1152 ObstaclePositionType_480h "Were measurements predicted, old, or not valid";
CM_ SG_ 1152 CutInFlag_480h "0 - not CIPV 1 - CIPV";
CM_ SG_ 1153 ObstaclePosX_481h "The longitudinal distance to the middle of the RL and RR corners";
CM_ SG_ 1153 ObstaclePosY_481h "The lateral distance to the middle of the RL and RR corners";
CM_ SG_ 1153 ObstacleVelX_481h "The relative longitude velocity of the obstacle.";
CM_ SG_ 1153 ObstacleVelY_481h "The relative lateral velocity of the obstacle.";
CM_ SG_ 1153 ObstacleAccX_481h "The longitude relative acceleration of the object.";
CM_ SG_ 1154 ObstaclePosXSTD_482h "the standard deviation of longitudinal distance to the middle of the RL and RR corners";
CM_ SG_ 1154 ObstaclePosYSTD_482h "the standard deviation of lateral distance to the middle of the RL and RR corners";
CM_ SG_ 1154 ObstacleVelXSTD_482h "the standard deviation of longitude velocity of the obstacle.";
CM_ SG_ 1154 ObstacleVelYSTD_482h "the standard deviation of  lateral velocity of the obstacle.";
CM_ SG_ 1154 ObstacleAccY_482h "The lateral relative acceleration of the object.";
CM_ SG_ 1155 ObstacleAngle_483h "the heading angle of vehicle";
CM_ SG_ 1155 ObstacleAngleStd_483h "the standard deviation of heading angle of vehicle";
CM_ SG_ 1155 ObstacleVelXAbs_483h "the absolute longitude velocity of the obstacle.";
CM_ SG_ 1155 ObstacleVelYAbs_483h "the absolute lateral velocity of the obstacle.";
CM_ SG_ 1156 ObjCornerPointPoxX_484h "The longitudinal distance to the middle of the RL and RR corners";
CM_ SG_ 1156 CutInDistance_484h "The lateral distance to the middle of the RL and RR corners";
CM_ SG_ 1156 ObjCornerPointPoxY_484h "The longitudinal distance to the middle of the RL and RR corners";
CM_ SG_ 1156 ObstacleCurvature_484h "The lateral distance to the middle of the RL and RR corners";
CM_ SG_ 1161 ObstacleID_489h "The detected OBJ ID";
CM_ SG_ 1161 ObstacleValid_489h "Obstacle Valid info";
CM_ SG_ 1161 ObstacleReplaced_489h "Reserved";
CM_ SG_ 1161 ObstacleAge_489h "Frame age of obstacle";
CM_ SG_ 1161 ObstacleConfidence_489h "Existence probability of Obstacle";
CM_ SG_ 1161 ObstacleMotionCategory_489h "The signal is based on our estimation of where the target is now relatively to the lanes, its rate of change, and our estimation of where it is going to be within one second.";
CM_ SG_ 1161 ObstacleMotionStatus_489h "The target is moving or stopped";
CM_ SG_ 1161 ObstacleMeasuringStatus_489h "Were measurements predicted, old, or not valid";
CM_ SG_ 1161 ObstacleClass_489h "Kind of object.";
CM_ SG_ 1161 VehicleSubType_489h "Vehicle Sub type";
CM_ SG_ 1161 PedSubType_489h "Pedestrian Sub type";
CM_ SG_ 1161 PedPos_489h "Pedestrian Position";
CM_ SG_ 1161 PedOrientation_489h "Pedestrian Orientation";
CM_ SG_ 1161 ObstacleLaneAssignment_489h "Obstacle Lane Assignment £¨Which lane a vehicle belongs to£©";
CM_ SG_ 1162 ObstacleLength_48Ah "Length";
CM_ SG_ 1162 ObstacleWidth_48Ah "Width";
CM_ SG_ 1162 ObstacleHeight_48Ah "Height";
CM_ SG_ 1162 CIPVFlag_48Ah "0 - not CIPV 1 - CIPV";
CM_ SG_ 1162 MCPFlag_48Ah "0 - not MCP 1 - MCP";
CM_ SG_ 1162 ObstacleBlinkerInfo_48Ah "Blinker Info";
CM_ SG_ 1162 ObstacleBrakeLights_48Ah "BrakeLightInfo";
CM_ SG_ 1162 ObstacleCenterAngle_48Ah "The Angle Between the orientation of Host Vehicle and the orientation from the front center of Host Vehicle  to the Reference Point of the target";
CM_ SG_ 1162 ObstaclePositionType_48Ah "Were measurements predicted, old, or not valid";
CM_ SG_ 1162 CutInFlag_48Ah "0 - not CIPV 1 - CIPV";
CM_ SG_ 1163 ObstaclePosX_48Bh "The longitudinal distance to the middle of the RL and RR corners";
CM_ SG_ 1163 ObstaclePosY_48Bh "The lateral distance to the middle of the RL and RR corners";
CM_ SG_ 1163 ObstacleVelX_48Bh "The relative longitude velocity of the obstacle.";
CM_ SG_ 1163 ObstacleVelY_48Bh "The relative lateral velocity of the obstacle.";
CM_ SG_ 1163 ObstacleAccX_48Bh "The longitude relative acceleration of the object.";
CM_ SG_ 1164 ObstaclePosXSTD_48Ch "the standard deviation of longitudinal distance to the middle of the RL and RR corners";
CM_ SG_ 1164 ObstaclePosYSTD_48Ch "the standard deviation of lateral distance to the middle of the RL and RR corners";
CM_ SG_ 1164 ObstacleVelXSTD_48Ch "the standard deviation of longitude velocity of the obstacle.";
CM_ SG_ 1164 ObstacleVelYSTD_48Ch "the standard deviation of  lateral velocity of the obstacle.";
CM_ SG_ 1164 ObstacleAccY_48Ch "The lateral relative acceleration of the object.";
CM_ SG_ 1165 ObstacleAngle_48Dh "the heading angle of vehicle";
CM_ SG_ 1165 ObstacleAngleStd_48Dh "the standard deviation of heading angle of vehicle";
CM_ SG_ 1165 ObstacleVelXAbs_48Dh "the absolute longitude velocity of the obstacle.";
CM_ SG_ 1165 ObstacleVelYAbs_48Dh "the absolute lateral velocity of the obstacle.";
CM_ SG_ 1166 ObjCornerPointPoxX_48Eh "The longitudinal distance to the middle of the RL and RR corners";
CM_ SG_ 1166 CutInDistance_48Eh "The lateral distance to the middle of the RL and RR corners";
CM_ SG_ 1166 ObjCornerPointPoxY_48Eh "The longitudinal distance to the middle of the RL and RR corners";
CM_ SG_ 1166 ObstacleCurvature_48Eh "The lateral distance to the middle of the RL and RR corners";
CM_ SG_ 1171 ObstacleID_493h "The detected OBJ ID";
CM_ SG_ 1171 ObstacleValid_493h "Obstacle Valid info";
CM_ SG_ 1171 ObstacleReplaced_493h "Reserved";
CM_ SG_ 1171 ObstacleAge_493h "Frame age of obstacle";
CM_ SG_ 1171 ObstacleConfidence_493h "Existence probability of Obstacle";
CM_ SG_ 1171 ObstacleMotionCategory_493h "The signal is based on our estimation of where the target is now relatively to the lanes, its rate of change, and our estimation of where it is going to be within one second.";
CM_ SG_ 1171 ObstacleMotionStatus_493h "The target is moving or stopped";
CM_ SG_ 1171 ObstacleMeasuringStatus_493h "Were measurements predicted, old, or not valid";
CM_ SG_ 1171 ObstacleClass_493h "Kind of object.";
CM_ SG_ 1171 VehicleSubType_493h "Vehicle Sub type";
CM_ SG_ 1171 PedSubType_493h "Pedestrian Sub type";
CM_ SG_ 1171 PedPos_493h "Pedestrian Position";
CM_ SG_ 1171 PedOrientation_493h "Pedestrian Orientation";
CM_ SG_ 1171 ObstacleLaneAssignment_493h "Obstacle Lane Assignment £¨Which lane a vehicle belongs to£©";
CM_ SG_ 1172 ObstacleLength_494h "Length";
CM_ SG_ 1172 ObstacleWidth_494h "Width";
CM_ SG_ 1172 ObstacleHeight_494h "Height";
CM_ SG_ 1172 CIPVFlag_494h "0 - not CIPV 1 - CIPV";
CM_ SG_ 1172 MCPFlag_494h "0 - not MCP 1 - MCP";
CM_ SG_ 1172 ObstacleBlinkerInfo_494h "Blinker Info";
CM_ SG_ 1172 ObstacleBrakeLights_494h "BrakeLightInfo";
CM_ SG_ 1172 ObstacleCenterAngle_494h "The Angle Between the orientation of Host Vehicle and the orientation from the front center of Host Vehicle  to the Reference Point of the target";
CM_ SG_ 1172 ObstaclePositionType_494h "Were measurements predicted, old, or not valid";
CM_ SG_ 1172 CutInFlag_494h "0 - not CIPV 1 - CIPV";
CM_ SG_ 1173 ObstaclePosX_495h "The longitudinal distance to the middle of the RL and RR corners";
CM_ SG_ 1173 ObstaclePosY_495h "The lateral distance to the middle of the RL and RR corners";
CM_ SG_ 1173 ObstacleVelX_495h "The relative longitude velocity of the obstacle.";
CM_ SG_ 1173 ObstacleVelY_495h "The relative lateral velocity of the obstacle.";
CM_ SG_ 1173 ObstacleAccX_495h "The longitude relative acceleration of the object.";
CM_ SG_ 1174 ObstaclePosXSTD_496h "the standard deviation of longitudinal distance to the middle of the RL and RR corners";
CM_ SG_ 1174 ObstaclePosYSTD_496h "the standard deviation of lateral distance to the middle of the RL and RR corners";
CM_ SG_ 1174 ObstacleVelXSTD_496h "the standard deviation of longitude velocity of the obstacle.";
CM_ SG_ 1174 ObstacleVelYSTD_496h "the standard deviation of  lateral velocity of the obstacle.";
CM_ SG_ 1174 ObstacleAccY_496h "The lateral relative acceleration of the object.";
CM_ SG_ 1175 ObstacleAngle_497h "the heading angle of vehicle";
CM_ SG_ 1175 ObstacleAngleStd_497h "the standard deviation of heading angle of vehicle";
CM_ SG_ 1175 ObstacleVelXAbs_497h "the absolute longitude velocity of the obstacle.";
CM_ SG_ 1175 ObstacleVelYAbs_497h "the absolute lateral velocity of the obstacle.";
CM_ SG_ 1176 ObjCornerPointPoxX_498h "The longitudinal distance to the middle of the RL and RR corners";
CM_ SG_ 1176 CutInDistance_498h "The lateral distance to the middle of the RL and RR corners";
CM_ SG_ 1176 ObjCornerPointPoxY_498h "The longitudinal distance to the middle of the RL and RR corners";
CM_ SG_ 1176 ObstacleCurvature_498h "The lateral distance to the middle of the RL and RR corners";
CM_ SG_ 1181 ObstacleID_49Dh "The detected OBJ ID";
CM_ SG_ 1181 ObstacleValid_49Dh "Obstacle Valid info";
CM_ SG_ 1181 ObstacleReplaced_49Dh "Reserved";
CM_ SG_ 1181 ObstacleAge_49Dh "Frame age of obstacle";
CM_ SG_ 1181 ObstacleConfidence_49Dh "Existence probability of Obstacle";
CM_ SG_ 1181 ObstacleMotionCategory_49Dh "The signal is based on our estimation of where the target is now relatively to the lanes, its rate of change, and our estimation of where it is going to be within one second.";
CM_ SG_ 1181 ObstacleMotionStatus_49Dh "The target is moving or stopped";
CM_ SG_ 1181 ObstacleMeasuringStatus_49Dh "Were measurements predicted, old, or not valid";
CM_ SG_ 1181 ObstacleClass_49Dh "Kind of object.";
CM_ SG_ 1181 VehicleSubType_49Dh "Vehicle Sub type";
CM_ SG_ 1181 PedSubType_49Dh "Pedestrian Sub type";
CM_ SG_ 1181 PedPos_49Dh "Pedestrian Position";
CM_ SG_ 1181 PedOrientation_49Dh "Pedestrian Orientation";
CM_ SG_ 1181 ObstacleLaneAssignment_49Dh "Obstacle Lane Assignment £¨Which lane a vehicle belongs to£©";
CM_ SG_ 1182 ObstacleLength_49Eh "Length";
CM_ SG_ 1182 ObstacleWidth_49Eh "Width";
CM_ SG_ 1182 ObstacleHeight_49Eh "Height";
CM_ SG_ 1182 CIPVFlag_49Eh "0 - not CIPV 1 - CIPV";
CM_ SG_ 1182 MCPFlag_49Eh "0 - not MCP 1 - MCP";
CM_ SG_ 1182 ObstacleBlinkerInfo_49Eh "Blinker Info";
CM_ SG_ 1182 ObstacleBrakeLights_49Eh "BrakeLightInfo";
CM_ SG_ 1182 ObstacleCenterAngle_49Eh "The Angle Between the orientation of Host Vehicle and the orientation from the front center of Host Vehicle  to the Reference Point of the target";
CM_ SG_ 1182 ObstaclePositionType_49Eh "Were measurements predicted, old, or not valid";
CM_ SG_ 1182 CutInFlag_49Eh "0 - not CIPV 1 - CIPV";
CM_ SG_ 1183 ObstaclePosX_49Fh "The longitudinal distance to the middle of the RL and RR corners";
CM_ SG_ 1183 ObstaclePosY_49Fh "The lateral distance to the middle of the RL and RR corners";
CM_ SG_ 1183 ObstacleVelX_49Fh "The relative longitude velocity of the obstacle.";
CM_ SG_ 1183 ObstacleVelY_49Fh "The relative lateral velocity of the obstacle.";
CM_ SG_ 1183 ObstacleAccX_49Fh "The longitude relative acceleration of the object.";
CM_ SG_ 1184 ObstaclePosXSTD_4A0h "the standard deviation of longitudinal distance to the middle of the RL and RR corners";
CM_ SG_ 1184 ObstaclePosYSTD_4A0h "the standard deviation of lateral distance to the middle of the RL and RR corners";
CM_ SG_ 1184 ObstacleVelXSTD_4A0h "the standard deviation of longitude velocity of the obstacle.";
CM_ SG_ 1184 ObstacleVelYSTD_4A0h "the standard deviation of  lateral velocity of the obstacle.";
CM_ SG_ 1184 ObstacleAccY_4A0h "The lateral relative acceleration of the object.";
CM_ SG_ 1185 ObstacleAngle_4A1h "the heading angle of vehicle";
CM_ SG_ 1185 ObstacleAngleStd_4A1h "the standard deviation of heading angle of vehicle";
CM_ SG_ 1185 ObstacleVelXAbs_4A1h "the absolute longitude velocity of the obstacle.";
CM_ SG_ 1185 ObstacleVelYAbs_4A1h "the absolute lateral velocity of the obstacle.";
CM_ SG_ 1186 ObjCornerPointPoxX_4A2h "The longitudinal distance to the middle of the RL and RR corners";
CM_ SG_ 1186 CutInDistance_4A2h "The lateral distance to the middle of the RL and RR corners";
CM_ SG_ 1186 ObjCornerPointPoxY_4A2h "The longitudinal distance to the middle of the RL and RR corners";
CM_ SG_ 1186 ObstacleCurvature_4A2h "The lateral distance to the middle of the RL and RR corners";
CM_ SG_ 1191 ObstacleID_4A7h "The detected OBJ ID";
CM_ SG_ 1191 ObstacleValid_4A7h "Obstacle Valid info";
CM_ SG_ 1191 ObstacleReplaced_4A7h "Reserved";
CM_ SG_ 1191 ObstacleAge_4A7h "Frame age of obstacle";
CM_ SG_ 1191 ObstacleConfidence_4A7h "Existence probability of Obstacle";
CM_ SG_ 1191 ObstacleMotionCategory_4A7h "The signal is based on our estimation of where the target is now relatively to the lanes, its rate of change, and our estimation of where it is going to be within one second.";
CM_ SG_ 1191 ObstacleMotionStatus_4A7h "The target is moving or stopped";
CM_ SG_ 1191 ObstacleMeasuringStatus_4A7h "Were measurements predicted, old, or not valid";
CM_ SG_ 1191 ObstacleClass_4A7h "Kind of object.";
CM_ SG_ 1191 VehicleSubType_4A7h "Vehicle Sub type";
CM_ SG_ 1191 PedSubType_4A7h "Pedestrian Sub type";
CM_ SG_ 1191 PedPos_4A7h "Pedestrian Position";
CM_ SG_ 1191 PedOrientation_4A7h "Pedestrian Orientation";
CM_ SG_ 1191 ObstacleLaneAssignment_4A7h "Obstacle Lane Assignment £¨Which lane a vehicle belongs to£©";
CM_ SG_ 1192 ObstacleLength_4A8h "Length";
CM_ SG_ 1192 ObstacleWidth_4A8h "Width";
CM_ SG_ 1192 ObstacleHeight_4A8h "Height";
CM_ SG_ 1192 CIPVFlag_4A8h "0 - not CIPV 1 - CIPV";
CM_ SG_ 1192 MCPFlag_4A8h "0 - not MCP 1 - MCP";
CM_ SG_ 1192 ObstacleBlinkerInfo_4A8h "Blinker Info";
CM_ SG_ 1192 ObstacleBrakeLights_4A8h "BrakeLightInfo";
CM_ SG_ 1192 ObstacleCenterAngle_4A8h "The Angle Between the orientation of Host Vehicle and the orientation from the front center of Host Vehicle  to the Reference Point of the target";
CM_ SG_ 1192 ObstaclePositionType_4A8h "Were measurements predicted, old, or not valid";
CM_ SG_ 1192 CutInFlag_4A8h "0 - not CIPV 1 - CIPV";
CM_ SG_ 1193 ObstaclePosX_4A9h "The longitudinal distance to the middle of the RL and RR corners";
CM_ SG_ 1193 ObstaclePosY_4A9h "The lateral distance to the middle of the RL and RR corners";
CM_ SG_ 1193 ObstacleVelX_4A9h "The relative longitude velocity of the obstacle.";
CM_ SG_ 1193 ObstacleVelY_4A9h "The relative lateral velocity of the obstacle.";
CM_ SG_ 1193 ObstacleAccX_4A9h "The longitude relative acceleration of the object.";
CM_ SG_ 1194 ObstaclePosXSTD_4AAh "the standard deviation of longitudinal distance to the middle of the RL and RR corners";
CM_ SG_ 1194 ObstaclePosYSTD_4AAh "the standard deviation of lateral distance to the middle of the RL and RR corners";
CM_ SG_ 1194 ObstacleVelXSTD_4AAh "the standard deviation of longitude velocity of the obstacle.";
CM_ SG_ 1194 ObstacleVelYSTD_4AAh "the standard deviation of  lateral velocity of the obstacle.";
CM_ SG_ 1194 ObstacleAccY_4AAh "The lateral relative acceleration of the object.";
CM_ SG_ 1195 ObstacleAngle_4ABh "the heading angle of vehicle";
CM_ SG_ 1195 ObstacleAngleStd_4ABh "the standard deviation of heading angle of vehicle";
CM_ SG_ 1195 ObstacleVelXAbs_4ABh "the absolute longitude velocity of the obstacle.";
CM_ SG_ 1195 ObstacleVelYAbs_4ABh "the absolute lateral velocity of the obstacle.";
CM_ SG_ 1196 ObjCornerPointPoxX_4ACh "The longitudinal distance to the middle of the RL and RR corners";
CM_ SG_ 1196 CutInDistance_4ACh "The lateral distance to the middle of the RL and RR corners";
CM_ SG_ 1196 ObjCornerPointPoxY_4ACh "The longitudinal distance to the middle of the RL and RR corners";
CM_ SG_ 1196 ObstacleCurvature_4ACh "The lateral distance to the middle of the RL and RR corners";
CM_ SG_ 1201 ObstacleID_4B1h "The detected OBJ ID";
CM_ SG_ 1201 ObstacleValid_4B1h "Obstacle Valid info";
CM_ SG_ 1201 ObstacleReplaced_4B1h "Reserved";
CM_ SG_ 1201 ObstacleAge_4B1h "Frame age of obstacle";
CM_ SG_ 1201 ObstacleConfidence_4B1h "Existence probability of Obstacle";
CM_ SG_ 1201 ObstacleMotionCategory_4B1h "The signal is based on our estimation of where the target is now relatively to the lanes, its rate of change, and our estimation of where it is going to be within one second.";
CM_ SG_ 1201 ObstacleMotionStatus_4B1h "The target is moving or stopped";
CM_ SG_ 1201 ObstacleMeasuringStatus_4B1h "Were measurements predicted, old, or not valid";
CM_ SG_ 1201 ObstacleClass_4B1h "Kind of object.";
CM_ SG_ 1201 VehicleSubType_4B1h "Vehicle Sub type";
CM_ SG_ 1201 PedSubType_4B1h "Pedestrian Sub type";
CM_ SG_ 1201 PedPos_4B1h "Pedestrian Position";
CM_ SG_ 1201 PedOrientation_4B1h "Pedestrian Orientation";
CM_ SG_ 1201 ObstacleLaneAssignment_4B1h "Obstacle Lane Assignment £¨Which lane a vehicle belongs to£©";
CM_ SG_ 1202 ObstacleLength_4B2h "Length";
CM_ SG_ 1202 ObstacleWidth_4B2h "Width";
CM_ SG_ 1202 ObstacleHeight_4B2h "Height";
CM_ SG_ 1202 CIPVFlag_4B2h "0 - not CIPV 1 - CIPV";
CM_ SG_ 1202 MCPFlag_4B2h "0 - not MCP 1 - MCP";
CM_ SG_ 1202 ObstacleBlinkerInfo_4B2h "Blinker Info";
CM_ SG_ 1202 ObstacleBrakeLights_4B2h "BrakeLightInfo";
CM_ SG_ 1202 ObstacleCenterAngle_4B2h "The Angle Between the orientation of Host Vehicle and the orientation from the front center of Host Vehicle  to the Reference Point of the target";
CM_ SG_ 1202 ObstaclePositionType_4B2h "Were measurements predicted, old, or not valid";
CM_ SG_ 1202 CutInFlag_4B2h "0 - not CIPV 1 - CIPV";
CM_ SG_ 1203 ObstaclePosX_4B3h "The longitudinal distance to the middle of the RL and RR corners";
CM_ SG_ 1203 ObstaclePosY_4B3h "The lateral distance to the middle of the RL and RR corners";
CM_ SG_ 1203 ObstacleVelX_4B3h "The relative longitude velocity of the obstacle.";
CM_ SG_ 1203 ObstacleVelY_4B3h "The relative lateral velocity of the obstacle.";
CM_ SG_ 1203 ObstacleAccX_4B3h "The longitude relative acceleration of the object.";
CM_ SG_ 1204 ObstaclePosXSTD_4B4h "the standard deviation of longitudinal distance to the middle of the RL and RR corners";
CM_ SG_ 1204 ObstaclePosYSTD_4B4h "the standard deviation of lateral distance to the middle of the RL and RR corners";
CM_ SG_ 1204 ObstacleVelXSTD_4B4h "the standard deviation of longitude velocity of the obstacle.";
CM_ SG_ 1204 ObstacleVelYSTD_4B4h "the standard deviation of  lateral velocity of the obstacle.";
CM_ SG_ 1204 ObstacleAccY_4B4h "The lateral relative acceleration of the object.";
CM_ SG_ 1205 ObstacleAngle_4B5h "the heading angle of vehicle";
CM_ SG_ 1205 ObstacleAngleStd_4B5h "the standard deviation of heading angle of vehicle";
CM_ SG_ 1205 ObstacleVelXAbs_4B5h "the absolute longitude velocity of the obstacle.";
CM_ SG_ 1205 ObstacleVelYAbs_4B5h "the absolute lateral velocity of the obstacle.";
CM_ SG_ 1206 ObjCornerPointPoxX_4B6h "The longitudinal distance to the middle of the RL and RR corners";
CM_ SG_ 1206 CutInDistance_4B6h "The lateral distance to the middle of the RL and RR corners";
CM_ SG_ 1206 ObjCornerPointPoxY_4B6h "The longitudinal distance to the middle of the RL and RR corners";
CM_ SG_ 1206 ObstacleCurvature_4B6h "The lateral distance to the middle of the RL and RR corners";
CM_ SG_ 1211 ObstacleID_4BBh "The detected OBJ ID";
CM_ SG_ 1211 ObstacleValid_4BBh "Obstacle Valid info";
CM_ SG_ 1211 ObstacleReplaced_4BBh "Reserved";
CM_ SG_ 1211 ObstacleAge_4BBh "Frame age of obstacle";
CM_ SG_ 1211 ObstacleConfidence_4BBh "Existence probability of Obstacle";
CM_ SG_ 1211 ObstacleMotionCategory_4BBh "The signal is based on our estimation of where the target is now relatively to the lanes, its rate of change, and our estimation of where it is going to be within one second.";
CM_ SG_ 1211 ObstacleMotionStatus_4BBh "The target is moving or stopped";
CM_ SG_ 1211 ObstacleMeasuringStatus_4BBh "Were measurements predicted, old, or not valid";
CM_ SG_ 1211 ObstacleClass_4BBh "Kind of object.";
CM_ SG_ 1211 VehicleSubType_4BBh "Vehicle Sub type";
CM_ SG_ 1211 PedSubType_4BBh "Pedestrian Sub type";
CM_ SG_ 1211 PedPos_4BBh "Pedestrian Position";
CM_ SG_ 1211 PedOrientation_4BBh "Pedestrian Orientation";
CM_ SG_ 1211 ObstacleLaneAssignment_4BBh "Obstacle Lane Assignment £¨Which lane a vehicle belongs to£©";

BA_DEF_ BO_ "GenMsgCycleTime" INT 0 65535;
BA_DEF_ BO_ "VFrameFormat" ENUM  "StandardCAN","ExtendedCAN","reserved","reserved","reserved","reserved","reserved","reserved","reserved","reserved","reserved","reserved","reserved","reserved","StandardCAN_FD","ExtendedCAN_FD";
BA_DEF_  "DBName" STRING ;
BA_DEF_ "BusType" STRING;
BA_DEF_DEF_  "DBName" "";
BA_DEF_DEF_ "BusType" "CAN FD";
BA_ "DBName" "ADASCAN";

BA_ "GenMsgCycleTime" BO_ 1024 0;
BA_ "VFrameFormat" BO_ 1024 14;
BA_ "GenMsgCycleTime" BO_ 1025 0;
BA_ "VFrameFormat" BO_ 1025 14;
BA_ "GenMsgCycleTime" BO_ 1026 0;
BA_ "VFrameFormat" BO_ 1026 14;
BA_ "GenMsgCycleTime" BO_ 1040 0;
BA_ "VFrameFormat" BO_ 1040 14;
BA_ "GenMsgCycleTime" BO_ 1041 0;
BA_ "VFrameFormat" BO_ 1041 14;
BA_ "GenMsgCycleTime" BO_ 1042 0;
BA_ "VFrameFormat" BO_ 1042 14;
BA_ "GenMsgCycleTime" BO_ 1043 0;
BA_ "VFrameFormat" BO_ 1043 14;
BA_ "GenMsgCycleTime" BO_ 1044 0;
BA_ "VFrameFormat" BO_ 1044 14;
BA_ "GenMsgCycleTime" BO_ 1045 0;
BA_ "VFrameFormat" BO_ 1045 14;
BA_ "GenMsgCycleTime" BO_ 1046 0;
BA_ "VFrameFormat" BO_ 1046 14;
BA_ "GenMsgCycleTime" BO_ 1051 0;
BA_ "VFrameFormat" BO_ 1051 14;
BA_ "GenMsgCycleTime" BO_ 1052 0;
BA_ "VFrameFormat" BO_ 1052 14;
BA_ "GenMsgCycleTime" BO_ 1053 0;
BA_ "VFrameFormat" BO_ 1053 14;
BA_ "GenMsgCycleTime" BO_ 1054 0;
BA_ "VFrameFormat" BO_ 1054 14;
BA_ "GenMsgCycleTime" BO_ 1055 0;
BA_ "VFrameFormat" BO_ 1055 14;
BA_ "GenMsgCycleTime" BO_ 1056 0;
BA_ "VFrameFormat" BO_ 1056 14;
BA_ "GenMsgCycleTime" BO_ 1061 0;
BA_ "VFrameFormat" BO_ 1061 14;
BA_ "GenMsgCycleTime" BO_ 1062 0;
BA_ "VFrameFormat" BO_ 1062 14;
BA_ "GenMsgCycleTime" BO_ 1063 0;
BA_ "VFrameFormat" BO_ 1063 14;
BA_ "GenMsgCycleTime" BO_ 1064 0;
BA_ "VFrameFormat" BO_ 1064 14;
BA_ "GenMsgCycleTime" BO_ 1065 0;
BA_ "VFrameFormat" BO_ 1065 14;
BA_ "GenMsgCycleTime" BO_ 1066 0;
BA_ "VFrameFormat" BO_ 1066 14;
BA_ "GenMsgCycleTime" BO_ 1071 0;
BA_ "VFrameFormat" BO_ 1071 14;
BA_ "GenMsgCycleTime" BO_ 1072 0;
BA_ "VFrameFormat" BO_ 1072 14;
BA_ "GenMsgCycleTime" BO_ 1073 0;
BA_ "VFrameFormat" BO_ 1073 14;
BA_ "GenMsgCycleTime" BO_ 1074 0;
BA_ "VFrameFormat" BO_ 1074 14;
BA_ "GenMsgCycleTime" BO_ 1075 0;
BA_ "VFrameFormat" BO_ 1075 14;
BA_ "GenMsgCycleTime" BO_ 1076 0;
BA_ "VFrameFormat" BO_ 1076 14;
BA_ "GenMsgCycleTime" BO_ 1081 0;
BA_ "VFrameFormat" BO_ 1081 14;
BA_ "GenMsgCycleTime" BO_ 1082 0;
BA_ "VFrameFormat" BO_ 1082 14;
BA_ "GenMsgCycleTime" BO_ 1083 0;
BA_ "VFrameFormat" BO_ 1083 14;
BA_ "GenMsgCycleTime" BO_ 1084 0;
BA_ "VFrameFormat" BO_ 1084 14;
BA_ "GenMsgCycleTime" BO_ 1085 0;
BA_ "VFrameFormat" BO_ 1085 14;
BA_ "GenMsgCycleTime" BO_ 1086 0;
BA_ "VFrameFormat" BO_ 1086 14;
BA_ "GenMsgCycleTime" BO_ 1091 0;
BA_ "VFrameFormat" BO_ 1091 14;
BA_ "GenMsgCycleTime" BO_ 1092 0;
BA_ "VFrameFormat" BO_ 1092 14;
BA_ "GenMsgCycleTime" BO_ 1093 0;
BA_ "VFrameFormat" BO_ 1093 14;
BA_ "GenMsgCycleTime" BO_ 1094 0;
BA_ "VFrameFormat" BO_ 1094 14;
BA_ "GenMsgCycleTime" BO_ 1095 0;
BA_ "VFrameFormat" BO_ 1095 14;
BA_ "GenMsgCycleTime" BO_ 1096 0;
BA_ "VFrameFormat" BO_ 1096 14;
BA_ "GenMsgCycleTime" BO_ 1101 0;
BA_ "VFrameFormat" BO_ 1101 14;
BA_ "GenMsgCycleTime" BO_ 1102 0;
BA_ "VFrameFormat" BO_ 1102 14;
BA_ "GenMsgCycleTime" BO_ 1103 0;
BA_ "VFrameFormat" BO_ 1103 14;
BA_ "GenMsgCycleTime" BO_ 1104 0;
BA_ "VFrameFormat" BO_ 1104 14;
BA_ "GenMsgCycleTime" BO_ 1105 0;
BA_ "VFrameFormat" BO_ 1105 14;
BA_ "GenMsgCycleTime" BO_ 1106 0;
BA_ "VFrameFormat" BO_ 1106 14;
BA_ "GenMsgCycleTime" BO_ 1111 0;
BA_ "VFrameFormat" BO_ 1111 14;
BA_ "GenMsgCycleTime" BO_ 1112 0;
BA_ "VFrameFormat" BO_ 1112 14;
BA_ "GenMsgCycleTime" BO_ 1113 0;
BA_ "VFrameFormat" BO_ 1113 14;
BA_ "GenMsgCycleTime" BO_ 1114 0;
BA_ "VFrameFormat" BO_ 1114 14;
BA_ "GenMsgCycleTime" BO_ 1115 0;
BA_ "VFrameFormat" BO_ 1115 14;
BA_ "GenMsgCycleTime" BO_ 1116 0;
BA_ "VFrameFormat" BO_ 1116 14;
BA_ "GenMsgCycleTime" BO_ 1121 0;
BA_ "VFrameFormat" BO_ 1121 14;
BA_ "GenMsgCycleTime" BO_ 1122 0;
BA_ "VFrameFormat" BO_ 1122 14;
BA_ "GenMsgCycleTime" BO_ 1123 0;
BA_ "VFrameFormat" BO_ 1123 14;
BA_ "GenMsgCycleTime" BO_ 1124 0;
BA_ "VFrameFormat" BO_ 1124 14;
BA_ "GenMsgCycleTime" BO_ 1125 0;
BA_ "VFrameFormat" BO_ 1125 14;
BA_ "GenMsgCycleTime" BO_ 1126 0;
BA_ "VFrameFormat" BO_ 1126 14;
BA_ "GenMsgCycleTime" BO_ 1131 0;
BA_ "VFrameFormat" BO_ 1131 14;
BA_ "GenMsgCycleTime" BO_ 1132 0;
BA_ "VFrameFormat" BO_ 1132 14;
BA_ "GenMsgCycleTime" BO_ 1133 0;
BA_ "VFrameFormat" BO_ 1133 14;
BA_ "GenMsgCycleTime" BO_ 1134 0;
BA_ "VFrameFormat" BO_ 1134 14;
BA_ "GenMsgCycleTime" BO_ 1135 0;
BA_ "VFrameFormat" BO_ 1135 14;
BA_ "GenMsgCycleTime" BO_ 1136 0;
BA_ "VFrameFormat" BO_ 1136 14;
BA_ "GenMsgCycleTime" BO_ 1141 0;
BA_ "VFrameFormat" BO_ 1141 14;
BA_ "GenMsgCycleTime" BO_ 1142 0;
BA_ "VFrameFormat" BO_ 1142 14;
BA_ "GenMsgCycleTime" BO_ 1143 0;
BA_ "VFrameFormat" BO_ 1143 14;
BA_ "GenMsgCycleTime" BO_ 1144 0;
BA_ "VFrameFormat" BO_ 1144 14;
BA_ "GenMsgCycleTime" BO_ 1145 0;
BA_ "VFrameFormat" BO_ 1145 14;
BA_ "GenMsgCycleTime" BO_ 1146 0;
BA_ "VFrameFormat" BO_ 1146 14;
BA_ "GenMsgCycleTime" BO_ 1151 0;
BA_ "VFrameFormat" BO_ 1151 14;
BA_ "GenMsgCycleTime" BO_ 1152 0;
BA_ "VFrameFormat" BO_ 1152 14;
BA_ "GenMsgCycleTime" BO_ 1153 0;
BA_ "VFrameFormat" BO_ 1153 14;
BA_ "GenMsgCycleTime" BO_ 1154 0;
BA_ "VFrameFormat" BO_ 1154 14;
BA_ "GenMsgCycleTime" BO_ 1155 0;
BA_ "VFrameFormat" BO_ 1155 14;
BA_ "GenMsgCycleTime" BO_ 1156 0;
BA_ "VFrameFormat" BO_ 1156 14;
BA_ "GenMsgCycleTime" BO_ 1161 0;
BA_ "VFrameFormat" BO_ 1161 14;
BA_ "GenMsgCycleTime" BO_ 1162 0;
BA_ "VFrameFormat" BO_ 1162 14;
BA_ "GenMsgCycleTime" BO_ 1163 0;
BA_ "VFrameFormat" BO_ 1163 14;
BA_ "GenMsgCycleTime" BO_ 1164 0;
BA_ "VFrameFormat" BO_ 1164 14;
BA_ "GenMsgCycleTime" BO_ 1165 0;
BA_ "VFrameFormat" BO_ 1165 14;
BA_ "GenMsgCycleTime" BO_ 1166 0;
BA_ "VFrameFormat" BO_ 1166 14;
BA_ "GenMsgCycleTime" BO_ 1171 0;
BA_ "VFrameFormat" BO_ 1171 14;
BA_ "GenMsgCycleTime" BO_ 1172 0;
BA_ "VFrameFormat" BO_ 1172 14;
BA_ "GenMsgCycleTime" BO_ 1173 0;
BA_ "VFrameFormat" BO_ 1173 14;
BA_ "GenMsgCycleTime" BO_ 1174 0;
BA_ "VFrameFormat" BO_ 1174 14;
BA_ "GenMsgCycleTime" BO_ 1175 0;
BA_ "VFrameFormat" BO_ 1175 14;
BA_ "GenMsgCycleTime" BO_ 1176 0;
BA_ "VFrameFormat" BO_ 1176 14;
BA_ "GenMsgCycleTime" BO_ 1181 0;
BA_ "VFrameFormat" BO_ 1181 14;
BA_ "GenMsgCycleTime" BO_ 1182 0;
BA_ "VFrameFormat" BO_ 1182 14;
BA_ "GenMsgCycleTime" BO_ 1183 0;
BA_ "VFrameFormat" BO_ 1183 14;
BA_ "GenMsgCycleTime" BO_ 1184 0;
BA_ "VFrameFormat" BO_ 1184 14;
BA_ "GenMsgCycleTime" BO_ 1185 0;
BA_ "VFrameFormat" BO_ 1185 14;
BA_ "GenMsgCycleTime" BO_ 1186 0;
BA_ "VFrameFormat" BO_ 1186 14;
BA_ "GenMsgCycleTime" BO_ 1191 0;
BA_ "VFrameFormat" BO_ 1191 14;
BA_ "GenMsgCycleTime" BO_ 1192 0;
BA_ "VFrameFormat" BO_ 1192 14;
BA_ "GenMsgCycleTime" BO_ 1193 0;
BA_ "VFrameFormat" BO_ 1193 14;
BA_ "GenMsgCycleTime" BO_ 1194 0;
BA_ "VFrameFormat" BO_ 1194 14;
BA_ "GenMsgCycleTime" BO_ 1195 0;
BA_ "VFrameFormat" BO_ 1195 14;
BA_ "GenMsgCycleTime" BO_ 1196 0;
BA_ "VFrameFormat" BO_ 1196 14;
BA_ "GenMsgCycleTime" BO_ 1201 0;
BA_ "VFrameFormat" BO_ 1201 14;
BA_ "GenMsgCycleTime" BO_ 1202 0;
BA_ "VFrameFormat" BO_ 1202 14;
BA_ "GenMsgCycleTime" BO_ 1203 0;
BA_ "VFrameFormat" BO_ 1203 14;
BA_ "GenMsgCycleTime" BO_ 1204 0;
BA_ "VFrameFormat" BO_ 1204 14;
BA_ "GenMsgCycleTime" BO_ 1205 0;
BA_ "VFrameFormat" BO_ 1205 14;
BA_ "GenMsgCycleTime" BO_ 1206 0;
BA_ "VFrameFormat" BO_ 1206 14;
BA_ "GenMsgCycleTime" BO_ 1211 0;
BA_ "VFrameFormat" BO_ 1211 14;

VAL_ 1026 CameraID_402h 0 "Default" 1 "Fisheye-Back" 2 "Fisheye-Front" 3 "Fisheye-Left" 4 "Fisheye-Right" 5 "Narrow-Back" 6 "Narrow-Back-Left" 7 "Narrow-Left" 8 "Narrow-Front-Left" 9 "Narrow-Front" 10 "Narrow-Front-Right" 11 "Narrow-Right" 12 "Narrow-Back-Right";
VAL_ 1040 CIPV_TTC_Valid_410h 0 "NotValid" 1 "Valid";
VAL_ 1040 MCP_TTC_Valid_410h 0 "NotValid" 1 "Valid";
VAL_ 1041 ObstacleValid_411h 0 "invalid Obstacle(default value)" 1 "new valid (detected this frame)" 2 "older valid";
VAL_ 1041 ObstacleReplaced_411h 0 "not replaced in this frame" 1 "replaced in this frame";
VAL_ 1041 ObstacleMotionCategory_411h 0 "INVALID" 1 "UNDEFINED" 2 "PASSING" 3 "PASSING_IN" 4 "PASSING_OUT" 5 "CLOSE_CUT_IN" 6 "MOVING_IN" 7 "MOVING_OUT" 8 "CROSSING" 9 "LTAP" 10 "RTAP" 11 "MOVING" 12 "PRECEEDING" 13 "ONCOMING";
VAL_ 1041 ObstacleMotionStatus_411h 0 "INVALID" 1 "UNKNOWN" 2 "MOVING" 3 "STATIONARY" 4 "STOPPED" 5 "MOVING SLOWLY";
VAL_ 1041 ObstacleMeasuringStatus_411h 0 "INVALID" 1 "MEASURED" 2 "PREDICTED";
VAL_ 1041 ObstacleClass_411h 0 "INVALID" 1 "VEHICLE" 2 "PEDESTRIAN" 3 "CYCLIST" 4 "GENERAL_OBJECT";
VAL_ 1041 VehicleSubType_411h 0 "Unknown" 1 "Bus" 2 "Small_Medium_Car" 3 "Trucks" 4 "Motors(Tri-cycle)" 5 "Special_vehicle" 6 "Tiny_car" 7 "Lorry";
VAL_ 1041 PedSubType_411h 0 "Unknown" 1 "Adult" 2 "Child";
VAL_ 1041 PedPos_411h 0 "Unknown" 1 "Bended" 2 "Cyclist" 3 "Lier" 4 "Pedestrian" 5 "Sitter";
VAL_ 1041 PedOrientation_411h 0 "Unknown" 1 "back" 2 "front" 3 "left" 4 "left_anterior" 5 "left_back" 6 "right" 7 "right_front" 8 "right_back";
VAL_ 1041 ObstacleLaneAssignment_411h 0 "UNKNOWN" 1 "LEFT_LEFT" 2 "LEFT" 3 "HOST" 4 "RIGHT" 5 "RIGHT_RIGHT";
VAL_ 1042 CIPVFlag_412h 0 "not CIPV" 1 "CIPV";
VAL_ 1042 MCPFlag_412h 0 "not MCP" 1 "MCP";
VAL_ 1042 ObstacleBlinkerInfo_412h 0 "Unavailable" 1 "Off" 2 "Left" 3 "Right" 4 "Both";
VAL_ 1042 ObstacleBrakeLights_412h 0 "OFF" 1 "ON";
VAL_ 1042 ObstaclePositionType_412h 0 "Unknown" 1 "RearLeft" 2 "RearCenter" 3 "RearRight" 4 "FrontLeft" 5 "FrontCenter" 6 "FrontRight" 7 "LeftCenter" 8 "RightCenter" 9 "Center";
VAL_ 1042 CutInFlag_412h 0 "not Cut In" 1 "Cut In" 2 "Close Cut In";
VAL_ 1051 ObstacleValid_41Bh 0 "invalid Obstacle(default value)" 1 "new valid (detected this frame)" 2 "older valid";
VAL_ 1051 ObstacleReplaced_41Bh 0 "not replaced in this frame" 1 "replaced in this frame";
VAL_ 1051 ObstacleMotionCategory_41Bh 0 "INVALID" 1 "UNDEFINED" 2 "PASSING" 3 "PASSING_IN" 4 "PASSING_OUT" 5 "CLOSE_CUT_IN" 6 "MOVING_IN" 7 "MOVING_OUT" 8 "CROSSING" 9 "LTAP" 10 "RTAP" 11 "MOVING" 12 "PRECEEDING" 13 "ONCOMING";
VAL_ 1051 ObstacleMotionStatus_41Bh 0 "INVALID" 1 "UNKNOWN" 2 "MOVING" 3 "STATIONARY" 4 "STOPPED" 5 "MOVING SLOWLY";
VAL_ 1051 ObstacleMeasuringStatus_41Bh 0 "INVALID" 1 "MEASURED" 2 "PREDICTED";
VAL_ 1051 ObstacleClass_41Bh 0 "INVALID" 1 "VEHICLE" 2 "PEDESTRIAN" 3 "CYCLIST" 4 "GENERAL_OBJECT";
VAL_ 1051 VehicleSubType_41Bh 0 "Unknown" 1 "Bus" 2 "Small_Medium_Car" 3 "Trucks" 4 "Motors(Tri-cycle)" 5 "Special_vehicle" 6 "Tiny_car" 7 "Lorry";
VAL_ 1051 PedSubType_41Bh 0 "Unknown" 1 "Adult" 2 "Child";
VAL_ 1051 PedPos_41Bh 0 "Unknown" 1 "Bended" 2 "Cyclist" 3 "Lier" 4 "Pedestrian" 5 "Sitter";
VAL_ 1051 PedOrientation_41Bh 0 "Unknown" 1 "back" 2 "front" 3 "left" 4 "left_anterior" 5 "left_back" 6 "right" 7 "right_front" 8 "right_back";
VAL_ 1051 ObstacleLaneAssignment_41Bh 0 "UNKNOWN" 1 "LEFT_LEFT" 2 "LEFT" 3 "HOST" 4 "RIGHT" 5 "RIGHT_RIGHT";
VAL_ 1052 CIPVFlag_41Ch 0 "not CIPV" 1 "CIPV";
VAL_ 1052 MCPFlag_41Ch 0 "not MCP" 1 "MCP";
VAL_ 1052 ObstacleBlinkerInfo_41Ch 0 "Unavailable" 1 "Off" 2 "Left" 3 "Right" 4 "Both";
VAL_ 1052 ObstacleBrakeLights_41Ch 0 "OFF" 1 "ON";
VAL_ 1052 ObstaclePositionType_41Ch 0 "Unknown" 1 "RearLeft" 2 "RearCenter" 3 "RearRight" 4 "FrontLeft" 5 "FrontCenter" 6 "FrontRight" 7 "LeftCenter" 8 "RightCenter" 9 "Center";
VAL_ 1052 CutInFlag_41Ch 0 "not Cut In" 1 "Cut In" 2 "Close Cut In";
VAL_ 1061 ObstacleValid_425h 0 "invalid Obstacle(default value)" 1 "new valid (detected this frame)" 2 "older valid";
VAL_ 1061 ObstacleReplaced_425h 0 "not replaced in this frame" 1 "replaced in this frame";
VAL_ 1061 ObstacleMotionCategory_425h 0 "INVALID" 1 "UNDEFINED" 2 "PASSING" 3 "PASSING_IN" 4 "PASSING_OUT" 5 "CLOSE_CUT_IN" 6 "MOVING_IN" 7 "MOVING_OUT" 8 "CROSSING" 9 "LTAP" 10 "RTAP" 11 "MOVING" 12 "PRECEEDING" 13 "ONCOMING";
VAL_ 1061 ObstacleMotionStatus_425h 0 "INVALID" 1 "UNKNOWN" 2 "MOVING" 3 "STATIONARY" 4 "STOPPED" 5 "MOVING SLOWLY";
VAL_ 1061 ObstacleMeasuringStatus_425h 0 "INVALID" 1 "MEASURED" 2 "PREDICTED";
VAL_ 1061 ObstacleClass_425h 0 "INVALID" 1 "VEHICLE" 2 "PEDESTRIAN" 3 "CYCLIST" 4 "GENERAL_OBJECT";
VAL_ 1061 VehicleSubType_425h 0 "Unknown" 1 "Bus" 2 "Small_Medium_Car" 3 "Trucks" 4 "Motors(Tri-cycle)" 5 "Special_vehicle" 6 "Tiny_car" 7 "Lorry";
VAL_ 1061 PedSubType_425h 0 "Unknown" 1 "Adult" 2 "Child";
VAL_ 1061 PedPos_425h 0 "Unknown" 1 "Bended" 2 "Cyclist" 3 "Lier" 4 "Pedestrian" 5 "Sitter";
VAL_ 1061 PedOrientation_425h 0 "Unknown" 1 "back" 2 "front" 3 "left" 4 "left_anterior" 5 "left_back" 6 "right" 7 "right_front" 8 "right_back";
VAL_ 1061 ObstacleLaneAssignment_425h 0 "UNKNOWN" 1 "LEFT_LEFT" 2 "LEFT" 3 "HOST" 4 "RIGHT" 5 "RIGHT_RIGHT";
VAL_ 1062 CIPVFlag_426h 0 "not CIPV" 1 "CIPV";
VAL_ 1062 MCPFlag_426h 0 "not MCP" 1 "MCP";
VAL_ 1062 ObstacleBlinkerInfo_426h 0 "Unavailable" 1 "Off" 2 "Left" 3 "Right" 4 "Both";
VAL_ 1062 ObstacleBrakeLights_426h 0 "OFF" 1 "ON";
VAL_ 1062 ObstaclePositionType_426h 0 "Unknown" 1 "RearLeft" 2 "RearCenter" 3 "RearRight" 4 "FrontLeft" 5 "FrontCenter" 6 "FrontRight" 7 "LeftCenter" 8 "RightCenter" 9 "Center";
VAL_ 1062 CutInFlag_426h 0 "not Cut In" 1 "Cut In" 2 "Close Cut In";
VAL_ 1071 ObstacleValid_42Fh 0 "invalid Obstacle(default value)" 1 "new valid (detected this frame)" 2 "older valid";
VAL_ 1071 ObstacleReplaced_42Fh 0 "not replaced in this frame" 1 "replaced in this frame";
VAL_ 1071 ObstacleMotionCategory_42Fh 0 "INVALID" 1 "UNDEFINED" 2 "PASSING" 3 "PASSING_IN" 4 "PASSING_OUT" 5 "CLOSE_CUT_IN" 6 "MOVING_IN" 7 "MOVING_OUT" 8 "CROSSING" 9 "LTAP" 10 "RTAP" 11 "MOVING" 12 "PRECEEDING" 13 "ONCOMING";
VAL_ 1071 ObstacleMotionStatus_42Fh 0 "INVALID" 1 "UNKNOWN" 2 "MOVING" 3 "STATIONARY" 4 "STOPPED" 5 "MOVING SLOWLY";
VAL_ 1071 ObstacleMeasuringStatus_42Fh 0 "INVALID" 1 "MEASURED" 2 "PREDICTED";
VAL_ 1071 ObstacleClass_42Fh 0 "INVALID" 1 "VEHICLE" 2 "PEDESTRIAN" 3 "CYCLIST" 4 "GENERAL_OBJECT";
VAL_ 1071 VehicleSubType_42Fh 0 "Unknown" 1 "Bus" 2 "Small_Medium_Car" 3 "Trucks" 4 "Motors(Tri-cycle)" 5 "Special_vehicle" 6 "Tiny_car" 7 "Lorry";
VAL_ 1071 PedSubType_42Fh 0 "Unknown" 1 "Adult" 2 "Child";
VAL_ 1071 PedPos_42Fh 0 "Unknown" 1 "Bended" 2 "Cyclist" 3 "Lier" 4 "Pedestrian" 5 "Sitter";
VAL_ 1071 PedOrientation_42Fh 0 "Unknown" 1 "back" 2 "front" 3 "left" 4 "left_anterior" 5 "left_back" 6 "right" 7 "right_front" 8 "right_back";
VAL_ 1071 ObstacleLaneAssignment_42Fh 0 "UNKNOWN" 1 "LEFT_LEFT" 2 "LEFT" 3 "HOST" 4 "RIGHT" 5 "RIGHT_RIGHT";
VAL_ 1072 CIPVFlag_430h 0 "not CIPV" 1 "CIPV";
VAL_ 1072 MCPFlag_430h 0 "not MCP" 1 "MCP";
VAL_ 1072 ObstacleBlinkerInfo_430h 0 "Unavailable" 1 "Off" 2 "Left" 3 "Right" 4 "Both";
VAL_ 1072 ObstacleBrakeLights_430h 0 "OFF" 1 "ON";
VAL_ 1072 ObstaclePositionType_430h 0 "Unknown" 1 "RearLeft" 2 "RearCenter" 3 "RearRight" 4 "FrontLeft" 5 "FrontCenter" 6 "FrontRight" 7 "LeftCenter" 8 "RightCenter" 9 "Center";
VAL_ 1072 CutInFlag_430h 0 "not Cut In" 1 "Cut In" 2 "Close Cut In";
VAL_ 1081 ObstacleValid_439h 0 "invalid Obstacle(default value)" 1 "new valid (detected this frame)" 2 "older valid";
VAL_ 1081 ObstacleReplaced_439h 0 "not replaced in this frame" 1 "replaced in this frame";
VAL_ 1081 ObstacleMotionCategory_439h 0 "INVALID" 1 "UNDEFINED" 2 "PASSING" 3 "PASSING_IN" 4 "PASSING_OUT" 5 "CLOSE_CUT_IN" 6 "MOVING_IN" 7 "MOVING_OUT" 8 "CROSSING" 9 "LTAP" 10 "RTAP" 11 "MOVING" 12 "PRECEEDING" 13 "ONCOMING";
VAL_ 1081 ObstacleMotionStatus_439h 0 "INVALID" 1 "UNKNOWN" 2 "MOVING" 3 "STATIONARY" 4 "STOPPED" 5 "MOVING SLOWLY";
VAL_ 1081 ObstacleMeasuringStatus_439h 0 "INVALID" 1 "MEASURED" 2 "PREDICTED";
VAL_ 1081 ObstacleClass_439h 0 "INVALID" 1 "VEHICLE" 2 "PEDESTRIAN" 3 "CYCLIST" 4 "GENERAL_OBJECT";
VAL_ 1081 VehicleSubType_439h 0 "Unknown" 1 "Bus" 2 "Small_Medium_Car" 3 "Trucks" 4 "Motors(Tri-cycle)" 5 "Special_vehicle" 6 "Tiny_car" 7 "Lorry";
VAL_ 1081 PedSubType_439h 0 "Unknown" 1 "Adult" 2 "Child";
VAL_ 1081 PedPos_439h 0 "Unknown" 1 "Bended" 2 "Cyclist" 3 "Lier" 4 "Pedestrian" 5 "Sitter";
VAL_ 1081 PedOrientation_439h 0 "Unknown" 1 "back" 2 "front" 3 "left" 4 "left_anterior" 5 "left_back" 6 "right" 7 "right_front" 8 "right_back";
VAL_ 1081 ObstacleLaneAssignment_439h 0 "UNKNOWN" 1 "LEFT_LEFT" 2 "LEFT" 3 "HOST" 4 "RIGHT" 5 "RIGHT_RIGHT";
VAL_ 1082 CIPVFlag_43Ah 0 "not CIPV" 1 "CIPV";
VAL_ 1082 MCPFlag_43Ah 0 "not MCP" 1 "MCP";
VAL_ 1082 ObstacleBlinkerInfo_43Ah 0 "Unavailable" 1 "Off" 2 "Left" 3 "Right" 4 "Both";
VAL_ 1082 ObstacleBrakeLights_43Ah 0 "OFF" 1 "ON";
VAL_ 1082 ObstaclePositionType_43Ah 0 "Unknown" 1 "RearLeft" 2 "RearCenter" 3 "RearRight" 4 "FrontLeft" 5 "FrontCenter" 6 "FrontRight" 7 "LeftCenter" 8 "RightCenter" 9 "Center";
VAL_ 1082 CutInFlag_43Ah 0 "not Cut In" 1 "Cut In" 2 "Close Cut In";
VAL_ 1091 ObstacleValid_443h 0 "invalid Obstacle(default value)" 1 "new valid (detected this frame)" 2 "older valid";
VAL_ 1091 ObstacleReplaced_443h 0 "not replaced in this frame" 1 "replaced in this frame";
VAL_ 1091 ObstacleMotionCategory_443h 0 "INVALID" 1 "UNDEFINED" 2 "PASSING" 3 "PASSING_IN" 4 "PASSING_OUT" 5 "CLOSE_CUT_IN" 6 "MOVING_IN" 7 "MOVING_OUT" 8 "CROSSING" 9 "LTAP" 10 "RTAP" 11 "MOVING" 12 "PRECEEDING" 13 "ONCOMING";
VAL_ 1091 ObstacleMotionStatus_443h 0 "INVALID" 1 "UNKNOWN" 2 "MOVING" 3 "STATIONARY" 4 "STOPPED" 5 "MOVING SLOWLY";
VAL_ 1091 ObstacleMeasuringStatus_443h 0 "INVALID" 1 "MEASURED" 2 "PREDICTED";
VAL_ 1091 ObstacleClass_443h 0 "INVALID" 1 "VEHICLE" 2 "PEDESTRIAN" 3 "CYCLIST" 4 "GENERAL_OBJECT";
VAL_ 1091 VehicleSubType_443h 0 "Unknown" 1 "Bus" 2 "Small_Medium_Car" 3 "Trucks" 4 "Motors(Tri-cycle)" 5 "Special_vehicle" 6 "Tiny_car" 7 "Lorry";
VAL_ 1091 PedSubType_443h 0 "Unknown" 1 "Adult" 2 "Child";
VAL_ 1091 PedPos_443h 0 "Unknown" 1 "Bended" 2 "Cyclist" 3 "Lier" 4 "Pedestrian" 5 "Sitter";
VAL_ 1091 PedOrientation_443h 0 "Unknown" 1 "back" 2 "front" 3 "left" 4 "left_anterior" 5 "left_back" 6 "right" 7 "right_front" 8 "right_back";
VAL_ 1091 ObstacleLaneAssignment_443h 0 "UNKNOWN" 1 "LEFT_LEFT" 2 "LEFT" 3 "HOST" 4 "RIGHT" 5 "RIGHT_RIGHT";
VAL_ 1092 CIPVFlag_444h 0 "not CIPV" 1 "CIPV";
VAL_ 1092 MCPFlag_444h 0 "not MCP" 1 "MCP";
VAL_ 1092 ObstacleBlinkerInfo_444h 0 "Unavailable" 1 "Off" 2 "Left" 3 "Right" 4 "Both";
VAL_ 1092 ObstacleBrakeLights_444h 0 "OFF" 1 "ON";
VAL_ 1092 ObstaclePositionType_444h 0 "Unknown" 1 "RearLeft" 2 "RearCenter" 3 "RearRight" 4 "FrontLeft" 5 "FrontCenter" 6 "FrontRight" 7 "LeftCenter" 8 "RightCenter" 9 "Center";
VAL_ 1092 CutInFlag_444h 0 "not Cut In" 1 "Cut In" 2 "Close Cut In";
VAL_ 1101 ObstacleValid_44Dh 0 "invalid Obstacle(default value)" 1 "new valid (detected this frame)" 2 "older valid";
VAL_ 1101 ObstacleReplaced_44Dh 0 "not replaced in this frame" 1 "replaced in this frame";
VAL_ 1101 ObstacleMotionCategory_44Dh 0 "INVALID" 1 "UNDEFINED" 2 "PASSING" 3 "PASSING_IN" 4 "PASSING_OUT" 5 "CLOSE_CUT_IN" 6 "MOVING_IN" 7 "MOVING_OUT" 8 "CROSSING" 9 "LTAP" 10 "RTAP" 11 "MOVING" 12 "PRECEEDING" 13 "ONCOMING";
VAL_ 1101 ObstacleMotionStatus_44Dh 0 "INVALID" 1 "UNKNOWN" 2 "MOVING" 3 "STATIONARY" 4 "STOPPED" 5 "MOVING SLOWLY";
VAL_ 1101 ObstacleMeasuringStatus_44Dh 0 "INVALID" 1 "MEASURED" 2 "PREDICTED";
VAL_ 1101 ObstacleClass_44Dh 0 "INVALID" 1 "VEHICLE" 2 "PEDESTRIAN" 3 "CYCLIST" 4 "GENERAL_OBJECT";
VAL_ 1101 VehicleSubType_44Dh 0 "Unknown" 1 "Bus" 2 "Small_Medium_Car" 3 "Trucks" 4 "Motors(Tri-cycle)" 5 "Special_vehicle" 6 "Tiny_car" 7 "Lorry";
VAL_ 1101 PedSubType_44Dh 0 "Unknown" 1 "Adult" 2 "Child";
VAL_ 1101 PedPos_44Dh 0 "Unknown" 1 "Bended" 2 "Cyclist" 3 "Lier" 4 "Pedestrian" 5 "Sitter";
VAL_ 1101 PedOrientation_44Dh 0 "Unknown" 1 "back" 2 "front" 3 "left" 4 "left_anterior" 5 "left_back" 6 "right" 7 "right_front" 8 "right_back";
VAL_ 1101 ObstacleLaneAssignment_44Dh 0 "UNKNOWN" 1 "LEFT_LEFT" 2 "LEFT" 3 "HOST" 4 "RIGHT" 5 "RIGHT_RIGHT";
VAL_ 1102 CIPVFlag_44Eh 0 "not CIPV" 1 "CIPV";
VAL_ 1102 MCPFlag_44Eh 0 "not MCP" 1 "MCP";
VAL_ 1102 ObstacleBlinkerInfo_44Eh 0 "Unavailable" 1 "Off" 2 "Left" 3 "Right" 4 "Both";
VAL_ 1102 ObstacleBrakeLights_44Eh 0 "OFF" 1 "ON";
VAL_ 1102 ObstaclePositionType_44Eh 0 "Unknown" 1 "RearLeft" 2 "RearCenter" 3 "RearRight" 4 "FrontLeft" 5 "FrontCenter" 6 "FrontRight" 7 "LeftCenter" 8 "RightCenter" 9 "Center";
VAL_ 1102 CutInFlag_44Eh 0 "not Cut In" 1 "Cut In" 2 "Close Cut In";
VAL_ 1111 ObstacleValid_457h 0 "invalid Obstacle(default value)" 1 "new valid (detected this frame)" 2 "older valid";
VAL_ 1111 ObstacleReplaced_457h 0 "not replaced in this frame" 1 "replaced in this frame";
VAL_ 1111 ObstacleMotionCategory_457h 0 "INVALID" 1 "UNDEFINED" 2 "PASSING" 3 "PASSING_IN" 4 "PASSING_OUT" 5 "CLOSE_CUT_IN" 6 "MOVING_IN" 7 "MOVING_OUT" 8 "CROSSING" 9 "LTAP" 10 "RTAP" 11 "MOVING" 12 "PRECEEDING" 13 "ONCOMING";
VAL_ 1111 ObstacleMotionStatus_457h 0 "INVALID" 1 "UNKNOWN" 2 "MOVING" 3 "STATIONARY" 4 "STOPPED" 5 "MOVING SLOWLY";
VAL_ 1111 ObstacleMeasuringStatus_457h 0 "INVALID" 1 "MEASURED" 2 "PREDICTED";
VAL_ 1111 ObstacleClass_457h 0 "INVALID" 1 "VEHICLE" 2 "PEDESTRIAN" 3 "CYCLIST" 4 "GENERAL_OBJECT";
VAL_ 1111 VehicleSubType_457h 0 "Unknown" 1 "Bus" 2 "Small_Medium_Car" 3 "Trucks" 4 "Motors(Tri-cycle)" 5 "Special_vehicle" 6 "Tiny_car" 7 "Lorry";
VAL_ 1111 PedSubType_457h 0 "Unknown" 1 "Adult" 2 "Child";
VAL_ 1111 PedPos_457h 0 "Unknown" 1 "Bended" 2 "Cyclist" 3 "Lier" 4 "Pedestrian" 5 "Sitter";
VAL_ 1111 PedOrientation_457h 0 "Unknown" 1 "back" 2 "front" 3 "left" 4 "left_anterior" 5 "left_back" 6 "right" 7 "right_front" 8 "right_back";
VAL_ 1111 ObstacleLaneAssignment_457h 0 "UNKNOWN" 1 "LEFT_LEFT" 2 "LEFT" 3 "HOST" 4 "RIGHT" 5 "RIGHT_RIGHT";
VAL_ 1112 CIPVFlag_458h 0 "not CIPV" 1 "CIPV";
VAL_ 1112 MCPFlag_458h 0 "not MCP" 1 "MCP";
VAL_ 1112 ObstacleBlinkerInfo_458h 0 "Unavailable" 1 "Off" 2 "Left" 3 "Right" 4 "Both";
VAL_ 1112 ObstacleBrakeLights_458h 0 "OFF" 1 "ON";
VAL_ 1112 ObstaclePositionType_458h 0 "Unknown" 1 "RearLeft" 2 "RearCenter" 3 "RearRight" 4 "FrontLeft" 5 "FrontCenter" 6 "FrontRight" 7 "LeftCenter" 8 "RightCenter" 9 "Center";
VAL_ 1112 CutInFlag_458h 0 "not Cut In" 1 "Cut In" 2 "Close Cut In";
VAL_ 1121 ObstacleValid_461h 0 "invalid Obstacle(default value)" 1 "new valid (detected this frame)" 2 "older valid";
VAL_ 1121 ObstacleReplaced_461h 0 "not replaced in this frame" 1 "replaced in this frame";
VAL_ 1121 ObstacleMotionCategory_461h 0 "INVALID" 1 "UNDEFINED" 2 "PASSING" 3 "PASSING_IN" 4 "PASSING_OUT" 5 "CLOSE_CUT_IN" 6 "MOVING_IN" 7 "MOVING_OUT" 8 "CROSSING" 9 "LTAP" 10 "RTAP" 11 "MOVING" 12 "PRECEEDING" 13 "ONCOMING";
VAL_ 1121 ObstacleMotionStatus_461h 0 "INVALID" 1 "UNKNOWN" 2 "MOVING" 3 "STATIONARY" 4 "STOPPED" 5 "MOVING SLOWLY";
VAL_ 1121 ObstacleMeasuringStatus_461h 0 "INVALID" 1 "MEASURED" 2 "PREDICTED";
VAL_ 1121 ObstacleClass_461h 0 "INVALID" 1 "VEHICLE" 2 "PEDESTRIAN" 3 "CYCLIST" 4 "GENERAL_OBJECT";
VAL_ 1121 VehicleSubType_461h 0 "Unknown" 1 "Bus" 2 "Small_Medium_Car" 3 "Trucks" 4 "Motors(Tri-cycle)" 5 "Special_vehicle" 6 "Tiny_car" 7 "Lorry";
VAL_ 1121 PedSubType_461h 0 "Unknown" 1 "Adult" 2 "Child";
VAL_ 1121 PedPos_461h 0 "Unknown" 1 "Bended" 2 "Cyclist" 3 "Lier" 4 "Pedestrian" 5 "Sitter";
VAL_ 1121 PedOrientation_461h 0 "Unknown" 1 "back" 2 "front" 3 "left" 4 "left_anterior" 5 "left_back" 6 "right" 7 "right_front" 8 "right_back";
VAL_ 1121 ObstacleLaneAssignment_461h 0 "UNKNOWN" 1 "LEFT_LEFT" 2 "LEFT" 3 "HOST" 4 "RIGHT" 5 "RIGHT_RIGHT";
VAL_ 1122 CIPVFlag_462h 0 "not CIPV" 1 "CIPV";
VAL_ 1122 MCPFlag_462h 0 "not MCP" 1 "MCP";
VAL_ 1122 ObstacleBlinkerInfo_462h 0 "Unavailable" 1 "Off" 2 "Left" 3 "Right" 4 "Both";
VAL_ 1122 ObstacleBrakeLights_462h 0 "OFF" 1 "ON";
VAL_ 1122 ObstaclePositionType_462h 0 "Unknown" 1 "RearLeft" 2 "RearCenter" 3 "RearRight" 4 "FrontLeft" 5 "FrontCenter" 6 "FrontRight" 7 "LeftCenter" 8 "RightCenter" 9 "Center";
VAL_ 1122 CutInFlag_462h 0 "not Cut In" 1 "Cut In" 2 "Close Cut In";
VAL_ 1131 ObstacleValid_46Bh 0 "invalid Obstacle(default value)" 1 "new valid (detected this frame)" 2 "older valid";
VAL_ 1131 ObstacleReplaced_46Bh 0 "not replaced in this frame" 1 "replaced in this frame";
VAL_ 1131 ObstacleMotionCategory_46Bh 0 "INVALID" 1 "UNDEFINED" 2 "PASSING" 3 "PASSING_IN" 4 "PASSING_OUT" 5 "CLOSE_CUT_IN" 6 "MOVING_IN" 7 "MOVING_OUT" 8 "CROSSING" 9 "LTAP" 10 "RTAP" 11 "MOVING" 12 "PRECEEDING" 13 "ONCOMING";
VAL_ 1131 ObstacleMotionStatus_46Bh 0 "INVALID" 1 "UNKNOWN" 2 "MOVING" 3 "STATIONARY" 4 "STOPPED" 5 "MOVING SLOWLY";
VAL_ 1131 ObstacleMeasuringStatus_46Bh 0 "INVALID" 1 "MEASURED" 2 "PREDICTED";
VAL_ 1131 ObstacleClass_46Bh 0 "INVALID" 1 "VEHICLE" 2 "PEDESTRIAN" 3 "CYCLIST" 4 "GENERAL_OBJECT";
VAL_ 1131 VehicleSubType_46Bh 0 "Unknown" 1 "Bus" 2 "Small_Medium_Car" 3 "Trucks" 4 "Motors(Tri-cycle)" 5 "Special_vehicle" 6 "Tiny_car" 7 "Lorry";
VAL_ 1131 PedSubType_46Bh 0 "Unknown" 1 "Adult" 2 "Child";
VAL_ 1131 PedPos_46Bh 0 "Unknown" 1 "Bended" 2 "Cyclist" 3 "Lier" 4 "Pedestrian" 5 "Sitter";
VAL_ 1131 PedOrientation_46Bh 0 "Unknown" 1 "back" 2 "front" 3 "left" 4 "left_anterior" 5 "left_back" 6 "right" 7 "right_front" 8 "right_back";
VAL_ 1131 ObstacleLaneAssignment_46Bh 0 "UNKNOWN" 1 "LEFT_LEFT" 2 "LEFT" 3 "HOST" 4 "RIGHT" 5 "RIGHT_RIGHT";
VAL_ 1132 CIPVFlag_46Ch 0 "not CIPV" 1 "CIPV";
VAL_ 1132 MCPFlag_46Ch 0 "not MCP" 1 "MCP";
VAL_ 1132 ObstacleBlinkerInfo_46Ch 0 "Unavailable" 1 "Off" 2 "Left" 3 "Right" 4 "Both";
VAL_ 1132 ObstacleBrakeLights_46Ch 0 "OFF" 1 "ON";
VAL_ 1132 ObstaclePositionType_46Ch 0 "Unknown" 1 "RearLeft" 2 "RearCenter" 3 "RearRight" 4 "FrontLeft" 5 "FrontCenter" 6 "FrontRight" 7 "LeftCenter" 8 "RightCenter" 9 "Center";
VAL_ 1132 CutInFlag_46Ch 0 "not Cut In" 1 "Cut In" 2 "Close Cut In";
VAL_ 1141 ObstacleValid_475h 0 "invalid Obstacle(default value)" 1 "new valid (detected this frame)" 2 "older valid";
VAL_ 1141 ObstacleReplaced_475h 0 "not replaced in this frame" 1 "replaced in this frame";
VAL_ 1141 ObstacleMotionCategory_475h 0 "INVALID" 1 "UNDEFINED" 2 "PASSING" 3 "PASSING_IN" 4 "PASSING_OUT" 5 "CLOSE_CUT_IN" 6 "MOVING_IN" 7 "MOVING_OUT" 8 "CROSSING" 9 "LTAP" 10 "RTAP" 11 "MOVING" 12 "PRECEEDING" 13 "ONCOMING";
VAL_ 1141 ObstacleMotionStatus_475h 0 "INVALID" 1 "UNKNOWN" 2 "MOVING" 3 "STATIONARY" 4 "STOPPED" 5 "MOVING SLOWLY";
VAL_ 1141 ObstacleMeasuringStatus_475h 0 "INVALID" 1 "MEASURED" 2 "PREDICTED";
VAL_ 1141 ObstacleClass_475h 0 "INVALID" 1 "VEHICLE" 2 "PEDESTRIAN" 3 "CYCLIST" 4 "GENERAL_OBJECT";
VAL_ 1141 VehicleSubType_475h 0 "Unknown" 1 "Bus" 2 "Small_Medium_Car" 3 "Trucks" 4 "Motors(Tri-cycle)" 5 "Special_vehicle" 6 "Tiny_car" 7 "Lorry";
VAL_ 1141 PedSubType_475h 0 "Unknown" 1 "Adult" 2 "Child";
VAL_ 1141 PedPos_475h 0 "Unknown" 1 "Bended" 2 "Cyclist" 3 "Lier" 4 "Pedestrian" 5 "Sitter";
VAL_ 1141 PedOrientation_475h 0 "Unknown" 1 "back" 2 "front" 3 "left" 4 "left_anterior" 5 "left_back" 6 "right" 7 "right_front" 8 "right_back";
VAL_ 1141 ObstacleLaneAssignment_475h 0 "UNKNOWN" 1 "LEFT_LEFT" 2 "LEFT" 3 "HOST" 4 "RIGHT" 5 "RIGHT_RIGHT";
VAL_ 1142 CIPVFlag_476h 0 "not CIPV" 1 "CIPV";
VAL_ 1142 MCPFlag_476h 0 "not MCP" 1 "MCP";
VAL_ 1142 ObstacleBlinkerInfo_476h 0 "Unavailable" 1 "Off" 2 "Left" 3 "Right" 4 "Both";
VAL_ 1142 ObstacleBrakeLights_476h 0 "OFF" 1 "ON";
VAL_ 1142 ObstaclePositionType_476h 0 "Unknown" 1 "RearLeft" 2 "RearCenter" 3 "RearRight" 4 "FrontLeft" 5 "FrontCenter" 6 "FrontRight" 7 "LeftCenter" 8 "RightCenter" 9 "Center";
VAL_ 1142 CutInFlag_476h 0 "not Cut In" 1 "Cut In" 2 "Close Cut In";
VAL_ 1151 ObstacleValid_47Fh 0 "invalid Obstacle(default value)" 1 "new valid (detected this frame)" 2 "older valid";
VAL_ 1151 ObstacleReplaced_47Fh 0 "not replaced in this frame" 1 "replaced in this frame";
VAL_ 1151 ObstacleMotionCategory_47Fh 0 "INVALID" 1 "UNDEFINED" 2 "PASSING" 3 "PASSING_IN" 4 "PASSING_OUT" 5 "CLOSE_CUT_IN" 6 "MOVING_IN" 7 "MOVING_OUT" 8 "CROSSING" 9 "LTAP" 10 "RTAP" 11 "MOVING" 12 "PRECEEDING" 13 "ONCOMING";
VAL_ 1151 ObstacleMotionStatus_47Fh 0 "INVALID" 1 "UNKNOWN" 2 "MOVING" 3 "STATIONARY" 4 "STOPPED" 5 "MOVING SLOWLY";
VAL_ 1151 ObstacleMeasuringStatus_47Fh 0 "INVALID" 1 "MEASURED" 2 "PREDICTED";
VAL_ 1151 ObstacleClass_47Fh 0 "INVALID" 1 "VEHICLE" 2 "PEDESTRIAN" 3 "CYCLIST" 4 "GENERAL_OBJECT";
VAL_ 1151 VehicleSubType_47Fh 0 "Unknown" 1 "Bus" 2 "Small_Medium_Car" 3 "Trucks" 4 "Motors(Tri-cycle)" 5 "Special_vehicle" 6 "Tiny_car" 7 "Lorry";
VAL_ 1151 PedSubType_47Fh 0 "Unknown" 1 "Adult" 2 "Child";
VAL_ 1151 PedPos_47Fh 0 "Unknown" 1 "Bended" 2 "Cyclist" 3 "Lier" 4 "Pedestrian" 5 "Sitter";
VAL_ 1151 PedOrientation_47Fh 0 "Unknown" 1 "back" 2 "front" 3 "left" 4 "left_anterior" 5 "left_back" 6 "right" 7 "right_front" 8 "right_back";
VAL_ 1151 ObstacleLaneAssignment_47Fh 0 "UNKNOWN" 1 "LEFT_LEFT" 2 "LEFT" 3 "HOST" 4 "RIGHT" 5 "RIGHT_RIGHT";
VAL_ 1152 CIPVFlag_480h 0 "not CIPV" 1 "CIPV";
VAL_ 1152 MCPFlag_480h 0 "not MCP" 1 "MCP";
VAL_ 1152 ObstacleBlinkerInfo_480h 0 "Unavailable" 1 "Off" 2 "Left" 3 "Right" 4 "Both";
VAL_ 1152 ObstacleBrakeLights_480h 0 "OFF" 1 "ON";
VAL_ 1152 ObstaclePositionType_480h 0 "Unknown" 1 "RearLeft" 2 "RearCenter" 3 "RearRight" 4 "FrontLeft" 5 "FrontCenter" 6 "FrontRight" 7 "LeftCenter" 8 "RightCenter" 9 "Center";
VAL_ 1152 CutInFlag_480h 0 "not Cut In" 1 "Cut In" 2 "Close Cut In";
VAL_ 1161 ObstacleValid_489h 0 "invalid Obstacle(default value)" 1 "new valid (detected this frame)" 2 "older valid";
VAL_ 1161 ObstacleReplaced_489h 0 "not replaced in this frame" 1 "replaced in this frame";
VAL_ 1161 ObstacleMotionCategory_489h 0 "INVALID" 1 "UNDEFINED" 2 "PASSING" 3 "PASSING_IN" 4 "PASSING_OUT" 5 "CLOSE_CUT_IN" 6 "MOVING_IN" 7 "MOVING_OUT" 8 "CROSSING" 9 "LTAP" 10 "RTAP" 11 "MOVING" 12 "PRECEEDING" 13 "ONCOMING";
VAL_ 1161 ObstacleMotionStatus_489h 0 "INVALID" 1 "UNKNOWN" 2 "MOVING" 3 "STATIONARY" 4 "STOPPED" 5 "MOVING SLOWLY";
VAL_ 1161 ObstacleMeasuringStatus_489h 0 "INVALID" 1 "MEASURED" 2 "PREDICTED";
VAL_ 1161 ObstacleClass_489h 0 "INVALID" 1 "VEHICLE" 2 "PEDESTRIAN" 3 "CYCLIST" 4 "GENERAL_OBJECT";
VAL_ 1161 VehicleSubType_489h 0 "Unknown" 1 "Bus" 2 "Small_Medium_Car" 3 "Trucks" 4 "Motors(Tri-cycle)" 5 "Special_vehicle" 6 "Tiny_car" 7 "Lorry";
VAL_ 1161 PedSubType_489h 0 "Unknown" 1 "Adult" 2 "Child";
VAL_ 1161 PedPos_489h 0 "Unknown" 1 "Bended" 2 "Cyclist" 3 "Lier" 4 "Pedestrian" 5 "Sitter";
VAL_ 1161 PedOrientation_489h 0 "Unknown" 1 "back" 2 "front" 3 "left" 4 "left_anterior" 5 "left_back" 6 "right" 7 "right_front" 8 "right_back";
VAL_ 1161 ObstacleLaneAssignment_489h 0 "UNKNOWN" 1 "LEFT_LEFT" 2 "LEFT" 3 "HOST" 4 "RIGHT" 5 "RIGHT_RIGHT";
VAL_ 1162 CIPVFlag_48Ah 0 "not CIPV" 1 "CIPV";
VAL_ 1162 MCPFlag_48Ah 0 "not MCP" 1 "MCP";
VAL_ 1162 ObstacleBlinkerInfo_48Ah 0 "Unavailable" 1 "Off" 2 "Left" 3 "Right" 4 "Both";
VAL_ 1162 ObstacleBrakeLights_48Ah 0 "OFF" 1 "ON";
VAL_ 1162 ObstaclePositionType_48Ah 0 "Unknown" 1 "RearLeft" 2 "RearCenter" 3 "RearRight" 4 "FrontLeft" 5 "FrontCenter" 6 "FrontRight" 7 "LeftCenter" 8 "RightCenter" 9 "Center";
VAL_ 1162 CutInFlag_48Ah 0 "not Cut In" 1 "Cut In" 2 "Close Cut In";
VAL_ 1171 ObstacleValid_493h 0 "invalid Obstacle(default value)" 1 "new valid (detected this frame)" 2 "older valid";
VAL_ 1171 ObstacleReplaced_493h 0 "not replaced in this frame" 1 "replaced in this frame";
VAL_ 1171 ObstacleMotionCategory_493h 0 "INVALID" 1 "UNDEFINED" 2 "PASSING" 3 "PASSING_IN" 4 "PASSING_OUT" 5 "CLOSE_CUT_IN" 6 "MOVING_IN" 7 "MOVING_OUT" 8 "CROSSING" 9 "LTAP" 10 "RTAP" 11 "MOVING" 12 "PRECEEDING" 13 "ONCOMING";
VAL_ 1171 ObstacleMotionStatus_493h 0 "INVALID" 1 "UNKNOWN" 2 "MOVING" 3 "STATIONARY" 4 "STOPPED" 5 "MOVING SLOWLY";
VAL_ 1171 ObstacleMeasuringStatus_493h 0 "INVALID" 1 "MEASURED" 2 "PREDICTED";
VAL_ 1171 ObstacleClass_493h 0 "INVALID" 1 "VEHICLE" 2 "PEDESTRIAN" 3 "CYCLIST" 4 "GENERAL_OBJECT";
VAL_ 1171 VehicleSubType_493h 0 "Unknown" 1 "Bus" 2 "Small_Medium_Car" 3 "Trucks" 4 "Motors(Tri-cycle)" 5 "Special_vehicle" 6 "Tiny_car" 7 "Lorry";
VAL_ 1171 PedSubType_493h 0 "Unknown" 1 "Adult" 2 "Child";
VAL_ 1171 PedPos_493h 0 "Unknown" 1 "Bended" 2 "Cyclist" 3 "Lier" 4 "Pedestrian" 5 "Sitter";
VAL_ 1171 PedOrientation_493h 0 "Unknown" 1 "back" 2 "front" 3 "left" 4 "left_anterior" 5 "left_back" 6 "right" 7 "right_front" 8 "right_back";
VAL_ 1171 ObstacleLaneAssignment_493h 0 "UNKNOWN" 1 "LEFT_LEFT" 2 "LEFT" 3 "HOST" 4 "RIGHT" 5 "RIGHT_RIGHT";
VAL_ 1172 CIPVFlag_494h 0 "not CIPV" 1 "CIPV";
VAL_ 1172 MCPFlag_494h 0 "not MCP" 1 "MCP";
VAL_ 1172 ObstacleBlinkerInfo_494h 0 "Unavailable" 1 "Off" 2 "Left" 3 "Right" 4 "Both";
VAL_ 1172 ObstacleBrakeLights_494h 0 "OFF" 1 "ON";
VAL_ 1172 ObstaclePositionType_494h 0 "Unknown" 1 "RearLeft" 2 "RearCenter" 3 "RearRight" 4 "FrontLeft" 5 "FrontCenter" 6 "FrontRight" 7 "LeftCenter" 8 "RightCenter" 9 "Center";
VAL_ 1172 CutInFlag_494h 0 "not Cut In" 1 "Cut In" 2 "Close Cut In";
VAL_ 1181 ObstacleValid_49Dh 0 "invalid Obstacle(default value)" 1 "new valid (detected this frame)" 2 "older valid";
VAL_ 1181 ObstacleReplaced_49Dh 0 "not replaced in this frame" 1 "replaced in this frame";
VAL_ 1181 ObstacleMotionCategory_49Dh 0 "INVALID" 1 "UNDEFINED" 2 "PASSING" 3 "PASSING_IN" 4 "PASSING_OUT" 5 "CLOSE_CUT_IN" 6 "MOVING_IN" 7 "MOVING_OUT" 8 "CROSSING" 9 "LTAP" 10 "RTAP" 11 "MOVING" 12 "PRECEEDING" 13 "ONCOMING";
VAL_ 1181 ObstacleMotionStatus_49Dh 0 "INVALID" 1 "UNKNOWN" 2 "MOVING" 3 "STATIONARY" 4 "STOPPED" 5 "MOVING SLOWLY";
VAL_ 1181 ObstacleMeasuringStatus_49Dh 0 "INVALID" 1 "MEASURED" 2 "PREDICTED";
VAL_ 1181 ObstacleClass_49Dh 0 "INVALID" 1 "VEHICLE" 2 "PEDESTRIAN" 3 "CYCLIST" 4 "GENERAL_OBJECT";
VAL_ 1181 VehicleSubType_49Dh 0 "Unknown" 1 "Bus" 2 "Small_Medium_Car" 3 "Trucks" 4 "Motors(Tri-cycle)" 5 "Special_vehicle" 6 "Tiny_car" 7 "Lorry";
VAL_ 1181 PedSubType_49Dh 0 "Unknown" 1 "Adult" 2 "Child";
VAL_ 1181 PedPos_49Dh 0 "Unknown" 1 "Bended" 2 "Cyclist" 3 "Lier" 4 "Pedestrian" 5 "Sitter";
VAL_ 1181 PedOrientation_49Dh 0 "Unknown" 1 "back" 2 "front" 3 "left" 4 "left_anterior" 5 "left_back" 6 "right" 7 "right_front" 8 "right_back";
VAL_ 1181 ObstacleLaneAssignment_49Dh 0 "UNKNOWN" 1 "LEFT_LEFT" 2 "LEFT" 3 "HOST" 4 "RIGHT" 5 "RIGHT_RIGHT";
VAL_ 1182 CIPVFlag_49Eh 0 "not CIPV" 1 "CIPV";
VAL_ 1182 MCPFlag_49Eh 0 "not MCP" 1 "MCP";
VAL_ 1182 ObstacleBlinkerInfo_49Eh 0 "Unavailable" 1 "Off" 2 "Left" 3 "Right" 4 "Both";
VAL_ 1182 ObstacleBrakeLights_49Eh 0 "OFF" 1 "ON";
VAL_ 1182 ObstaclePositionType_49Eh 0 "Unknown" 1 "RearLeft" 2 "RearCenter" 3 "RearRight" 4 "FrontLeft" 5 "FrontCenter" 6 "FrontRight" 7 "LeftCenter" 8 "RightCenter" 9 "Center";
VAL_ 1182 CutInFlag_49Eh 0 "not Cut In" 1 "Cut In" 2 "Close Cut In";
VAL_ 1191 ObstacleValid_4A7h 0 "invalid Obstacle(default value)" 1 "new valid (detected this frame)" 2 "older valid";
VAL_ 1191 ObstacleReplaced_4A7h 0 "not replaced in this frame" 1 "replaced in this frame";
VAL_ 1191 ObstacleMotionCategory_4A7h 0 "INVALID" 1 "UNDEFINED" 2 "PASSING" 3 "PASSING_IN" 4 "PASSING_OUT" 5 "CLOSE_CUT_IN" 6 "MOVING_IN" 7 "MOVING_OUT" 8 "CROSSING" 9 "LTAP" 10 "RTAP" 11 "MOVING" 12 "PRECEEDING" 13 "ONCOMING";
VAL_ 1191 ObstacleMotionStatus_4A7h 0 "INVALID" 1 "UNKNOWN" 2 "MOVING" 3 "STATIONARY" 4 "STOPPED" 5 "MOVING SLOWLY";
VAL_ 1191 ObstacleMeasuringStatus_4A7h 0 "INVALID" 1 "MEASURED" 2 "PREDICTED";
VAL_ 1191 ObstacleClass_4A7h 0 "INVALID" 1 "VEHICLE" 2 "PEDESTRIAN" 3 "CYCLIST" 4 "GENERAL_OBJECT";
VAL_ 1191 VehicleSubType_4A7h 0 "Unknown" 1 "Bus" 2 "Small_Medium_Car" 3 "Trucks" 4 "Motors(Tri-cycle)" 5 "Special_vehicle" 6 "Tiny_car" 7 "Lorry";
VAL_ 1191 PedSubType_4A7h 0 "Unknown" 1 "Adult" 2 "Child";
VAL_ 1191 PedPos_4A7h 0 "Unknown" 1 "Bended" 2 "Cyclist" 3 "Lier" 4 "Pedestrian" 5 "Sitter";
VAL_ 1191 PedOrientation_4A7h 0 "Unknown" 1 "back" 2 "front" 3 "left" 4 "left_anterior" 5 "left_back" 6 "right" 7 "right_front" 8 "right_back";
VAL_ 1191 ObstacleLaneAssignment_4A7h 0 "UNKNOWN" 1 "LEFT_LEFT" 2 "LEFT" 3 "HOST" 4 "RIGHT" 5 "RIGHT_RIGHT";
VAL_ 1192 CIPVFlag_4A8h 0 "not CIPV" 1 "CIPV";
VAL_ 1192 MCPFlag_4A8h 0 "not MCP" 1 "MCP";
VAL_ 1192 ObstacleBlinkerInfo_4A8h 0 "Unavailable" 1 "Off" 2 "Left" 3 "Right" 4 "Both";
VAL_ 1192 ObstacleBrakeLights_4A8h 0 "OFF" 1 "ON";
VAL_ 1192 ObstaclePositionType_4A8h 0 "Unknown" 1 "RearLeft" 2 "RearCenter" 3 "RearRight" 4 "FrontLeft" 5 "FrontCenter" 6 "FrontRight" 7 "LeftCenter" 8 "RightCenter" 9 "Center";
VAL_ 1192 CutInFlag_4A8h 0 "not Cut In" 1 "Cut In" 2 "Close Cut In";
VAL_ 1201 ObstacleValid_4B1h 0 "invalid Obstacle(default value)" 1 "new valid (detected this frame)" 2 "older valid";
VAL_ 1201 ObstacleReplaced_4B1h 0 "not replaced in this frame" 1 "replaced in this frame";
VAL_ 1201 ObstacleMotionCategory_4B1h 0 "INVALID" 1 "UNDEFINED" 2 "PASSING" 3 "PASSING_IN" 4 "PASSING_OUT" 5 "CLOSE_CUT_IN" 6 "MOVING_IN" 7 "MOVING_OUT" 8 "CROSSING" 9 "LTAP" 10 "RTAP" 11 "MOVING" 12 "PRECEEDING" 13 "ONCOMING";
VAL_ 1201 ObstacleMotionStatus_4B1h 0 "INVALID" 1 "UNKNOWN" 2 "MOVING" 3 "STATIONARY" 4 "STOPPED" 5 "MOVING SLOWLY";
VAL_ 1201 ObstacleMeasuringStatus_4B1h 0 "INVALID" 1 "MEASURED" 2 "PREDICTED";
VAL_ 1201 ObstacleClass_4B1h 0 "INVALID" 1 "VEHICLE" 2 "PEDESTRIAN" 3 "CYCLIST" 4 "GENERAL_OBJECT";
VAL_ 1201 VehicleSubType_4B1h 0 "Unknown" 1 "Bus" 2 "Small_Medium_Car" 3 "Trucks" 4 "Motors(Tri-cycle)" 5 "Special_vehicle" 6 "Tiny_car" 7 "Lorry";
VAL_ 1201 PedSubType_4B1h 0 "Unknown" 1 "Adult" 2 "Child";
VAL_ 1201 PedPos_4B1h 0 "Unknown" 1 "Bended" 2 "Cyclist" 3 "Lier" 4 "Pedestrian" 5 "Sitter";
VAL_ 1201 PedOrientation_4B1h 0 "Unknown" 1 "back" 2 "front" 3 "left" 4 "left_anterior" 5 "left_back" 6 "right" 7 "right_front" 8 "right_back";
VAL_ 1201 ObstacleLaneAssignment_4B1h 0 "UNKNOWN" 1 "LEFT_LEFT" 2 "LEFT" 3 "HOST" 4 "RIGHT" 5 "RIGHT_RIGHT";
VAL_ 1202 CIPVFlag_4B2h 0 "not CIPV" 1 "CIPV";
VAL_ 1202 MCPFlag_4B2h 0 "not MCP" 1 "MCP";
VAL_ 1202 ObstacleBlinkerInfo_4B2h 0 "Unavailable" 1 "Off" 2 "Left" 3 "Right" 4 "Both";
VAL_ 1202 ObstacleBrakeLights_4B2h 0 "OFF" 1 "ON";
VAL_ 1202 ObstaclePositionType_4B2h 0 "Unknown" 1 "RearLeft" 2 "RearCenter" 3 "RearRight" 4 "FrontLeft" 5 "FrontCenter" 6 "FrontRight" 7 "LeftCenter" 8 "RightCenter" 9 "Center";
VAL_ 1202 CutInFlag_4B2h 0 "not Cut In" 1 "Cut In" 2 "Close Cut In";
VAL_ 1211 ObstacleValid_4BBh 0 "invalid Obstacle(default value)" 1 "new valid (detected this frame)" 2 "older valid";
VAL_ 1211 ObstacleReplaced_4BBh 0 "not replaced in this frame" 1 "replaced in this frame";
VAL_ 1211 ObstacleMotionCategory_4BBh 0 "INVALID" 1 "UNDEFINED" 2 "PASSING" 3 "PASSING_IN" 4 "PASSING_OUT" 5 "CLOSE_CUT_IN" 6 "MOVING_IN" 7 "MOVING_OUT" 8 "CROSSING" 9 "LTAP" 10 "RTAP" 11 "MOVING" 12 "PRECEEDING" 13 "ONCOMING";
VAL_ 1211 ObstacleMotionStatus_4BBh 0 "INVALID" 1 "UNKNOWN" 2 "MOVING" 3 "STATIONARY" 4 "STOPPED" 5 "MOVING SLOWLY";
VAL_ 1211 ObstacleMeasuringStatus_4BBh 0 "INVALID" 1 "MEASURED" 2 "PREDICTED";
VAL_ 1211 ObstacleClass_4BBh 0 "INVALID" 1 "VEHICLE" 2 "PEDESTRIAN" 3 "CYCLIST" 4 "GENERAL_OBJECT";
VAL_ 1211 VehicleSubType_4BBh 0 "Unknown" 1 "Bus" 2 "Small_Medium_Car" 3 "Trucks" 4 "Motors(Tri-cycle)" 5 "Special_vehicle" 6 "Tiny_car" 7 "Lorry";
VAL_ 1211 PedSubType_4BBh 0 "Unknown" 1 "Adult" 2 "Child";
VAL_ 1211 PedPos_4BBh 0 "Unknown" 1 "Bended" 2 "Cyclist" 3 "Lier" 4 "Pedestrian" 5 "Sitter";
VAL_ 1211 PedOrientation_4BBh 0 "Unknown" 1 "back" 2 "front" 3 "left" 4 "left_anterior" 5 "left_back" 6 "right" 7 "right_front" 8 "right_back";
VAL_ 1211 ObstacleLaneAssignment_4BBh 0 "UNKNOWN" 1 "LEFT_LEFT" 2 "LEFT" 3 "HOST" 4 "RIGHT" 5 "RIGHT_RIGHT";
